VERSION ""

NS_ :

BS_:

BU_: L_DHRR_FD L_UWB_BLE_MST_FD L_UWB_RR_FD L_UWB_BLE_SLV_FD L_UWB_FR_FD L_ROA_FR_FD L_ROA_FD L_DHRL_FD L_UWB_TRNK_FD L_EDT_FD L_UWB_FRNK_FD L_UWB_FL_FD GW_BDC_FD L_UWB_RL_FD L_SAL_FD L_WPC_FD L_TPMS_FD L_DHL_FD L_DHR_FD

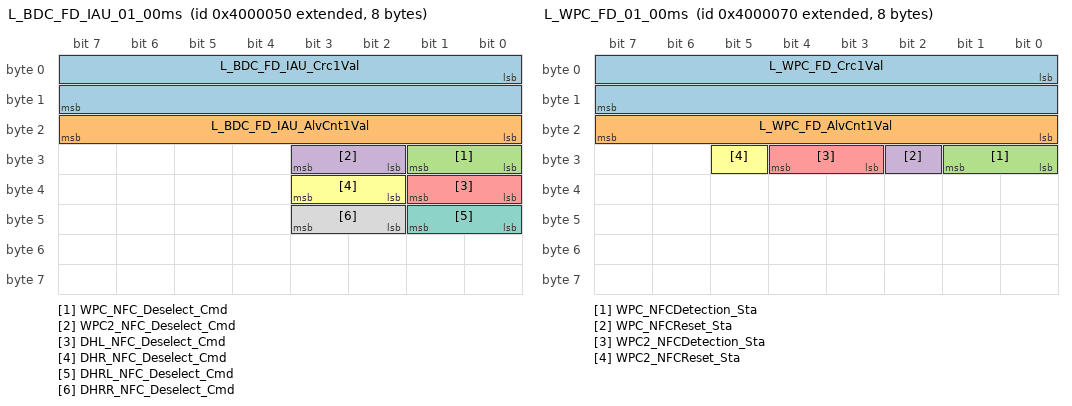
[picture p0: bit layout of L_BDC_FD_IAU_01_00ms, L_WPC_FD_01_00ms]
BO_ 2214592592 L_BDC_FD_IAU_01_00ms: 8 GW_BDC_FD
 SG_ L_BDC_FD_IAU_Crc1Val : 0|16@1+ (1,0) [0|0] "0"  Vector__XXX
 SG_ L_BDC_FD_IAU_AlvCnt1Val : 16|8@1+ (1,0) [0|0] "0"  Vector__XXX
 SG_ WPC_NFC_Deselect_Cmd : 24|2@1+ (1,0) [0|0] ""  L_WPC_FD
 SG_ WPC2_NFC_Deselect_Cmd : 26|2@1+ (1,0) [0|0] ""  L_WPC_FD
 SG_ DHL_NFC_Deselect_Cmd : 32|2@1+ (1,0) [0|0] ""  L_DHL_FD
 SG_ DHR_NFC_Deselect_Cmd : 34|2@1+ (1,0) [0|0] ""  L_DHR_FD
 SG_ DHRL_NFC_Deselect_Cmd : 40|2@1+ (1,0) [0|0] ""  L_DHRL_FD
 SG_ DHRR_NFC_Deselect_Cmd : 42|2@1+ (1,0) [0|0] ""  L_DHRR_FD

BO_ 850 IAU_FD_05_200ms: 32 GW_BDC_FD
 SG_ IAU_FD_Crc5Val : 0|16@1+ (1,0) [0|0] ""  Vector__XXX
 SG_ IAU_DigitalKeyProfileRval : 112|4@1+ (1,0) [0|0] ""  Vector__XXX
 SG_ IAU_SharedPhnRegStat : 116|2@1+ (1,0) [0|0] ""  L_DHL_FD,L_DHRL_FD,L_DHRR_FD,L_DHR_FD,L_UWB_BLE_MST_FD,L_UWB_BLE_SLV_FD,L_UWB_FL_FD,L_UWB_FRNK_FD,L_UWB_FR_FD,L_UWB_RL_FD,L_UWB_RR_FD,L_UWB_TRNK_FD,L_WPC_FD
 SG_ IAU_CardKeyEnblRVal : 118|2@1+ (1,0) [0|0] ""  L_DHL_FD,L_DHRL_FD,L_DHRR_FD,L_DHR_FD
 SG_ IAU_DrvDHLPhnDetect : 120|2@1+ (1,0) [0|0] ""  Vector__XXX
 SG_ IAU_AstDHLPhnDetect : 122|2@1+ (1,0) [0|0] ""  Vector__XXX
 SG_ IAU_RLDHLPhnDetect : 124|2@1+ (1,0) [0|0] ""  Vector__XXX
 SG_ IAU_RRDHLPhnDetect : 126|2@1+ (1,0) [0|0] ""  Vector__XXX
 SG_ IAU_Manufacturer : 128|8@1+ (1,0) [0|0] ""  Vector__XXX
 SG_ IAU_VendorCode : 136|24@1+ (1,0) [0|0] ""  Vector__XXX
 SG_ IAU_FD_AlvCnt5Val : 16|8@1+ (1,0) [0|0] ""  Vector__XXX
 SG_ IAU_Serial : 160|32@1+ (1,0) [0|0] ""  Vector__XXX
 SG_ IAU_Year : 192|16@1+ (1,0) [0|0] ""  Vector__XXX
 SG_ IAU_Month : 208|8@1+ (1,0) [0|0] ""  Vector__XXX
 SG_ IAU_Date : 216|16@1+ (1,0) [0|0] ""  Vector__XXX
 SG_ IAU_SWVerMajor1 : 232|7@1+ (1,0) [0|0] ""  Vector__XXX
 SG_ IAU_DrvDhsRainStat : 24|1@1+ (1,0) [0|0] ""  Vector__XXX
 SG_ IAU_SWVerMinor1 : 240|7@1+ (1,0) [0|0] ""  Vector__XXX
 SG_ IAU_SWVerMinor2 : 248|7@1+ (1,0) [0|0] ""  Vector__XXX
 SG_ IAU_AstDhsRainStat : 25|1@1+ (1,0) [0|0] ""  Vector__XXX
 SG_ IAU_RLDhsRainStat : 26|1@1+ (1,0) [0|0] ""  Vector__XXX
 SG_ IAU_RRDhsRainStat : 27|1@1+ (1,0) [0|0] ""  Vector__XXX

BO_ 745 PDC_FD_15_300ms: 32 GW_BDC_FD
 SG_ PDC_FD_Crc15Val : 0|16@1+ (1,0) [0|0] ""  L_DHL_FD,L_DHRL_FD,L_DHRR_FD,L_DHR_FD,L_EDT_FD,L_ROA_FD,L_ROA_FR_FD,L_SAL_FD,L_TPMS_FD,L_UWB_BLE_MST_FD,L_UWB_BLE_SLV_FD,L_UWB_FL_FD,L_UWB_FRNK_FD,L_UWB_FR_FD,L_UWB_RL_FD,L_UWB_RR_FD,L_UWB_TRNK_FD,L_WPC_FD
 SG_ PDC_CurrAtReset : 104|12@1+ (10,-40940) [-40940|0] "mA"  Vector__XXX
 SG_ PDC_AvgCurrAtReset : 120|12@1+ (10,-40940) [-40940|0] "mA"  Vector__XXX
 SG_ PDC_ResetReason : 132|3@1+ (1,0) [0|0] ""  Vector__XXX
 SG_ PDC_CumulativeCountOf12VReq : 136|10@1+ (1,0) [0|0] ""  Vector__XXX
 SG_ PDC_CumulativeCountOfCCUReq : 146|10@1+ (1,0) [0|0] ""  Vector__XXX
 SG_ PDC_FD_AlvCnt15Val : 16|8@1+ (1,0) [0|0] ""  L_DHL_FD,L_DHRL_FD,L_DHRR_FD,L_DHR_FD,L_EDT_FD,L_ROA_FD,L_ROA_FR_FD,L_SAL_FD,L_TPMS_FD,L_UWB_BLE_MST_FD,L_UWB_BLE_SLV_FD,L_UWB_FL_FD,L_UWB_FRNK_FD,L_UWB_FR_FD,L_UWB_RL_FD,L_UWB_RR_FD,L_UWB_TRNK_FD,L_WPC_FD
 SG_ PDC_LDConReq : 184|2@1+ (1,0) [0|0] ""  Vector__XXX
 SG_ PDC_LDConReq_By_LVBat : 186|2@1+ (1,0) [0|0] ""  Vector__XXX
 SG_ PDC_LDConReq_By_OTA : 188|2@1+ (1,0) [0|0] ""  Vector__XXX
 SG_ PDC_LDConReq_By_Load : 190|2@1+ (1,0) [0|0] ""  Vector__XXX
 SG_ PDC_LDConReq_By_ActiveOn : 192|2@1+ (1,0) [0|0] ""  Vector__XXX
 SG_ PDC_ResetPreWrngForCCU : 40|2@1+ (1,0) [0|0] ""  Vector__XXX
 SG_ PDC_ResetPreWrngForOthers : 42|2@1+ (1,0) [0|0] ""  L_DHL_FD,L_DHRL_FD,L_DHRR_FD,L_DHR_FD,L_EDT_FD,L_ROA_FD,L_ROA_FR_FD,L_SAL_FD,L_TPMS_FD,L_UWB_BLE_MST_FD,L_UWB_BLE_SLV_FD,L_UWB_FL_FD,L_UWB_FRNK_FD,L_UWB_FR_FD,L_UWB_RL_FD,L_UWB_RR_FD,L_UWB_TRNK_FD,L_WPC_FD
 SG_ PDC_ResetReqForCCU : 44|2@1+ (1,0) [0|0] ""  Vector__XXX
 SG_ PDC_ResetReqForOthers : 46|2@1+ (1,0) [0|0] ""  L_DHL_FD,L_DHRL_FD,L_DHRR_FD,L_DHR_FD,L_EDT_FD,L_ROA_FD,L_ROA_FR_FD,L_SAL_FD,L_TPMS_FD,L_UWB_BLE_MST_FD,L_UWB_BLE_SLV_FD,L_UWB_FL_FD,L_UWB_FRNK_FD,L_UWB_FR_FD,L_UWB_RL_FD,L_UWB_RR_FD,L_UWB_TRNK_FD,L_WPC_FD
 SG_ PDC_ResetFuncOpt : 48|2@1+ (1,0) [0|0] ""  L_ROA_FD,L_ROA_FR_FD,L_TPMS_FD,L_UWB_BLE_MST_FD,L_UWB_BLE_SLV_FD,L_UWB_FL_FD,L_UWB_FRNK_FD,L_UWB_FR_FD,L_UWB_RL_FD,L_UWB_RR_FD,L_UWB_TRNK_FD
 SG_ PDC_12VRlyCtrl : 50|2@1+ (1,0) [0|0] ""  Vector__XXX
 SG_ PDC_CurrentValueForReset : 52|8@1+ (50,0) [0|0] "mA"  Vector__XXX
 SG_ PDC_TimeValueForReset : 64|8@1+ (0.5,0) [0|0] "h"  Vector__XXX
 SG_ PDC_12VRlyOffHoldingTime : 72|5@1+ (0.5,0) [0|0] "s"  Vector__XXX
 SG_ PDC_ResetCountSetting : 77|2@1+ (1,0) [0|0] ""  Vector__XXX
 SG_ PDC_ResetCount : 79|2@1+ (1,0) [0|0] ""  Vector__XXX
 SG_ PDC_ResetCumulativeCount : 81|10@1+ (1,0) [0|0] ""  Vector__XXX
 SG_ PDC_ResetOpsta : 91|2@1+ (1,0) [0|0] ""  Vector__XXX
 SG_ PDC_ReadyTimeValueForReset : 96|8@1+ (10,0) [0|255] "Min"  Vector__XXX

BO_ 849 IAU_FD_04_200ms: 32 GW_BDC_FD
 SG_ IAU_FD_Crc4Val : 0|16@1+ (1,0) [0|0] "0"  Vector__XXX
 SG_ IAU_DISPWrng : 104|4@1+ (1,0) [0|0] ""  Vector__XXX
 SG_ IAU_DigitalKey2Opt : 120|3@1+ (1,0) [0|0] ""  Vector__XXX
 SG_ IAUwFRULearnState : 124|2@1+ (1,0) [0|0] ""  Vector__XXX
 SG_ IAUwFPMLearnState : 126|2@1+ (1,0) [0|0] ""  Vector__XXX
 SG_ IAU_ValetDigitalkey : 128|2@1+ (1,0) [0|0] ""  Vector__XXX
 SG_ IAU_DigitalKeyNumberOpt : 130|3@1+ (1,0) [0|0] ""  Vector__XXX
 SG_ IAU_eSEReprogramSta : 133|2@1+ (1,0) [0|0] ""  Vector__XXX
 SG_ IAU_DKOwnerSwapOption : 136|2@1+ (1,0) [0|0] ""  L_UWB_BLE_MST_FD,L_UWB_BLE_SLV_FD,L_UWB_FL_FD,L_UWB_FRNK_FD,L_UWB_FR_FD,L_UWB_RL_FD,L_UWB_RR_FD,L_UWB_TRNK_FD,L_WPC_FD
 SG_ IAU_DgtKeyGrpPrflRval2 : 139|5@1+ (1,0) [0|0] ""  Vector__XXX
 SG_ IAU_StartIdentifiedProfile : 144|3@1+ (1,0) [0|0] ""  Vector__XXX
 SG_ IAU_DigitalKeyProfileRval2 : 147|5@1+ (1,0) [0|0] ""  Vector__XXX
 SG_ IAU_NFCCard1SN : 152|32@1+ (1,0) [0|0] ""  Vector__XXX
 SG_ IAU_FD_AlvCnt4Val : 16|8@1+ (1,0) [0|0] "0"  Vector__XXX
 SG_ IAU_StartIdentifiedProfile_Ext : 24|4@1+ (1,0) [0|0] ""  Vector__XXX
 SG_ RSPA_UWBRspaExtRngSta : 246|2@1+ (1,0) [0|0] ""  Vector__XXX
 SG_ RSPA_CanFltSta : 250|2@1+ (1,0) [0|0] ""  Vector__XXX
 SG_ RSPA_BLESigErrSta : 252|2@1+ (1,0) [0|0] ""  Vector__XXX
 SG_ RSPA_ConStat : 254|2@1+ (1,0) [0|0] ""  Vector__XXX
 SG_ IAU_ProfileIDRVal : 74|4@1+ (1,0) [0|0] ""  Vector__XXX
 SG_ IAU_DigitalKeyProcessingSta : 80|4@1+ (1,0) [0|0] ""  Vector__XXX
 SG_ IAU_DigitalKeyExit : 84|4@1+ (1,0) [0|0] ""  Vector__XXX
 SG_ IAU_DigitalKeyEnblRVal : 88|2@1+ (1,0) [0|0] ""  L_DHL_FD,L_DHRL_FD,L_DHRR_FD,L_DHR_FD,L_UWB_BLE_MST_FD,L_UWB_BLE_SLV_FD,L_UWB_FL_FD,L_UWB_FRNK_FD,L_UWB_FR_FD,L_UWB_RL_FD,L_UWB_RR_FD,L_UWB_TRNK_FD
 SG_ IAU_OwnerPhnRegRVal : 90|2@1+ (1,0) [0|0] ""  L_DHL_FD,L_DHRL_FD,L_DHRR_FD,L_DHR_FD,L_UWB_BLE_MST_FD,L_UWB_BLE_SLV_FD,L_UWB_FL_FD,L_UWB_FRNK_FD,L_UWB_FR_FD,L_UWB_RL_FD,L_UWB_RR_FD,L_UWB_TRNK_FD,L_WPC_FD
 SG_ IAU_NFCCard1RegRVal : 92|2@1+ (1,0) [0|0] ""  Vector__XXX
 SG_ IAU_NFCCard2RegRVal : 94|2@1+ (1,0) [0|0] ""  Vector__XXX

BO_ 2214592624 L_WPC_FD_01_00ms: 8 L_WPC_FD
 SG_ L_WPC_FD_Crc1Val : 0|16@1+ (1,0) [0|0] "0"  Vector__XXX
 SG_ L_WPC_FD_AlvCnt1Val : 16|8@1+ (1,0) [0|0] "0"  Vector__XXX
 SG_ WPC_NFCDetection_Sta : 24|2@1+ (1,0) [0|0] ""  GW_BDC_FD
 SG_ WPC_NFCReset_Sta : 26|1@1+ (1,0) [0|0] ""  GW_BDC_FD
 SG_ WPC2_NFCDetection_Sta : 27|2@1+ (1,0) [0|0] ""  GW_BDC_FD
 SG_ WPC2_NFCReset_Sta : 29|1@1+ (1,0) [0|0] ""  GW_BDC_FD

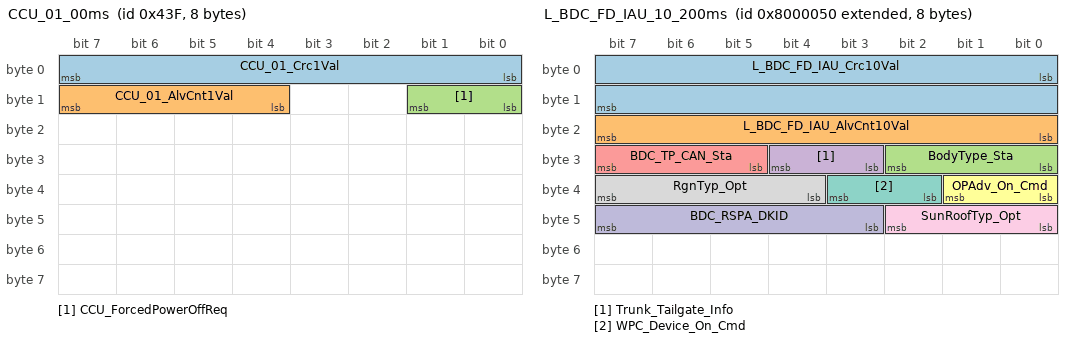
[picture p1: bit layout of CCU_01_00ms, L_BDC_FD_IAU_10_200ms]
BO_ 1087 CCU_01_00ms: 8 GW_BDC_FD
 SG_ CCU_01_Crc1Val : 0|8@1+ (1,0) [0|0] ""  Vector__XXX
 SG_ CCU_01_AlvCnt1Val : 12|4@1+ (1,0) [0|0] ""  Vector__XXX
 SG_ CCU_ForcedPowerOffReq : 8|2@1+ (1,0) [0|0] ""  L_DHL_FD,L_DHRL_FD,L_DHRR_FD,L_DHR_FD,L_ROA_FD,L_ROA_FR_FD,L_SAL_FD,L_TPMS_FD,L_UWB_BLE_MST_FD,L_UWB_BLE_SLV_FD,L_UWB_FL_FD,L_UWB_FRNK_FD,L_UWB_FR_FD,L_UWB_RL_FD,L_UWB_RR_FD,L_UWB_TRNK_FD,L_WPC_FD

BO_ 2348810501 L_TP_L_WPC_FD_BDC_FD: 32 L_WPC_FD
 SG_ L_TP_L_WPC_FD_BDC_FD_Byte0 : 0|8@1+ (1,0) [0|0] ""  GW_BDC_FD
 SG_ L_TP_L_WPC_FD_BDC_FD_Byte13 : 104|8@1+ (1,0) [0|0] ""  GW_BDC_FD
 SG_ L_TP_L_WPC_FD_BDC_FD_Byte14 : 112|8@1+ (1,0) [0|0] ""  GW_BDC_FD
 SG_ L_TP_L_WPC_FD_BDC_FD_Byte15 : 120|8@1+ (1,0) [0|0] ""  GW_BDC_FD
 SG_ L_TP_L_WPC_FD_BDC_FD_Byte16 : 128|8@1+ (1,0) [0|0] ""  GW_BDC_FD
 SG_ L_TP_L_WPC_FD_BDC_FD_Byte17 : 136|8@1+ (1,0) [0|0] ""  GW_BDC_FD
 SG_ L_TP_L_WPC_FD_BDC_FD_Byte18 : 144|8@1+ (1,0) [0|0] ""  GW_BDC_FD
 SG_ L_TP_L_WPC_FD_BDC_FD_Byte19 : 152|8@1+ (1,0) [0|0] ""  GW_BDC_FD
 SG_ L_TP_L_WPC_FD_BDC_FD_Byte2 : 16|8@1+ (1,0) [0|0] ""  GW_BDC_FD
 SG_ L_TP_L_WPC_FD_BDC_FD_Byte20 : 160|8@1+ (1,0) [0|0] ""  GW_BDC_FD
 SG_ L_TP_L_WPC_FD_BDC_FD_Byte21 : 168|8@1+ (1,0) [0|0] ""  GW_BDC_FD
 SG_ L_TP_L_WPC_FD_BDC_FD_Byte22 : 176|8@1+ (1,0) [0|0] ""  GW_BDC_FD
 SG_ L_TP_L_WPC_FD_BDC_FD_Byte23 : 184|8@1+ (1,0) [0|0] ""  GW_BDC_FD
 SG_ L_TP_L_WPC_FD_BDC_FD_Byte24 : 192|8@1+ (1,0) [0|0] ""  GW_BDC_FD
 SG_ L_TP_L_WPC_FD_BDC_FD_Byte25 : 200|8@1+ (1,0) [0|0] ""  GW_BDC_FD
 SG_ L_TP_L_WPC_FD_BDC_FD_Byte26 : 208|8@1+ (1,0) [0|0] ""  GW_BDC_FD
 SG_ L_TP_L_WPC_FD_BDC_FD_Byte27 : 216|8@1+ (1,0) [0|0] ""  GW_BDC_FD
 SG_ L_TP_L_WPC_FD_BDC_FD_Byte28 : 224|8@1+ (1,0) [0|0] ""  GW_BDC_FD
 SG_ L_TP_L_WPC_FD_BDC_FD_Byte29 : 232|8@1+ (1,0) [0|0] ""  GW_BDC_FD
 SG_ L_TP_L_WPC_FD_BDC_FD_Byte3 : 24|8@1+ (1,0) [0|0] ""  GW_BDC_FD
 SG_ L_TP_L_WPC_FD_BDC_FD_Byte30 : 240|8@1+ (1,0) [0|0] ""  GW_BDC_FD
 SG_ L_TP_L_WPC_FD_BDC_FD_Byte31 : 248|8@1+ (1,0) [0|0] ""  GW_BDC_FD
 SG_ L_TP_L_WPC_FD_BDC_FD_Byte4 : 32|8@1+ (1,0) [0|0] ""  GW_BDC_FD
 SG_ L_TP_L_WPC_FD_BDC_FD_Byte5 : 40|8@1+ (1,0) [0|0] ""  GW_BDC_FD
 SG_ L_TP_L_WPC_FD_BDC_FD_Byte6 : 48|8@1+ (1,0) [0|0] ""  GW_BDC_FD
 SG_ L_TP_L_WPC_FD_BDC_FD_Byte7 : 56|8@1+ (1,0) [0|0] ""  GW_BDC_FD
 SG_ L_TP_L_WPC_FD_BDC_FD_Byte8 : 64|8@1+ (1,0) [0|0] ""  GW_BDC_FD
 SG_ L_TP_L_WPC_FD_BDC_FD_Byte9 : 72|8@1+ (1,0) [0|0] ""  GW_BDC_FD
 SG_ L_TP_L_WPC_FD_BDC_FD_Byte1 : 8|8@1+ (1,0) [0|0] ""  GW_BDC_FD
 SG_ L_TP_L_WPC_FD_BDC_FD_Byte10 : 80|8@1+ (1,0) [0|0] ""  GW_BDC_FD
 SG_ L_TP_L_WPC_FD_BDC_FD_Byte11 : 88|8@1+ (1,0) [0|0] ""  GW_BDC_FD
 SG_ L_TP_L_WPC_FD_BDC_FD_Byte12 : 96|8@1+ (1,0) [0|0] ""  GW_BDC_FD

BO_ 2348810500 L_TP_BDC_FD_L_WPC_FD: 32 GW_BDC_FD
 SG_ L_TP_BDC_FD_L_WPC_FD_Byte0 : 0|8@1+ (1,0) [0|0] ""  L_WPC_FD
 SG_ L_TP_BDC_FD_L_WPC_FD_Byte13 : 104|8@1+ (1,0) [0|0] ""  L_WPC_FD
 SG_ L_TP_BDC_FD_L_WPC_FD_Byte14 : 112|8@1+ (1,0) [0|0] ""  L_WPC_FD
 SG_ L_TP_BDC_FD_L_WPC_FD_Byte15 : 120|8@1+ (1,0) [0|0] ""  L_WPC_FD
 SG_ L_TP_BDC_FD_L_WPC_FD_Byte16 : 128|8@1+ (1,0) [0|0] ""  L_WPC_FD
 SG_ L_TP_BDC_FD_L_WPC_FD_Byte17 : 136|8@1+ (1,0) [0|0] ""  L_WPC_FD
 SG_ L_TP_BDC_FD_L_WPC_FD_Byte18 : 144|8@1+ (1,0) [0|0] ""  L_WPC_FD
 SG_ L_TP_BDC_FD_L_WPC_FD_Byte19 : 152|8@1+ (1,0) [0|0] ""  L_WPC_FD
 SG_ L_TP_BDC_FD_L_WPC_FD_Byte2 : 16|8@1+ (1,0) [0|0] ""  L_WPC_FD
 SG_ L_TP_BDC_FD_L_WPC_FD_Byte20 : 160|8@1+ (1,0) [0|0] ""  L_WPC_FD
 SG_ L_TP_BDC_FD_L_WPC_FD_Byte21 : 168|8@1+ (1,0) [0|0] ""  L_WPC_FD
 SG_ L_TP_BDC_FD_L_WPC_FD_Byte22 : 176|8@1+ (1,0) [0|0] ""  L_WPC_FD
 SG_ L_TP_BDC_FD_L_WPC_FD_Byte23 : 184|8@1+ (1,0) [0|0] ""  L_WPC_FD
 SG_ L_TP_BDC_FD_L_WPC_FD_Byte24 : 192|8@1+ (1,0) [0|0] ""  L_WPC_FD
 SG_ L_TP_BDC_FD_L_WPC_FD_Byte25 : 200|8@1+ (1,0) [0|0] ""  L_WPC_FD
 SG_ L_TP_BDC_FD_L_WPC_FD_Byte26 : 208|8@1+ (1,0) [0|0] ""  L_WPC_FD
 SG_ L_TP_BDC_FD_L_WPC_FD_Byte27 : 216|8@1+ (1,0) [0|0] ""  L_WPC_FD
 SG_ L_TP_BDC_FD_L_WPC_FD_Byte28 : 224|8@1+ (1,0) [0|0] ""  L_WPC_FD
 SG_ L_TP_BDC_FD_L_WPC_FD_Byte29 : 232|8@1+ (1,0) [0|0] ""  L_WPC_FD
 SG_ L_TP_BDC_FD_L_WPC_FD_Byte3 : 24|8@1+ (1,0) [0|0] ""  L_WPC_FD
 SG_ L_TP_BDC_FD_L_WPC_FD_Byte30 : 240|8@1+ (1,0) [0|0] ""  L_WPC_FD
 SG_ L_TP_BDC_FD_L_WPC_FD_Byte31 : 248|8@1+ (1,0) [0|0] ""  L_WPC_FD
 SG_ L_TP_BDC_FD_L_WPC_FD_Byte4 : 32|8@1+ (1,0) [0|0] ""  L_WPC_FD
 SG_ L_TP_BDC_FD_L_WPC_FD_Byte5 : 40|8@1+ (1,0) [0|0] ""  L_WPC_FD
 SG_ L_TP_BDC_FD_L_WPC_FD_Byte6 : 48|8@1+ (1,0) [0|0] ""  L_WPC_FD
 SG_ L_TP_BDC_FD_L_WPC_FD_Byte7 : 56|8@1+ (1,0) [0|0] ""  L_WPC_FD
 SG_ L_TP_BDC_FD_L_WPC_FD_Byte8 : 64|8@1+ (1,0) [0|0] ""  L_WPC_FD
 SG_ L_TP_BDC_FD_L_WPC_FD_Byte9 : 72|8@1+ (1,0) [0|0] ""  L_WPC_FD
 SG_ L_TP_BDC_FD_L_WPC_FD_Byte1 : 8|8@1+ (1,0) [0|0] ""  L_WPC_FD
 SG_ L_TP_BDC_FD_L_WPC_FD_Byte10 : 80|8@1+ (1,0) [0|0] ""  L_WPC_FD
 SG_ L_TP_BDC_FD_L_WPC_FD_Byte11 : 88|8@1+ (1,0) [0|0] ""  L_WPC_FD
 SG_ L_TP_BDC_FD_L_WPC_FD_Byte12 : 96|8@1+ (1,0) [0|0] ""  L_WPC_FD

BO_ 2281701456 L_BDC_FD_IAU_10_200ms: 8 GW_BDC_FD
 SG_ L_BDC_FD_IAU_Crc10Val : 0|16@1+ (1,0) [0|0] "0"  Vector__XXX
 SG_ L_BDC_FD_IAU_AlvCnt10Val : 16|8@1+ (1,0) [0|0] "0"  Vector__XXX
 SG_ BodyType_Sta : 24|3@1+ (1,0) [0|0] ""  L_ROA_FD,L_ROA_FR_FD,L_UWB_BLE_MST_FD
 SG_ Trunk_Tailgate_Info : 27|2@1+ (1,0) [0|0] ""  L_UWB_BLE_MST_FD
 SG_ BDC_TP_CAN_Sta : 29|3@1+ (1,0) [0|0] ""  L_DHL_FD,L_DHRL_FD,L_DHRR_FD,L_DHR_FD,L_UWB_BLE_MST_FD,L_UWB_BLE_SLV_FD,L_UWB_FL_FD,L_UWB_FRNK_FD,L_UWB_FR_FD,L_UWB_RL_FD,L_UWB_RR_FD,L_UWB_TRNK_FD,L_WPC_FD
 SG_ OPAdv_On_Cmd : 32|2@1+ (1,0) [0|0] ""  L_UWB_BLE_MST_FD,L_UWB_BLE_SLV_FD,L_WPC_FD
 SG_ WPC_Device_On_Cmd : 34|2@1+ (1,0) [0|0] ""  L_WPC_FD
 SG_ RgnTyp_Opt : 36|4@1+ (1,0) [0|0] ""  L_ROA_FD,L_ROA_FR_FD,L_UWB_BLE_MST_FD,L_UWB_BLE_SLV_FD
 SG_ SunRoofTyp_Opt : 40|3@1+ (1,0) [0|0] ""  L_ROA_FD,L_ROA_FR_FD,L_UWB_BLE_MST_FD
 SG_ BDC_RSPA_DKID : 43|5@1+ (1,0) [0|0] ""  L_UWB_BLE_MST_FD,L_UWB_BLE_SLV_FD

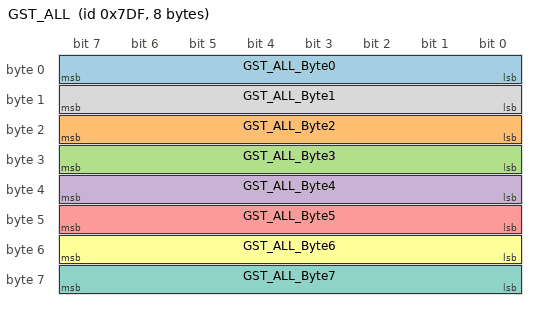
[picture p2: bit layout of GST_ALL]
BO_ 2015 GST_ALL: 8 GW_BDC_FD
 SG_ GST_ALL_Byte0 : 0|8@1+ (1,0) [0|0] ""  L_DHL_FD,L_DHRL_FD,L_DHRR_FD,L_DHR_FD,L_ROA_FD,L_ROA_FR_FD,L_SAL_FD,L_UWB_BLE_MST_FD,L_WPC_FD
 SG_ GST_ALL_Byte2 : 16|8@1+ (1,0) [0|0] ""  L_DHL_FD,L_DHRL_FD,L_DHRR_FD,L_DHR_FD,L_ROA_FD,L_ROA_FR_FD,L_SAL_FD,L_UWB_BLE_MST_FD,L_WPC_FD
 SG_ GST_ALL_Byte3 : 24|8@1+ (1,0) [0|0] ""  L_DHL_FD,L_DHRL_FD,L_DHRR_FD,L_DHR_FD,L_ROA_FD,L_ROA_FR_FD,L_SAL_FD,L_UWB_BLE_MST_FD,L_WPC_FD
 SG_ GST_ALL_Byte4 : 32|8@1+ (1,0) [0|0] ""  L_DHL_FD,L_DHRL_FD,L_DHRR_FD,L_DHR_FD,L_ROA_FD,L_ROA_FR_FD,L_SAL_FD,L_UWB_BLE_MST_FD,L_WPC_FD
 SG_ GST_ALL_Byte5 : 40|8@1+ (1,0) [0|0] ""  L_DHL_FD,L_DHRL_FD,L_DHRR_FD,L_DHR_FD,L_ROA_FD,L_ROA_FR_FD,L_SAL_FD,L_UWB_BLE_MST_FD,L_WPC_FD
 SG_ GST_ALL_Byte6 : 48|8@1+ (1,0) [0|0] ""  L_DHL_FD,L_DHRL_FD,L_DHRR_FD,L_DHR_FD,L_ROA_FD,L_ROA_FR_FD,L_SAL_FD,L_UWB_BLE_MST_FD,L_WPC_FD
 SG_ GST_ALL_Byte7 : 56|8@1+ (1,0) [0|0] ""  L_DHL_FD,L_DHRL_FD,L_DHRR_FD,L_DHR_FD,L_ROA_FD,L_ROA_FR_FD,L_SAL_FD,L_UWB_BLE_MST_FD,L_WPC_FD
 SG_ GST_ALL_Byte1 : 8|8@1+ (1,0) [0|0] ""  L_DHL_FD,L_DHRL_FD,L_DHRR_FD,L_DHR_FD,L_ROA_FD,L_ROA_FR_FD,L_SAL_FD,L_UWB_BLE_MST_FD,L_WPC_FD

CM_ BO_ 1087 "[EC] On Event and On Change";
CM_ SG_ 1087 CCU_01_Crc1Val "CCU_01_CyclicRedundancyCheck1Value";
CM_ SG_ 1087 CCU_01_AlvCnt1Val "CCU_01_AliveCounter1Value";
CM_ SG_ 1087 CCU_ForcedPowerOffReq "CCU sends this signal to ICU for  the power off logic according to the conditions(vehicle normal mode/there are non-sleep ECUs in 1 hour/all ECUs go into the sleep mode)";
CM_ BO_ 2015 "[TP] Transport Protocol";
CM_ BO_ 849 "[PE] Periodic and On Event";
CM_ SG_ 849 IAU_FD_Crc4Val "IAU_FD_CyclicRedundancyCheck4Value";
CM_ SG_ 849 IAU_DigitalKey2Opt "Digital Key2 Option Signal";
CM_ SG_ 849 IAU_ValetDigitalkey "Digital Key Valet Mode";
CM_ SG_ 849 IAU_DigitalKeyNumberOpt "This signal is for the digital key number type.";
CM_ SG_ 849 IAU_eSEReprogramSta "this signal is to mornitor the state of eSE reprograming.";
CM_ SG_ 849 IAU_DgtKeyGrpPrflRval2 "This signal indiactes digital key group number paired with selected profile";
CM_ SG_ 849 IAU_StartIdentifiedProfile "This signal Indicate Profile of vehicle start Identified";
CM_ SG_ 849 IAU_DigitalKeyProfileRval2 "This signal indiactes digital key number paired with selected profile";
CM_ SG_ 849 IAU_FD_AlvCnt4Val "IAU_FD_AliveCounter4Value";
CM_ SG_ 849 IAU_StartIdentifiedProfile_Ext "This signal indicate Profile of vehicle start Identified";
CM_ SG_ 849 RSPA_UWBRspaExtRngSta "RSPA remote control range of UWB";
CM_ SG_ 849 RSPA_CanFltSta "RSPA_CANErrorState";
CM_ SG_ 849 RSPA_BLESigErrSta "RSPA_RFSignalErrorState";
CM_ SG_ 849 IAU_ProfileIDRVal "This signal Indicate the Current detected Profile ID by IAU.";
CM_ SG_ 849 IAU_DigitalKeyProcessingSta "Digital Key USM settitng Process State";
CM_ SG_ 849 IAU_DigitalKeyExit "Digital Key USM setting Exit Condition";
CM_ SG_ 849 IAU_DigitalKeyEnblRVal "Digital Key Function Enable / Disable flag (Fob is required for changing flag)";
CM_ SG_ 849 IAU_OwnerPhnRegRVal "Vehicle Owner's Phone is Registered for Digital Key function";
CM_ SG_ 849 IAU_NFCCard1RegRVal "NFC Card 1 is Registered for Digital Key function";
CM_ SG_ 849 IAU_NFCCard2RegRVal "NFC Card 2 is Registered for Digital Key function";
CM_ BO_ 850 "[PE] Periodic and On Event";
CM_ SG_ 850 IAU_FD_Crc5Val "IAU_FD_CyclicRedundancyCheck5Value";
CM_ SG_ 850 IAU_DigitalKeyProfileRval "This signal indiactes digital key number paired with selected profile";
CM_ SG_ 850 IAU_CardKeyEnblRVal "Card Key Function Enable / Disable flag (Fob is required for changing flag)";
CM_ SG_ 850 IAU_FD_AlvCnt5Val "IAU_FD_AliveCounter5Value";
CM_ SG_ 850 IAU_SWVerMajor1 "First Word(ASCII) in IAU S/W Ver";
CM_ SG_ 850 IAU_SWVerMinor1 "Second Word(ASCII) in IAU S/W Ver";
CM_ SG_ 850 IAU_SWVerMinor2 "Third Word(ASCII) in IAU S/W Ver";
CM_ BO_ 2214592592 "[EC] On Event and On Change";
CM_ SG_ 2214592592 L_BDC_FD_IAU_Crc1Val "L_BDC_FD_IAU_CyclicRedundancyCheck1Value";
CM_ SG_ 2214592592 L_BDC_FD_IAU_AlvCnt1Val "L_BDC_FD_IAU_AliveCounter1Value";
CM_ SG_ 2214592592 WPC_NFC_Deselect_Cmd "NFC Searchig Start/Stop command to WPC";
CM_ SG_ 2214592592 WPC2_NFC_Deselect_Cmd "NFC Searchig Start/Stop command to WPC#2";
CM_ SG_ 2214592592 DHL_NFC_Deselect_Cmd "NFC Searchig Start/Stop command to DHL";
CM_ SG_ 2214592592 DHR_NFC_Deselect_Cmd "NFC Searchig Start/Stop command to DHR";
CM_ SG_ 2214592592 DHRL_NFC_Deselect_Cmd "NFC Searchig Start/Stop command to DHRL";
CM_ SG_ 2214592592 DHRR_NFC_Deselect_Cmd "NFC Searchig Start/Stop command to DHRR";
CM_ BO_ 2281701456 "[PE] Periodic and On Event";
CM_ SG_ 2281701456 L_BDC_FD_IAU_Crc10Val "L_BDC_FD_IAU_CyclicRedundancyCheck10Value";
CM_ SG_ 2281701456 L_BDC_FD_IAU_AlvCnt10Val "L_BDC_FD_IAU_AliveCounter10Value";
CM_ SG_ 2281701456 BodyType_Sta "Body & Bumper type Status";
CM_ SG_ 2281701456 Trunk_Tailgate_Info "Trunk and Tailgate Type";
CM_ SG_ 2281701456 BDC_TP_CAN_Sta "BDC Processing Status";
CM_ SG_ 2281701456 OPAdv_On_Cmd "BLE Owner Pairing Advertising Reqeust";
CM_ SG_ 2281701456 WPC_Device_On_Cmd "Inform device on WPC";
CM_ SG_ 2281701456 RgnTyp_Opt "BDC EOL Region Type Option";
CM_ SG_ 2281701456 SunRoofTyp_Opt "BDC EOL Sunroof Type Option";
CM_ BO_ 2348810500 "[TP] Transport Protocol";
CM_ BO_ 2348810501 "[TP] Transport Protocol";
CM_ BO_ 2214592624 "[EC] On Event and On Change";
CM_ SG_ 2214592624 L_WPC_FD_Crc1Val "L_WPC_FD_CyclicRedundancyCheck1Value";
CM_ SG_ 2214592624 L_WPC_FD_AlvCnt1Val "L_WPC_FD_AliveCounter1Value";
CM_ SG_ 2214592624 WPC_NFCDetection_Sta "Indicate NFC Device is detected or not";
CM_ SG_ 2214592624 WPC_NFCReset_Sta "NFC Deselect Result";
CM_ SG_ 2214592624 WPC2_NFCDetection_Sta "Indicate NFC Device of WPC2 is detected or not  in Dual WPC";
CM_ SG_ 2214592624 WPC2_NFCReset_Sta "NFC Deselect Result of WPC2 in DUAL WPC";
CM_ BO_ 745 "[PE] Periodic and On Event";
CM_ SG_ 745 PDC_FD_Crc15Val "PDC_FD_CyclicRedundancyCheck15Value";
CM_ SG_ 745 PDC_CurrAtReset "This signal indicate the current at reset request";
CM_ SG_ 745 PDC_AvgCurrAtReset "This signal indicate the average current at reset request";
CM_ SG_ 745 PDC_ResetReason "This signal indicate the reason reset is operated";
CM_ SG_ 745 PDC_CumulativeCountOf12VReq "This signal indicates the cumulative number of 12V Controller req.";
CM_ SG_ 745 PDC_CumulativeCountOfCCUReq "This signal indicates the cumulative number of CCU_ForcedPowerOffReq";
CM_ SG_ 745 PDC_FD_AlvCnt15Val "PDC_FD_AliveCounter15Value";
CM_ SG_ 745 PDC_LDConReq "LDC on request signal for High Voltage Battery Discharge";
CM_ SG_ 745 PDC_LDConReq_By_LVBat "LDC on request signal for High Voltage Battery Discharge by Low Voltage Battery";
CM_ SG_ 745 PDC_LDConReq_By_OTA "LDC on request signal for High Voltage Battery Discharge by OTA";
CM_ SG_ 745 PDC_LDConReq_By_Load "LDC on request signal for High Voltage Battery Discharge by Load";
CM_ SG_ 745 PDC_LDConReq_By_ActiveOn "LDC on request signal for High Voltage Battery Discharge by Active On";
CM_ SG_ 745 PDC_ResetPreWrngForCCU "This is a warning signal for reset.  This signal is used for preparing sideeffect of reset by Gateway";
CM_ SG_ 745 PDC_ResetPreWrngForOthers "This is a warning signal for reset.  This signal is used for preparing sideeffect of reset by Receivers";
CM_ SG_ 745 PDC_ResetReqForCCU "This is a request signal for SW reset of Gateway";
CM_ SG_ 745 PDC_ResetReqForOthers "This is a request signal for SW reset except for Gateway";
CM_ SG_ 745 PDC_ResetFuncOpt "This signal inform whether reset fucntion at PDC is appiled or not";
CM_ SG_ 745 PDC_12VRlyCtrl "This signal is request signal to control 12V battery internal relay for HW reset";
CM_ SG_ 745 PDC_CurrentValueForReset "This signal sets the average discharge current value to be measured for PDC_TimevalueForReset to be considered as a situation requiring reset.";
CM_ SG_ 745 PDC_TimeValueForReset "This signal sets the time value to be considered as a situation requiring reset.";
CM_ SG_ 745 PDC_12VRlyOffHoldingTime "This signal sets how long the relay will be turned off when performing an HW reset using a 12 V battery internal relay.";
CM_ SG_ 745 PDC_ResetCountSetting "This signal sets the number of resets performed.";
CM_ SG_ 745 PDC_ResetCount "This signal indicates how much reset has occurred.";
CM_ SG_ 745 PDC_ResetCumulativeCount "This signal indicates the cumulative number of resets performed.";
CM_ SG_ 745 PDC_ResetOpsta "This signal indicates whether the reset operation has been completed or not";
CM_ SG_ 745 PDC_ReadyTimeValueForReset "This signal sets the time value to be considered as a situation of quiescent current";
BA_DEF_ BO_ "CANFD_BRS" ENUM "0","1" ;
BA_DEF_ BO_ "GenMsgEVName" STRING ;
BA_DEF_ BU_ "NmAsrNodeIdentifier" HEX 0 255 ;
BA_DEF_ BU_ "NmAsrCanMsgReducedTime" INT 0 1000 ;
BA_DEF_ "NmAsrWaitBusSleepTime" INT 0 100000 ;
BA_DEF_ "NmAsrTimeoutTime" INT 0 100000 ;
BA_DEF_ "NmAsrRepeatMessageTime" INT 0 100000 ;
BA_DEF_ "NmAsrMessageCount" INT 0 255 ;
BA_DEF_ "NmAsrCanMsgCycleTime" INT 0 100 ;
BA_DEF_ "NmAsrBaseAddress" HEX 0 536870911 ;
BA_DEF_ BO_ "NmAsrMessage" ENUM "No","Yes" ;
BA_DEF_ BO_ "DiagState" ENUM "No","Yes" ;
BA_DEF_ BO_ "TpMessage" ENUM "No","Yes" ;
BA_DEF_ BO_ "UsrMsgIDSforwardDeviation" INT 0 100 ;
BA_DEF_ BO_ "UsrMsgIDSbackwardDeviation" INT 50 1000 ;
BA_DEF_ "BusType" STRING ;
BA_DEF_ "DBName" STRING ;
BA_DEF_ "Baudrate" INT 50000 1000000 ;
BA_DEF_ "BRS" INT 0 1 ;
BA_DEF_ "GenEnvVarEndingDsp" STRING ;
BA_DEF_ "GenEnvVarEndingSnd" STRING ;
BA_DEF_ "GenEnvVarPrefix" STRING ;
BA_DEF_ "GenNWMApBusSleep" STRING ;
BA_DEF_ "GenNWMApCanNormal" STRING ;
BA_DEF_ "GenNWMApCanOff" STRING ;
BA_DEF_ "GenNWMApCanOn" STRING ;
BA_DEF_ "GenNWMApCanSleep" STRING ;
BA_DEF_ "GenNWMApCanWakeUp" STRING ;
BA_DEF_ "GenNWMGotoMode_Awake" STRING ;
BA_DEF_ "GenNWMGotoMode_BusSleep" STRING ;
BA_DEF_ "GenNWMSleepTime" INT 1375 1650 ;
BA_DEF_ "GenNWMTalkNM" STRING ;
BA_DEF_ "Manufacturer" STRING ;
BA_DEF_ "NmBaseAddress" HEX 0 2047 ;
BA_DEF_ "NmMessageCount" INT 0 128 ;
BA_DEF_ "NmType" STRING ;
BA_DEF_ "SamplePointMax" INT 50 85 ;
BA_DEF_ "SamplePointMin" INT 55 85 ;
BA_DEF_ "SyncJumpWidthMax" INT 1 8 ;
BA_DEF_ "SyncJumpWidthMin" INT 1 4 ;
BA_DEF_ "VersionDay" INT 1 31 ;
BA_DEF_ "VersionMonth" INT 1 12 ;
BA_DEF_ "VersionNumber" INT 0 999999 ;
BA_DEF_ "VersionNumberInternal" INT 0 9999 ;
BA_DEF_ "VersionWeek" INT 1 53 ;
BA_DEF_ "VersionYear" INT 0 9999 ;
BA_DEF_ BU_ "NmStationAddress" HEX 0 127 ;
BA_DEF_ BU_ "NmNode" ENUM "No","Yes" ;
BA_DEF_ BU_ "GenNodSleepTime" INT 1375 1650 ;
BA_DEF_ BU_ "ILUsed" ENUM "No","Yes" ;
BA_DEF_ BU_ "NmCAN" INT 1 2 ;
BA_DEF_ BU_ "NodeLayerModules" STRING ;
BA_DEF_ BU_ "NWM_Knoten" ENUM "No","Yes" ;
BA_DEF_ BO_ "GenMsgCycleTime" INT 0 2000 ;
BA_DEF_ BO_ "GenMsgStartDelayTime" INT 0 2000 ;
BA_DEF_ BO_ "GenMsgSendType" ENUM "Cyclic","NoMsgSendType" ;
BA_DEF_ BO_ "GenMsgCycleTimeFast" INT 0 500 ;
BA_DEF_ BO_ "GenMsgDelayTime" INT 0 20 ;
BA_DEF_ BO_ "GenMsgILSupport" ENUM "No","Yes" ;
BA_DEF_ BO_ "GenMsgNrOfRepetition" INT 0 3 ;
BA_DEF_ BO_ "TpTxIndex" INT 0 65535 ;
BA_DEF_ BO_ "VFrameFormat" ENUM "StandardCAN","ExtendedCAN","reserved","reserved","reserved","reserved","reserved","reserved","reserved","reserved","reserved","reserved","reserved","reserved","StandardCAN_FD","ExtendedCAN_FD" ;
BA_DEF_ SG_ "UserSigValidity" ENUM "B+","ACC","IG","IG1","IG2","IG3","IG1 or IG2","IG1 or IG3","Undef" ;
BA_DEF_ SG_ "TimeoutValue" STRING ;
BA_DEF_ SG_ "UsrSigPurpose" ENUM "Undef","FN","DIAG","DIAG(Req)","DIAG(Res)","DIAG(Func)","DEV","CCP","NM","TP" ;
BA_DEF_ SG_ "GenSigStartValue" INT 0 1215752192 ;
BA_DEF_ SG_ "NetworkRequest" ENUM "Yes","No" ;
BA_DEF_ SG_ "NetworkRequestHoldingTime" INT 0 65535 ;
BA_DEF_ SG_ "Description" STRING ;
BA_DEF_ SG_ "Version" STRING ;
BA_DEF_ SG_ "GenSigEnvVarType" ENUM "Int","Float","Undef" ;
BA_DEF_ SG_ "GenSigSendType" ENUM "Cyclic","OnWrite","OnWriteWithRepetition","OnChange","OnChangeWithRepetition","IfActive","IfActiveWithRepetition","NoSigSendType","OnChangeAndIfActive","OnChangeAndIfActiveWithRepetition" ;
BA_DEF_ SG_ "GwSigLatencyTime" INT 0 65536 ;
BA_DEF_ SG_ "GwSigMissingSourceType" ENUM "Undef","OldValue","DefaultValue","InitialValue" ;
BA_DEF_ SG_ "NWM-WakeupAllowed" ENUM "<n.a.>" ;
BA_DEF_ SG_ "RoutingFactor" INT 1 1215752192 ;
BA_DEF_ "Datarate" INT 1000000 8000000 ;
BA_DEF_REL_ BU_SG_REL_ "GenSigTimeoutTime" INT 0 7000 ;
BA_DEF_DEF_ "CANFD_BRS" "1" ;
BA_DEF_DEF_ "GenMsgEVName" "@Signame" ;
BA_DEF_DEF_ "NmAsrNodeIdentifier" 0 ;
BA_DEF_DEF_ "NmAsrCanMsgReducedTime" 1000 ;
BA_DEF_DEF_ "NmAsrWaitBusSleepTime" 1500 ;
BA_DEF_DEF_ "NmAsrTimeoutTime" 1000 ;
BA_DEF_DEF_ "NmAsrRepeatMessageTime" 1200 ;
BA_DEF_DEF_ "NmAsrMessageCount" 255 ;
BA_DEF_DEF_ "NmAsrCanMsgCycleTime" 100 ;
BA_DEF_DEF_ "NmAsrBaseAddress" 402391040 ;
BA_DEF_DEF_ "NmAsrMessage" "No" ;
BA_DEF_DEF_ "DiagState" "No" ;
BA_DEF_DEF_ "TpMessage" "No" ;
BA_DEF_DEF_ "UsrMsgIDSforwardDeviation" 10 ;
BA_DEF_DEF_ "UsrMsgIDSbackwardDeviation" 100 ;
BA_DEF_DEF_ "BusType" "CAN FD" ;
BA_DEF_DEF_ "DBName" "" ;
BA_DEF_DEF_ "Baudrate" 500000 ;
BA_DEF_DEF_ "BRS" 1 ;
BA_DEF_DEF_ "GenEnvVarEndingDsp" "Dsp_" ;
BA_DEF_DEF_ "GenEnvVarEndingSnd" "_" ;
BA_DEF_DEF_ "GenEnvVarPrefix" "Env" ;
BA_DEF_DEF_ "GenNWMApBusSleep" "AppNmCanBusSleep()" ;
BA_DEF_DEF_ "GenNWMApCanNormal" "AppNmCanNormal()" ;
BA_DEF_DEF_ "GenNWMApCanOff" "ApplCanOffline()" ;
BA_DEF_DEF_ "GenNWMApCanOn" "ApplCanOnline()" ;
BA_DEF_DEF_ "GenNWMApCanSleep" "ApplNmCanSleep()" ;
BA_DEF_DEF_ "GenNWMApCanWakeUp" "ApplCanWakeUp()" ;
BA_DEF_DEF_ "GenNWMGotoMode_Awake" "GotoMode_Awake()" ;
BA_DEF_DEF_ "GenNWMGotoMode_BusSleep" "GotoMode_BusSleep()" ;
BA_DEF_DEF_ "GenNWMSleepTime" 1500 ;
BA_DEF_DEF_ "GenNWMTalkNM" "TalkNM()" ;
BA_DEF_DEF_ "Manufacturer" "HMC" ;
BA_DEF_DEF_ "NmBaseAddress" 1280 ;
BA_DEF_DEF_ "NmMessageCount" 128 ;
BA_DEF_DEF_ "NmType" "AsrNm" ;
BA_DEF_DEF_ "SamplePointMax" 80 ;
BA_DEF_DEF_ "SamplePointMin" 80 ;
BA_DEF_DEF_ "SyncJumpWidthMax" 3 ;
BA_DEF_DEF_ "SyncJumpWidthMin" 2 ;
BA_DEF_DEF_ "VersionDay" 1 ;
BA_DEF_DEF_ "VersionMonth" 1 ;
BA_DEF_DEF_ "VersionNumber" 0 ;
BA_DEF_DEF_ "VersionNumberInternal" 0 ;
BA_DEF_DEF_ "VersionWeek" 1 ;
BA_DEF_DEF_ "VersionYear" 0 ;
BA_DEF_DEF_ "NmStationAddress" 0 ;
BA_DEF_DEF_ "NmNode" "No" ;
BA_DEF_DEF_ "GenNodSleepTime" 1500 ;
BA_DEF_DEF_ "ILUsed" "Yes" ;
BA_DEF_DEF_ "NmCAN" 1 ;
BA_DEF_DEF_ "NodeLayerModules" "AsrNM33.DLL,CANoeILNLVector.DLL" ;
BA_DEF_DEF_ "NWM_Knoten" "Yes" ;
BA_DEF_DEF_ "GenMsgCycleTime" 200 ;
BA_DEF_DEF_ "GenMsgStartDelayTime" 0 ;
BA_DEF_DEF_ "GenMsgSendType" "NoMsgSendType" ;
BA_DEF_DEF_ "GenMsgCycleTimeFast" 40 ;
BA_DEF_DEF_ "GenMsgDelayTime" 20 ;
BA_DEF_DEF_ "GenMsgILSupport" "Yes" ;
BA_DEF_DEF_ "GenMsgNrOfRepetition" 3 ;
BA_DEF_DEF_ "TpTxIndex" 0 ;
BA_DEF_DEF_ "VFrameFormat" "StandardCAN" ;
BA_DEF_DEF_ "UserSigValidity" "IG" ;
BA_DEF_DEF_ "TimeoutValue" "" ;
BA_DEF_DEF_ "UsrSigPurpose" "FN" ;
BA_DEF_DEF_ "GenSigStartValue" 0 ;
BA_DEF_DEF_ "NetworkRequest" "No" ;
BA_DEF_DEF_ "NetworkRequestHoldingTime" 0 ;
BA_DEF_DEF_ "Description" "" ;
BA_DEF_DEF_ "Version" "" ;
BA_DEF_DEF_ "GenSigEnvVarType" "Undef" ;
BA_DEF_DEF_ "GenSigSendType" "NoSigSendType" ;
BA_DEF_DEF_ "GwSigLatencyTime" 40 ;
BA_DEF_DEF_ "GwSigMissingSourceType" "Undef" ;
BA_DEF_DEF_ "NWM-WakeupAllowed" "<n.a.>" ;
BA_DEF_DEF_ "RoutingFactor" 1 ;
BA_DEF_DEF_ "Datarate" 1000000 ;
BA_DEF_DEF_REL_ "GenSigTimeoutTime" 500 ;
BA_ "DBName" "Local_FD_BDC";
BA_ "VersionYear" 1;
BA_ "VersionNumber" 240801;
BA_ "NmStationAddress" BU_ GW_BDC_FD 128;
BA_ "NmNode" BU_ GW_BDC_FD 1;
BA_ "GenMsgCycleTime" BO_ 1087 0;
BA_ "VFrameFormat" BO_ 1087 14;
BA_ "Description" SG_ 1087 CCU_01_Crc1Val "The data area for CRC calculation is based on the data length (DLC) of the message DB.

The CRC shall be calculated over the entire data block (excluding the CRC bytes) including the user data, alive counter and Data ID 

 

- CRC Polynomial (0x1D) , Initial Value : 0x00, XOR value : 0xFF, Data ID Mode : Both, Data ID : Message ID + 0xF800 

- The initial value is for CRC calculation and the message should be sent with the calculated result value. 

The mathematical expression to 8 bit CRC polynomial is given here. G(x) = x8 + x4 + x3 + x2 + 1";
BA_ "GenSigSendType" SG_ 1087 CCU_01_Crc1Val 4;
BA_ "UserSigValidity" SG_ 1087 CCU_01_Crc1Val 0;
BA_ "NetworkRequest" SG_ 1087 CCU_01_Crc1Val 0;
BA_ "NetworkRequestHoldingTime" SG_ 1087 CCU_01_Crc1Val 5000;
BA_ "Version" SG_ 1087 CCU_01_Crc1Val "21.09.03";
BA_ "Description" SG_ 1087 CCU_01_AlvCnt1Val "For the first transmission request for a data element the counter shall be initialized with 0 and shall be incremented by 1

for every subsequent send request. When the counter reaches the maximum value(0xE), then it shall restart with 0 for the next send request";
BA_ "GenSigSendType" SG_ 1087 CCU_01_AlvCnt1Val 4;
BA_ "UserSigValidity" SG_ 1087 CCU_01_AlvCnt1Val 0;
BA_ "NetworkRequest" SG_ 1087 CCU_01_AlvCnt1Val 0;
BA_ "NetworkRequestHoldingTime" SG_ 1087 CCU_01_AlvCnt1Val 5000;
BA_ "Version" SG_ 1087 CCU_01_AlvCnt1Val "21.09.03";
BA_ "NmStationAddress" BU_ L_DHL_FD 42;
BA_ "NmNode" BU_ L_DHL_FD 1;
BA_ "NmStationAddress" BU_ L_DHRL_FD 44;
BA_ "NmNode" BU_ L_DHRL_FD 1;
BA_ "NmStationAddress" BU_ L_DHRR_FD 45;
BA_ "NmNode" BU_ L_DHRR_FD 1;
BA_ "NmStationAddress" BU_ L_DHR_FD 43;
BA_ "NmNode" BU_ L_DHR_FD 1;
BA_ "NmStationAddress" BU_ L_SAL_FD 169;
BA_ "NmNode" BU_ L_SAL_FD 1;
BA_ "NmStationAddress" BU_ L_TPMS_FD 40;
BA_ "NmNode" BU_ L_TPMS_FD 1;
BA_ "NmStationAddress" BU_ L_UWB_BLE_MST_FD 32;
BA_ "NmNode" BU_ L_UWB_BLE_MST_FD 1;
BA_ "NmStationAddress" BU_ L_UWB_BLE_SLV_FD 33;
BA_ "NmNode" BU_ L_UWB_BLE_SLV_FD 1;
BA_ "NmStationAddress" BU_ L_UWB_FL_FD 34;
BA_ "NmNode" BU_ L_UWB_FL_FD 1;
BA_ "NmStationAddress" BU_ L_UWB_FRNK_FD 36;
BA_ "NmNode" BU_ L_UWB_FRNK_FD 1;
BA_ "NmStationAddress" BU_ L_UWB_FR_FD 35;
BA_ "NmNode" BU_ L_UWB_FR_FD 1;
BA_ "NmStationAddress" BU_ L_UWB_RL_FD 37;
BA_ "NmNode" BU_ L_UWB_RL_FD 1;
BA_ "NmStationAddress" BU_ L_UWB_RR_FD 38;
BA_ "NmNode" BU_ L_UWB_RR_FD 1;
BA_ "NmStationAddress" BU_ L_UWB_TRNK_FD 39;
BA_ "NmNode" BU_ L_UWB_TRNK_FD 1;
BA_ "NmStationAddress" BU_ L_WPC_FD 30;
BA_ "NmNode" BU_ L_WPC_FD 1;
BA_ "GenSigSendType" SG_ 1087 CCU_ForcedPowerOffReq 4;
BA_ "UserSigValidity" SG_ 1087 CCU_ForcedPowerOffReq 0;
BA_REL_ "GenSigTimeoutTime" BU_SG_REL_ L_DHL_FD SG_ 1087 CCU_ForcedPowerOffReq 0;
BA_REL_ "GenSigTimeoutTime" BU_SG_REL_ L_DHRL_FD SG_ 1087 CCU_ForcedPowerOffReq 0;
BA_REL_ "GenSigTimeoutTime" BU_SG_REL_ L_DHRR_FD SG_ 1087 CCU_ForcedPowerOffReq 0;
BA_REL_ "GenSigTimeoutTime" BU_SG_REL_ L_DHR_FD SG_ 1087 CCU_ForcedPowerOffReq 0;
BA_REL_ "GenSigTimeoutTime" BU_SG_REL_ L_ROA_FD SG_ 1087 CCU_ForcedPowerOffReq 0;
BA_REL_ "GenSigTimeoutTime" BU_SG_REL_ L_ROA_FR_FD SG_ 1087 CCU_ForcedPowerOffReq 0;
BA_REL_ "GenSigTimeoutTime" BU_SG_REL_ L_SAL_FD SG_ 1087 CCU_ForcedPowerOffReq 0;
BA_REL_ "GenSigTimeoutTime" BU_SG_REL_ L_TPMS_FD SG_ 1087 CCU_ForcedPowerOffReq 0;
BA_REL_ "GenSigTimeoutTime" BU_SG_REL_ L_UWB_BLE_MST_FD SG_ 1087 CCU_ForcedPowerOffReq 0;
BA_REL_ "GenSigTimeoutTime" BU_SG_REL_ L_UWB_BLE_SLV_FD SG_ 1087 CCU_ForcedPowerOffReq 0;
BA_REL_ "GenSigTimeoutTime" BU_SG_REL_ L_UWB_FL_FD SG_ 1087 CCU_ForcedPowerOffReq 0;
BA_REL_ "GenSigTimeoutTime" BU_SG_REL_ L_UWB_FRNK_FD SG_ 1087 CCU_ForcedPowerOffReq 0;
BA_REL_ "GenSigTimeoutTime" BU_SG_REL_ L_UWB_FR_FD SG_ 1087 CCU_ForcedPowerOffReq 0;
BA_REL_ "GenSigTimeoutTime" BU_SG_REL_ L_UWB_RL_FD SG_ 1087 CCU_ForcedPowerOffReq 0;
BA_REL_ "GenSigTimeoutTime" BU_SG_REL_ L_UWB_RR_FD SG_ 1087 CCU_ForcedPowerOffReq 0;
BA_REL_ "GenSigTimeoutTime" BU_SG_REL_ L_UWB_TRNK_FD SG_ 1087 CCU_ForcedPowerOffReq 0;
BA_REL_ "GenSigTimeoutTime" BU_SG_REL_ L_WPC_FD SG_ 1087 CCU_ForcedPowerOffReq 0;
BA_ "NetworkRequest" SG_ 1087 CCU_ForcedPowerOffReq 0;
BA_ "NetworkRequestHoldingTime" SG_ 1087 CCU_ForcedPowerOffReq 5000;
BA_ "Version" SG_ 1087 CCU_ForcedPowerOffReq "20.03.01";
BA_ "GenMsgCycleTime" BO_ 2015 0;
BA_ "GenMsgCycleTimeFast" BO_ 2015 0;
BA_ "GenMsgNrOfRepetition" BO_ 2015 0;
BA_ "DiagState" BO_ 2015 1;
BA_ "GenMsgILSupport" BO_ 2015 0;
BA_ "TpMessage" BO_ 2015 1;
BA_ "VFrameFormat" BO_ 2015 14;
BA_ "Description" SG_ 2015 GST_ALL_Byte0 "TP Index : 0";
BA_ "UsrSigPurpose" SG_ 2015 GST_ALL_Byte0 5;
BA_ "UserSigValidity" SG_ 2015 GST_ALL_Byte0 0;
BA_REL_ "GenSigTimeoutTime" BU_SG_REL_ L_DHL_FD SG_ 2015 GST_ALL_Byte0 0;
BA_REL_ "GenSigTimeoutTime" BU_SG_REL_ L_DHRL_FD SG_ 2015 GST_ALL_Byte0 0;
BA_REL_ "GenSigTimeoutTime" BU_SG_REL_ L_DHRR_FD SG_ 2015 GST_ALL_Byte0 0;
BA_REL_ "GenSigTimeoutTime" BU_SG_REL_ L_DHR_FD SG_ 2015 GST_ALL_Byte0 0;
BA_REL_ "GenSigTimeoutTime" BU_SG_REL_ L_ROA_FD SG_ 2015 GST_ALL_Byte0 0;
BA_REL_ "GenSigTimeoutTime" BU_SG_REL_ L_ROA_FR_FD SG_ 2015 GST_ALL_Byte0 0;
BA_REL_ "GenSigTimeoutTime" BU_SG_REL_ L_SAL_FD SG_ 2015 GST_ALL_Byte0 0;
BA_REL_ "GenSigTimeoutTime" BU_SG_REL_ L_UWB_BLE_MST_FD SG_ 2015 GST_ALL_Byte0 0;
BA_REL_ "GenSigTimeoutTime" BU_SG_REL_ L_WPC_FD SG_ 2015 GST_ALL_Byte0 0;
BA_ "NetworkRequest" SG_ 2015 GST_ALL_Byte0 0;
BA_ "NetworkRequestHoldingTime" SG_ 2015 GST_ALL_Byte0 5000;
BA_ "Version" SG_ 2015 GST_ALL_Byte0 "22.06.01";
BA_ "Description" SG_ 2015 GST_ALL_Byte2 "TP Index : 0";
BA_ "UsrSigPurpose" SG_ 2015 GST_ALL_Byte2 5;
BA_ "UserSigValidity" SG_ 2015 GST_ALL_Byte2 0;
BA_REL_ "GenSigTimeoutTime" BU_SG_REL_ L_DHL_FD SG_ 2015 GST_ALL_Byte2 0;
BA_REL_ "GenSigTimeoutTime" BU_SG_REL_ L_DHRL_FD SG_ 2015 GST_ALL_Byte2 0;
BA_REL_ "GenSigTimeoutTime" BU_SG_REL_ L_DHRR_FD SG_ 2015 GST_ALL_Byte2 0;
BA_REL_ "GenSigTimeoutTime" BU_SG_REL_ L_DHR_FD SG_ 2015 GST_ALL_Byte2 0;
BA_REL_ "GenSigTimeoutTime" BU_SG_REL_ L_ROA_FD SG_ 2015 GST_ALL_Byte2 0;
BA_REL_ "GenSigTimeoutTime" BU_SG_REL_ L_ROA_FR_FD SG_ 2015 GST_ALL_Byte2 0;
BA_REL_ "GenSigTimeoutTime" BU_SG_REL_ L_SAL_FD SG_ 2015 GST_ALL_Byte2 0;
BA_REL_ "GenSigTimeoutTime" BU_SG_REL_ L_UWB_BLE_MST_FD SG_ 2015 GST_ALL_Byte2 0;
BA_REL_ "GenSigTimeoutTime" BU_SG_REL_ L_WPC_FD SG_ 2015 GST_ALL_Byte2 0;
BA_ "NetworkRequest" SG_ 2015 GST_ALL_Byte2 0;
BA_ "NetworkRequestHoldingTime" SG_ 2015 GST_ALL_Byte2 5000;
BA_ "Version" SG_ 2015 GST_ALL_Byte2 "22.06.01";
BA_ "Description" SG_ 2015 GST_ALL_Byte3 "TP Index : 0";
BA_ "UsrSigPurpose" SG_ 2015 GST_ALL_Byte3 5;
BA_ "UserSigValidity" SG_ 2015 GST_ALL_Byte3 0;
BA_REL_ "GenSigTimeoutTime" BU_SG_REL_ L_DHL_FD SG_ 2015 GST_ALL_Byte3 0;
BA_REL_ "GenSigTimeoutTime" BU_SG_REL_ L_DHRL_FD SG_ 2015 GST_ALL_Byte3 0;
BA_REL_ "GenSigTimeoutTime" BU_SG_REL_ L_DHRR_FD SG_ 2015 GST_ALL_Byte3 0;
BA_REL_ "GenSigTimeoutTime" BU_SG_REL_ L_DHR_FD SG_ 2015 GST_ALL_Byte3 0;
BA_REL_ "GenSigTimeoutTime" BU_SG_REL_ L_ROA_FD SG_ 2015 GST_ALL_Byte3 0;
BA_REL_ "GenSigTimeoutTime" BU_SG_REL_ L_ROA_FR_FD SG_ 2015 GST_ALL_Byte3 0;
BA_REL_ "GenSigTimeoutTime" BU_SG_REL_ L_SAL_FD SG_ 2015 GST_ALL_Byte3 0;
BA_REL_ "GenSigTimeoutTime" BU_SG_REL_ L_UWB_BLE_MST_FD SG_ 2015 GST_ALL_Byte3 0;
BA_REL_ "GenSigTimeoutTime" BU_SG_REL_ L_WPC_FD SG_ 2015 GST_ALL_Byte3 0;
BA_ "NetworkRequest" SG_ 2015 GST_ALL_Byte3 0;
BA_ "NetworkRequestHoldingTime" SG_ 2015 GST_ALL_Byte3 5000;
BA_ "Version" SG_ 2015 GST_ALL_Byte3 "22.06.01";
BA_ "Description" SG_ 2015 GST_ALL_Byte4 "TP Index : 0";
BA_ "UsrSigPurpose" SG_ 2015 GST_ALL_Byte4 5;
BA_ "UserSigValidity" SG_ 2015 GST_ALL_Byte4 0;
BA_REL_ "GenSigTimeoutTime" BU_SG_REL_ L_DHL_FD SG_ 2015 GST_ALL_Byte4 0;
BA_REL_ "GenSigTimeoutTime" BU_SG_REL_ L_DHRL_FD SG_ 2015 GST_ALL_Byte4 0;
BA_REL_ "GenSigTimeoutTime" BU_SG_REL_ L_DHRR_FD SG_ 2015 GST_ALL_Byte4 0;
BA_REL_ "GenSigTimeoutTime" BU_SG_REL_ L_DHR_FD SG_ 2015 GST_ALL_Byte4 0;
BA_REL_ "GenSigTimeoutTime" BU_SG_REL_ L_ROA_FD SG_ 2015 GST_ALL_Byte4 0;
BA_REL_ "GenSigTimeoutTime" BU_SG_REL_ L_ROA_FR_FD SG_ 2015 GST_ALL_Byte4 0;
BA_REL_ "GenSigTimeoutTime" BU_SG_REL_ L_SAL_FD SG_ 2015 GST_ALL_Byte4 0;
BA_REL_ "GenSigTimeoutTime" BU_SG_REL_ L_UWB_BLE_MST_FD SG_ 2015 GST_ALL_Byte4 0;
BA_REL_ "GenSigTimeoutTime" BU_SG_REL_ L_WPC_FD SG_ 2015 GST_ALL_Byte4 0;
BA_ "NetworkRequest" SG_ 2015 GST_ALL_Byte4 0;
BA_ "NetworkRequestHoldingTime" SG_ 2015 GST_ALL_Byte4 5000;
BA_ "Version" SG_ 2015 GST_ALL_Byte4 "22.06.01";
BA_ "Description" SG_ 2015 GST_ALL_Byte5 "TP Index : 0";
BA_ "UsrSigPurpose" SG_ 2015 GST_ALL_Byte5 5;
BA_ "UserSigValidity" SG_ 2015 GST_ALL_Byte5 0;
BA_REL_ "GenSigTimeoutTime" BU_SG_REL_ L_DHL_FD SG_ 2015 GST_ALL_Byte5 0;
BA_REL_ "GenSigTimeoutTime" BU_SG_REL_ L_DHRL_FD SG_ 2015 GST_ALL_Byte5 0;
BA_REL_ "GenSigTimeoutTime" BU_SG_REL_ L_DHRR_FD SG_ 2015 GST_ALL_Byte5 0;
BA_REL_ "GenSigTimeoutTime" BU_SG_REL_ L_DHR_FD SG_ 2015 GST_ALL_Byte5 0;
BA_REL_ "GenSigTimeoutTime" BU_SG_REL_ L_ROA_FD SG_ 2015 GST_ALL_Byte5 0;
BA_REL_ "GenSigTimeoutTime" BU_SG_REL_ L_ROA_FR_FD SG_ 2015 GST_ALL_Byte5 0;
BA_REL_ "GenSigTimeoutTime" BU_SG_REL_ L_SAL_FD SG_ 2015 GST_ALL_Byte5 0;
BA_REL_ "GenSigTimeoutTime" BU_SG_REL_ L_UWB_BLE_MST_FD SG_ 2015 GST_ALL_Byte5 0;
BA_REL_ "GenSigTimeoutTime" BU_SG_REL_ L_WPC_FD SG_ 2015 GST_ALL_Byte5 0;
BA_ "NetworkRequest" SG_ 2015 GST_ALL_Byte5 0;
BA_ "NetworkRequestHoldingTime" SG_ 2015 GST_ALL_Byte5 5000;
BA_ "Version" SG_ 2015 GST_ALL_Byte5 "22.06.01";
BA_ "Description" SG_ 2015 GST_ALL_Byte6 "TP Index : 0";
BA_ "UsrSigPurpose" SG_ 2015 GST_ALL_Byte6 5;
BA_ "UserSigValidity" SG_ 2015 GST_ALL_Byte6 0;
BA_REL_ "GenSigTimeoutTime" BU_SG_REL_ L_DHL_FD SG_ 2015 GST_ALL_Byte6 0;
BA_REL_ "GenSigTimeoutTime" BU_SG_REL_ L_DHRL_FD SG_ 2015 GST_ALL_Byte6 0;
BA_REL_ "GenSigTimeoutTime" BU_SG_REL_ L_DHRR_FD SG_ 2015 GST_ALL_Byte6 0;
BA_REL_ "GenSigTimeoutTime" BU_SG_REL_ L_DHR_FD SG_ 2015 GST_ALL_Byte6 0;
BA_REL_ "GenSigTimeoutTime" BU_SG_REL_ L_ROA_FD SG_ 2015 GST_ALL_Byte6 0;
BA_REL_ "GenSigTimeoutTime" BU_SG_REL_ L_ROA_FR_FD SG_ 2015 GST_ALL_Byte6 0;
BA_REL_ "GenSigTimeoutTime" BU_SG_REL_ L_SAL_FD SG_ 2015 GST_ALL_Byte6 0;
BA_REL_ "GenSigTimeoutTime" BU_SG_REL_ L_UWB_BLE_MST_FD SG_ 2015 GST_ALL_Byte6 0;
BA_REL_ "GenSigTimeoutTime" BU_SG_REL_ L_WPC_FD SG_ 2015 GST_ALL_Byte6 0;
BA_ "NetworkRequest" SG_ 2015 GST_ALL_Byte6 0;
BA_ "NetworkRequestHoldingTime" SG_ 2015 GST_ALL_Byte6 5000;
BA_ "Version" SG_ 2015 GST_ALL_Byte6 "22.06.01";
BA_ "Description" SG_ 2015 GST_ALL_Byte7 "TP Index : 0";
BA_ "UsrSigPurpose" SG_ 2015 GST_ALL_Byte7 5;
BA_ "UserSigValidity" SG_ 2015 GST_ALL_Byte7 0;
BA_REL_ "GenSigTimeoutTime" BU_SG_REL_ L_DHL_FD SG_ 2015 GST_ALL_Byte7 0;
BA_REL_ "GenSigTimeoutTime" BU_SG_REL_ L_DHRL_FD SG_ 2015 GST_ALL_Byte7 0;
BA_REL_ "GenSigTimeoutTime" BU_SG_REL_ L_DHRR_FD SG_ 2015 GST_ALL_Byte7 0;
BA_REL_ "GenSigTimeoutTime" BU_SG_REL_ L_DHR_FD SG_ 2015 GST_ALL_Byte7 0;
BA_REL_ "GenSigTimeoutTime" BU_SG_REL_ L_ROA_FD SG_ 2015 GST_ALL_Byte7 0;
BA_REL_ "GenSigTimeoutTime" BU_SG_REL_ L_ROA_FR_FD SG_ 2015 GST_ALL_Byte7 0;
BA_REL_ "GenSigTimeoutTime" BU_SG_REL_ L_SAL_FD SG_ 2015 GST_ALL_Byte7 0;
BA_REL_ "GenSigTimeoutTime" BU_SG_REL_ L_UWB_BLE_MST_FD SG_ 2015 GST_ALL_Byte7 0;
BA_REL_ "GenSigTimeoutTime" BU_SG_REL_ L_WPC_FD SG_ 2015 GST_ALL_Byte7 0;
BA_ "NetworkRequest" SG_ 2015 GST_ALL_Byte7 0;
BA_ "NetworkRequestHoldingTime" SG_ 2015 GST_ALL_Byte7 5000;
BA_ "Version" SG_ 2015 GST_ALL_Byte7 "22.06.01";
BA_ "Description" SG_ 2015 GST_ALL_Byte1 "TP Index : 0";
BA_ "UsrSigPurpose" SG_ 2015 GST_ALL_Byte1 5;
BA_ "UserSigValidity" SG_ 2015 GST_ALL_Byte1 0;
BA_REL_ "GenSigTimeoutTime" BU_SG_REL_ L_DHL_FD SG_ 2015 GST_ALL_Byte1 0;
BA_REL_ "GenSigTimeoutTime" BU_SG_REL_ L_DHRL_FD SG_ 2015 GST_ALL_Byte1 0;
BA_REL_ "GenSigTimeoutTime" BU_SG_REL_ L_DHRR_FD SG_ 2015 GST_ALL_Byte1 0;
BA_REL_ "GenSigTimeoutTime" BU_SG_REL_ L_DHR_FD SG_ 2015 GST_ALL_Byte1 0;
BA_REL_ "GenSigTimeoutTime" BU_SG_REL_ L_ROA_FD SG_ 2015 GST_ALL_Byte1 0;
BA_REL_ "GenSigTimeoutTime" BU_SG_REL_ L_ROA_FR_FD SG_ 2015 GST_ALL_Byte1 0;
BA_REL_ "GenSigTimeoutTime" BU_SG_REL_ L_SAL_FD SG_ 2015 GST_ALL_Byte1 0;
BA_REL_ "GenSigTimeoutTime" BU_SG_REL_ L_UWB_BLE_MST_FD SG_ 2015 GST_ALL_Byte1 0;
BA_REL_ "GenSigTimeoutTime" BU_SG_REL_ L_WPC_FD SG_ 2015 GST_ALL_Byte1 0;
BA_ "NetworkRequest" SG_ 2015 GST_ALL_Byte1 0;
BA_ "NetworkRequestHoldingTime" SG_ 2015 GST_ALL_Byte1 5000;
BA_ "Version" SG_ 2015 GST_ALL_Byte1 "22.06.01";
BA_ "GenMsgSendType" BO_ 849 0;
BA_ "GenMsgStartDelayTime" BO_ 849 40;
BA_ "VFrameFormat" BO_ 849 14;
BA_ "Description" SG_ 849 IAU_FD_Crc4Val "The data area for CRC calculation is based on the data length (DLC) of the message DB.

The CRC shall be calculated over the entire data block (excluding the CRC bytes) including the user data, alive counter and Data ID



- CRC Polynomial (0x1021) , Initial Value : 0xFFFF, XOR value : 0x0000, Data ID : Message ID + 0xF800 

- The initial value is for CRC calculation and the message should be sent with the calculated result value. 

- The mathematical expression to 16 bit CRC polynomial is given here. G(x) = x16 + x12 + x5 + 1



<For CRC calculation of CAN-FD Msg for HS CAN domain ECUs>



- HS-CAN Messages that routed from CAN-FD domain are using 29 bit Extended CAN ID and splitted into 8 Byte Messages.

(from 1 to 4 Msgs, depending on source CAN-FD Msg¡¯s DLC)

- For splitted CAN-FD Msgs¡¯ CRC calculation, HS CAN ECUs should use source CAN-FD Msg¡¯s original STD ID. 

- The original STD ID can be read from Ext ID¡¯s 4~6th Byte.

Eg. STD 0x6AA : EXT SPLT 0x1A8[6AA]01 / 0x1A8[6AA]02 / 0x1A8[6AA]03 / 0x1A8[6AA]04 

(2~4th splitited Msgs can be omitted depending on source CAN-FD Msg¡¯s DLC)

- Aslo, HS-CAN ECUs should use merged data block (from whole splitted Msg) for CRC calculation.";
BA_ "GenSigSendType" SG_ 849 IAU_FD_Crc4Val 4;
BA_ "GenSigStartValue" SG_ 849 IAU_FD_Crc4Val 65535;
BA_ "UserSigValidity" SG_ 849 IAU_FD_Crc4Val 0;
BA_ "Version" SG_ 849 IAU_FD_Crc4Val "22.11.04";
BA_ "Description" SG_ 849 IAU_DISPWrng "This siganl warning from IAU

- 0x9 (WPCNFC_PreStartAuth_Success) : CLU display when workaround or LPCD Start Auth succeeded (before SSB pressed).";
BA_ "GenSigSendType" SG_ 849 IAU_DISPWrng 4;
BA_ "UserSigValidity" SG_ 849 IAU_DISPWrng 0;
BA_ "NetworkRequest" SG_ 849 IAU_DISPWrng 0;
BA_ "NetworkRequestHoldingTime" SG_ 849 IAU_DISPWrng 5000;
BA_ "Version" SG_ 849 IAU_DISPWrng "22.06.04";
BA_ "Description" SG_ 849 IAU_DigitalKey2Opt "This signal describe Digital Key capability";
BA_ "GenSigSendType" SG_ 849 IAU_DigitalKey2Opt 4;
BA_ "UserSigValidity" SG_ 849 IAU_DigitalKey2Opt 0;
BA_ "NetworkRequest" SG_ 849 IAU_DigitalKey2Opt 0;
BA_ "NetworkRequestHoldingTime" SG_ 849 IAU_DigitalKey2Opt 5000;
BA_ "Version" SG_ 849 IAU_DigitalKey2Opt "20.08.00";
BA_ "Description" SG_ 849 IAUwFRULearnState "This signal indicates learning process stste between IAU and FRU";
BA_ "GenSigSendType" SG_ 849 IAUwFRULearnState 4;
BA_ "UserSigValidity" SG_ 849 IAUwFRULearnState 0;
BA_ "NetworkRequest" SG_ 849 IAUwFRULearnState 0;
BA_ "NetworkRequestHoldingTime" SG_ 849 IAUwFRULearnState 5000;
BA_ "Version" SG_ 849 IAUwFRULearnState "20.04.05";
BA_ "Description" SG_ 849 IAUwFPMLearnState "This signal indicates learning process stste between IAU and FPM";
BA_ "GenSigSendType" SG_ 849 IAUwFPMLearnState 4;
BA_ "UserSigValidity" SG_ 849 IAUwFPMLearnState 0;
BA_ "NetworkRequest" SG_ 849 IAUwFPMLearnState 0;
BA_ "NetworkRequestHoldingTime" SG_ 849 IAUwFPMLearnState 5000;
BA_ "Version" SG_ 849 IAUwFPMLearnState "20.04.05";
BA_ "GenSigSendType" SG_ 849 IAU_ValetDigitalkey 4;
BA_ "UserSigValidity" SG_ 849 IAU_ValetDigitalkey 0;
BA_ "NetworkRequest" SG_ 849 IAU_ValetDigitalkey 0;
BA_ "NetworkRequestHoldingTime" SG_ 849 IAU_ValetDigitalkey 5000;
BA_ "Version" SG_ 849 IAU_ValetDigitalkey "20.08.05";
BA_ "Description" SG_ 849 IAU_DigitalKeyNumberOpt "This signal is for the digital key number type. 

(Ex. Max 16 of digital keys in total can be saved and shared)";
BA_ "GenSigSendType" SG_ 849 IAU_DigitalKeyNumberOpt 4;
BA_ "UserSigValidity" SG_ 849 IAU_DigitalKeyNumberOpt 0;
BA_ "NetworkRequest" SG_ 849 IAU_DigitalKeyNumberOpt 0;
BA_ "NetworkRequestHoldingTime" SG_ 849 IAU_DigitalKeyNumberOpt 5000;
BA_ "Version" SG_ 849 IAU_DigitalKeyNumberOpt "23.04.04";
BA_ "Description" SG_ 849 IAU_eSEReprogramSta "eSE Reprograming Status";
BA_ "GenSigSendType" SG_ 849 IAU_eSEReprogramSta 4;
BA_ "TimeoutValue" SG_ 849 IAU_eSEReprogramSta "0";
BA_ "UserSigValidity" SG_ 849 IAU_eSEReprogramSta 0;
BA_ "NetworkRequest" SG_ 849 IAU_eSEReprogramSta 0;
BA_ "NetworkRequestHoldingTime" SG_ 849 IAU_eSEReprogramSta 5000;
BA_ "Version" SG_ 849 IAU_eSEReprogramSta "22.07.04";
BA_ "Description" SG_ 849 IAU_DKOwnerSwapOption "Digital key owner swap option signal";
BA_ "GenSigSendType" SG_ 849 IAU_DKOwnerSwapOption 4;
BA_ "UserSigValidity" SG_ 849 IAU_DKOwnerSwapOption 0;
BA_REL_ "GenSigTimeoutTime" BU_SG_REL_ L_UWB_BLE_MST_FD SG_ 849 IAU_DKOwnerSwapOption 1500;
BA_REL_ "GenSigTimeoutTime" BU_SG_REL_ L_UWB_BLE_SLV_FD SG_ 849 IAU_DKOwnerSwapOption 1500;
BA_REL_ "GenSigTimeoutTime" BU_SG_REL_ L_UWB_FL_FD SG_ 849 IAU_DKOwnerSwapOption 1500;
BA_REL_ "GenSigTimeoutTime" BU_SG_REL_ L_UWB_FRNK_FD SG_ 849 IAU_DKOwnerSwapOption 1500;
BA_REL_ "GenSigTimeoutTime" BU_SG_REL_ L_UWB_FR_FD SG_ 849 IAU_DKOwnerSwapOption 1500;
BA_REL_ "GenSigTimeoutTime" BU_SG_REL_ L_UWB_RL_FD SG_ 849 IAU_DKOwnerSwapOption 1500;
BA_REL_ "GenSigTimeoutTime" BU_SG_REL_ L_UWB_RR_FD SG_ 849 IAU_DKOwnerSwapOption 1500;
BA_REL_ "GenSigTimeoutTime" BU_SG_REL_ L_UWB_TRNK_FD SG_ 849 IAU_DKOwnerSwapOption 1500;
BA_REL_ "GenSigTimeoutTime" BU_SG_REL_ L_WPC_FD SG_ 849 IAU_DKOwnerSwapOption 1500;
BA_ "Version" SG_ 849 IAU_DKOwnerSwapOption "24.01.04";
BA_ "Description" SG_ 849 IAU_DgtKeyGrpPrflRval2 "Digital Key Group number(max : 16 )";
BA_ "GenSigSendType" SG_ 849 IAU_DgtKeyGrpPrflRval2 4;
BA_ "UserSigValidity" SG_ 849 IAU_DgtKeyGrpPrflRval2 0;
BA_ "NetworkRequest" SG_ 849 IAU_DgtKeyGrpPrflRval2 0;
BA_ "NetworkRequestHoldingTime" SG_ 849 IAU_DgtKeyGrpPrflRval2 5000;
BA_ "Version" SG_ 849 IAU_DgtKeyGrpPrflRval2 "23.02.13";
BA_ "GenSigSendType" SG_ 849 IAU_StartIdentifiedProfile 4;
BA_ "TimeoutValue" SG_ 849 IAU_StartIdentifiedProfile "0x0";
BA_ "UserSigValidity" SG_ 849 IAU_StartIdentifiedProfile 0;
BA_ "NetworkRequest" SG_ 849 IAU_StartIdentifiedProfile 0;
BA_ "NetworkRequestHoldingTime" SG_ 849 IAU_StartIdentifiedProfile 5000;
BA_ "Version" SG_ 849 IAU_StartIdentifiedProfile "20.05.02";
BA_ "Description" SG_ 849 IAU_DigitalKeyProfileRval2 "digital key number : max. 16";
BA_ "GenSigSendType" SG_ 849 IAU_DigitalKeyProfileRval2 4;
BA_ "UserSigValidity" SG_ 849 IAU_DigitalKeyProfileRval2 0;
BA_ "NetworkRequest" SG_ 849 IAU_DigitalKeyProfileRval2 0;
BA_ "NetworkRequestHoldingTime" SG_ 849 IAU_DigitalKeyProfileRval2 5000;
BA_ "Version" SG_ 849 IAU_DigitalKeyProfileRval2 "22.05.04";
BA_ "GenSigSendType" SG_ 849 IAU_NFCCard1SN 4;
BA_ "UserSigValidity" SG_ 849 IAU_NFCCard1SN 0;
BA_ "NetworkRequest" SG_ 849 IAU_NFCCard1SN 0;
BA_ "NetworkRequestHoldingTime" SG_ 849 IAU_NFCCard1SN 5000;
BA_ "Version" SG_ 849 IAU_NFCCard1SN "21.07.05";
BA_ "Description" SG_ 849 IAU_FD_AlvCnt4Val "For the first transmission request for a data element the counter shall be initialized with 0 and shall be incremented by 1 for every subsequent send request. 

When the counter reaches the maximum value(0xFF), then it shall restart with 0 for the next send request";
BA_ "GenSigSendType" SG_ 849 IAU_FD_AlvCnt4Val 4;
BA_ "UserSigValidity" SG_ 849 IAU_FD_AlvCnt4Val 0;
BA_ "Version" SG_ 849 IAU_FD_AlvCnt4Val "22.11.04";
BA_ "GenSigSendType" SG_ 849 IAU_StartIdentifiedProfile_Ext 4;
BA_ "UserSigValidity" SG_ 849 IAU_StartIdentifiedProfile_Ext 0;
BA_ "NetworkRequest" SG_ 849 IAU_StartIdentifiedProfile_Ext 0;
BA_ "NetworkRequestHoldingTime" SG_ 849 IAU_StartIdentifiedProfile_Ext 5000;
BA_ "Version" SG_ 849 IAU_StartIdentifiedProfile_Ext "23.04.04";
BA_ "GenSigSendType" SG_ 849 RSPA_UWBRspaExtRngSta 4;
BA_ "UserSigValidity" SG_ 849 RSPA_UWBRspaExtRngSta 0;
BA_ "NetworkRequest" SG_ 849 RSPA_UWBRspaExtRngSta 0;
BA_ "NetworkRequestHoldingTime" SG_ 849 RSPA_UWBRspaExtRngSta 5000;
BA_ "Version" SG_ 849 RSPA_UWBRspaExtRngSta "20.03.05";
BA_ "Description" SG_ 849 RSPA_CanFltSta "Error status of RSPA control signals.";
BA_ "GenSigSendType" SG_ 849 RSPA_CanFltSta 4;
BA_ "UserSigValidity" SG_ 849 RSPA_CanFltSta 0;
BA_ "Version" SG_ 849 RSPA_CanFltSta "20.02.00";
BA_ "Description" SG_ 849 RSPA_BLESigErrSta "Error status of Digital Key BLE_BtnReq signal.



If BLE frame data from Digital Key defferent with CAN signal data, 

RSPA_BLESigErrSta signal send 0x1 Signal Invalid.";
BA_ "GenSigSendType" SG_ 849 RSPA_BLESigErrSta 4;
BA_ "UserSigValidity" SG_ 849 RSPA_BLESigErrSta 0;
BA_ "NetworkRequest" SG_ 849 RSPA_BLESigErrSta 0;
BA_ "NetworkRequestHoldingTime" SG_ 849 RSPA_BLESigErrSta 5000;
BA_ "Version" SG_ 849 RSPA_BLESigErrSta "20.02.00";
BA_ "Description" SG_ 849 RSPA_ConStat "Connection Status among RSPA, IAU, BLE and SmartPhone";
BA_ "GenSigSendType" SG_ 849 RSPA_ConStat 4;
BA_ "UserSigValidity" SG_ 849 RSPA_ConStat 0;
BA_ "NetworkRequest" SG_ 849 RSPA_ConStat 0;
BA_ "NetworkRequestHoldingTime" SG_ 849 RSPA_ConStat 5000;
BA_ "Version" SG_ 849 RSPA_ConStat "20.02.00";
BA_ "GenSigSendType" SG_ 849 IAU_ProfileIDRVal 4;
BA_ "UserSigValidity" SG_ 849 IAU_ProfileIDRVal 0;
BA_ "NetworkRequest" SG_ 849 IAU_ProfileIDRVal 0;
BA_ "NetworkRequestHoldingTime" SG_ 849 IAU_ProfileIDRVal 5000;
BA_ "Version" SG_ 849 IAU_ProfileIDRVal "23.02.02";
BA_ "GenSigSendType" SG_ 849 IAU_DigitalKeyProcessingSta 4;
BA_ "UserSigValidity" SG_ 849 IAU_DigitalKeyProcessingSta 3;
BA_ "NetworkRequest" SG_ 849 IAU_DigitalKeyProcessingSta 0;
BA_ "NetworkRequestHoldingTime" SG_ 849 IAU_DigitalKeyProcessingSta 5000;
BA_ "Version" SG_ 849 IAU_DigitalKeyProcessingSta "23.02.13";
BA_ "Description" SG_ 849 IAU_DigitalKeyExit "Digital Key USM setting Exit Condition";
BA_ "GenSigSendType" SG_ 849 IAU_DigitalKeyExit 4;
BA_ "UserSigValidity" SG_ 849 IAU_DigitalKeyExit 3;
BA_ "NetworkRequest" SG_ 849 IAU_DigitalKeyExit 0;
BA_ "NetworkRequestHoldingTime" SG_ 849 IAU_DigitalKeyExit 5000;
BA_ "Version" SG_ 849 IAU_DigitalKeyExit "23.07.03";
BA_ "GenSigSendType" SG_ 849 IAU_DigitalKeyEnblRVal 4;
BA_ "UserSigValidity" SG_ 849 IAU_DigitalKeyEnblRVal 0;
BA_REL_ "GenSigTimeoutTime" BU_SG_REL_ L_DHL_FD SG_ 849 IAU_DigitalKeyEnblRVal 1500;
BA_REL_ "GenSigTimeoutTime" BU_SG_REL_ L_DHRL_FD SG_ 849 IAU_DigitalKeyEnblRVal 1500;
BA_REL_ "GenSigTimeoutTime" BU_SG_REL_ L_DHRR_FD SG_ 849 IAU_DigitalKeyEnblRVal 1500;
BA_REL_ "GenSigTimeoutTime" BU_SG_REL_ L_DHR_FD SG_ 849 IAU_DigitalKeyEnblRVal 1500;
BA_REL_ "GenSigTimeoutTime" BU_SG_REL_ L_UWB_BLE_MST_FD SG_ 849 IAU_DigitalKeyEnblRVal 1500;
BA_REL_ "GenSigTimeoutTime" BU_SG_REL_ L_UWB_BLE_SLV_FD SG_ 849 IAU_DigitalKeyEnblRVal 1500;
BA_REL_ "GenSigTimeoutTime" BU_SG_REL_ L_UWB_FL_FD SG_ 849 IAU_DigitalKeyEnblRVal 1500;
BA_REL_ "GenSigTimeoutTime" BU_SG_REL_ L_UWB_FRNK_FD SG_ 849 IAU_DigitalKeyEnblRVal 1500;
BA_REL_ "GenSigTimeoutTime" BU_SG_REL_ L_UWB_FR_FD SG_ 849 IAU_DigitalKeyEnblRVal 1500;
BA_REL_ "GenSigTimeoutTime" BU_SG_REL_ L_UWB_RL_FD SG_ 849 IAU_DigitalKeyEnblRVal 1500;
BA_REL_ "GenSigTimeoutTime" BU_SG_REL_ L_UWB_RR_FD SG_ 849 IAU_DigitalKeyEnblRVal 1500;
BA_REL_ "GenSigTimeoutTime" BU_SG_REL_ L_UWB_TRNK_FD SG_ 849 IAU_DigitalKeyEnblRVal 1500;
BA_ "NetworkRequest" SG_ 849 IAU_DigitalKeyEnblRVal 0;
BA_ "NetworkRequestHoldingTime" SG_ 849 IAU_DigitalKeyEnblRVal 5000;
BA_ "Version" SG_ 849 IAU_DigitalKeyEnblRVal "20.05.02";
BA_ "GenSigSendType" SG_ 849 IAU_OwnerPhnRegRVal 4;
BA_ "UserSigValidity" SG_ 849 IAU_OwnerPhnRegRVal 0;
BA_REL_ "GenSigTimeoutTime" BU_SG_REL_ L_DHL_FD SG_ 849 IAU_OwnerPhnRegRVal 1500;
BA_REL_ "GenSigTimeoutTime" BU_SG_REL_ L_DHRL_FD SG_ 849 IAU_OwnerPhnRegRVal 1500;
BA_REL_ "GenSigTimeoutTime" BU_SG_REL_ L_DHRR_FD SG_ 849 IAU_OwnerPhnRegRVal 1500;
BA_REL_ "GenSigTimeoutTime" BU_SG_REL_ L_DHR_FD SG_ 849 IAU_OwnerPhnRegRVal 1500;
BA_REL_ "GenSigTimeoutTime" BU_SG_REL_ L_UWB_BLE_MST_FD SG_ 849 IAU_OwnerPhnRegRVal 1500;
BA_REL_ "GenSigTimeoutTime" BU_SG_REL_ L_UWB_BLE_SLV_FD SG_ 849 IAU_OwnerPhnRegRVal 1500;
BA_REL_ "GenSigTimeoutTime" BU_SG_REL_ L_UWB_FL_FD SG_ 849 IAU_OwnerPhnRegRVal 1500;
BA_REL_ "GenSigTimeoutTime" BU_SG_REL_ L_UWB_FRNK_FD SG_ 849 IAU_OwnerPhnRegRVal 1500;
BA_REL_ "GenSigTimeoutTime" BU_SG_REL_ L_UWB_FR_FD SG_ 849 IAU_OwnerPhnRegRVal 1500;
BA_REL_ "GenSigTimeoutTime" BU_SG_REL_ L_UWB_RL_FD SG_ 849 IAU_OwnerPhnRegRVal 1500;
BA_REL_ "GenSigTimeoutTime" BU_SG_REL_ L_UWB_RR_FD SG_ 849 IAU_OwnerPhnRegRVal 1500;
BA_REL_ "GenSigTimeoutTime" BU_SG_REL_ L_UWB_TRNK_FD SG_ 849 IAU_OwnerPhnRegRVal 1500;
BA_REL_ "GenSigTimeoutTime" BU_SG_REL_ L_WPC_FD SG_ 849 IAU_OwnerPhnRegRVal 1500;
BA_ "NetworkRequest" SG_ 849 IAU_OwnerPhnRegRVal 0;
BA_ "NetworkRequestHoldingTime" SG_ 849 IAU_OwnerPhnRegRVal 5000;
BA_ "Version" SG_ 849 IAU_OwnerPhnRegRVal "20.05.02";
BA_ "GenSigSendType" SG_ 849 IAU_NFCCard1RegRVal 4;
BA_ "UserSigValidity" SG_ 849 IAU_NFCCard1RegRVal 0;
BA_ "NetworkRequest" SG_ 849 IAU_NFCCard1RegRVal 0;
BA_ "NetworkRequestHoldingTime" SG_ 849 IAU_NFCCard1RegRVal 5000;
BA_ "Version" SG_ 849 IAU_NFCCard1RegRVal "17.12.08";
BA_ "GenSigSendType" SG_ 849 IAU_NFCCard2RegRVal 4;
BA_ "UserSigValidity" SG_ 849 IAU_NFCCard2RegRVal 0;
BA_ "NetworkRequest" SG_ 849 IAU_NFCCard2RegRVal 0;
BA_ "NetworkRequestHoldingTime" SG_ 849 IAU_NFCCard2RegRVal 5000;
BA_ "Version" SG_ 849 IAU_NFCCard2RegRVal "17.12.08";
BA_ "GenMsgSendType" BO_ 850 0;
BA_ "GenMsgStartDelayTime" BO_ 850 40;
BA_ "VFrameFormat" BO_ 850 14;
BA_ "Description" SG_ 850 IAU_FD_Crc5Val "The data area for CRC calculation is based on the data length (DLC) of the message DB.

The CRC shall be calculated over the entire data block (excluding the CRC bytes) including the user data, alive counter and Data ID



- CRC Polynomial (0x1021) , Initial Value : 0xFFFF, XOR value : 0x0000, Data ID : Message ID + 0xF800 

- The initial value is for CRC calculation and the message should be sent with the calculated result value. 

- The mathematical expression to 16 bit CRC polynomial is given here. G(x) = x16 + x12 + x5 + 1



<For CRC calculation of CAN-FD Msg for HS CAN domain ECUs>



- HS-CAN Messages that routed from CAN-FD domain are using 29 bit Extended CAN ID and splitted into 8 Byte Messages.

(from 1 to 4 Msgs, depending on source CAN-FD Msg¡¯s DLC)

- For splitted CAN-FD Msgs¡¯ CRC calculation, HS CAN ECUs should use source CAN-FD Msg¡¯s original STD ID. 

- The original STD ID can be read from Ext ID¡¯s 4~6th Byte.

Eg. STD 0x6AA : EXT SPLT 0x1A8[6AA]01 / 0x1A8[6AA]02 / 0x1A8[6AA]03 / 0x1A8[6AA]04 

(2~4th splitited Msgs can be omitted depending on source CAN-FD Msg¡¯s DLC)

- Aslo, HS-CAN ECUs should use merged data block (from whole splitted Msg) for CRC calculation.";
BA_ "GenSigSendType" SG_ 850 IAU_FD_Crc5Val 4;
BA_ "GenSigStartValue" SG_ 850 IAU_FD_Crc5Val 65535;
BA_ "UserSigValidity" SG_ 850 IAU_FD_Crc5Val 0;
BA_ "Version" SG_ 850 IAU_FD_Crc5Val "22.11.04";
BA_ "GenSigSendType" SG_ 850 IAU_DigitalKeyProfileRval 4;
BA_ "UserSigValidity" SG_ 850 IAU_DigitalKeyProfileRval 0;
BA_ "NetworkRequest" SG_ 850 IAU_DigitalKeyProfileRval 0;
BA_ "NetworkRequestHoldingTime" SG_ 850 IAU_DigitalKeyProfileRval 5000;
BA_ "Version" SG_ 850 IAU_DigitalKeyProfileRval "20.05.02";
BA_ "GenSigSendType" SG_ 850 IAU_SharedPhnRegStat 4;
BA_ "UserSigValidity" SG_ 850 IAU_SharedPhnRegStat 0;
BA_REL_ "GenSigTimeoutTime" BU_SG_REL_ L_DHL_FD SG_ 850 IAU_SharedPhnRegStat 1500;
BA_REL_ "GenSigTimeoutTime" BU_SG_REL_ L_DHRL_FD SG_ 850 IAU_SharedPhnRegStat 1500;
BA_REL_ "GenSigTimeoutTime" BU_SG_REL_ L_DHRR_FD SG_ 850 IAU_SharedPhnRegStat 1500;
BA_REL_ "GenSigTimeoutTime" BU_SG_REL_ L_DHR_FD SG_ 850 IAU_SharedPhnRegStat 1500;
BA_REL_ "GenSigTimeoutTime" BU_SG_REL_ L_UWB_BLE_MST_FD SG_ 850 IAU_SharedPhnRegStat 1500;
BA_REL_ "GenSigTimeoutTime" BU_SG_REL_ L_UWB_BLE_SLV_FD SG_ 850 IAU_SharedPhnRegStat 1500;
BA_REL_ "GenSigTimeoutTime" BU_SG_REL_ L_UWB_FL_FD SG_ 850 IAU_SharedPhnRegStat 1500;
BA_REL_ "GenSigTimeoutTime" BU_SG_REL_ L_UWB_FRNK_FD SG_ 850 IAU_SharedPhnRegStat 1500;
BA_REL_ "GenSigTimeoutTime" BU_SG_REL_ L_UWB_FR_FD SG_ 850 IAU_SharedPhnRegStat 1500;
BA_REL_ "GenSigTimeoutTime" BU_SG_REL_ L_UWB_RL_FD SG_ 850 IAU_SharedPhnRegStat 1500;
BA_REL_ "GenSigTimeoutTime" BU_SG_REL_ L_UWB_RR_FD SG_ 850 IAU_SharedPhnRegStat 1500;
BA_REL_ "GenSigTimeoutTime" BU_SG_REL_ L_UWB_TRNK_FD SG_ 850 IAU_SharedPhnRegStat 1500;
BA_REL_ "GenSigTimeoutTime" BU_SG_REL_ L_WPC_FD SG_ 850 IAU_SharedPhnRegStat 1500;
BA_ "NetworkRequest" SG_ 850 IAU_SharedPhnRegStat 0;
BA_ "NetworkRequestHoldingTime" SG_ 850 IAU_SharedPhnRegStat 5000;
BA_ "Version" SG_ 850 IAU_SharedPhnRegStat "20.05.02";
BA_ "Description" SG_ 850 IAU_CardKeyEnblRVal "Card Key Function Enable / Disable flag";
BA_ "GenSigSendType" SG_ 850 IAU_CardKeyEnblRVal 4;
BA_ "UserSigValidity" SG_ 850 IAU_CardKeyEnblRVal 0;
BA_REL_ "GenSigTimeoutTime" BU_SG_REL_ L_DHL_FD SG_ 850 IAU_CardKeyEnblRVal 1500;
BA_REL_ "GenSigTimeoutTime" BU_SG_REL_ L_DHRL_FD SG_ 850 IAU_CardKeyEnblRVal 1500;
BA_REL_ "GenSigTimeoutTime" BU_SG_REL_ L_DHRR_FD SG_ 850 IAU_CardKeyEnblRVal 1500;
BA_REL_ "GenSigTimeoutTime" BU_SG_REL_ L_DHR_FD SG_ 850 IAU_CardKeyEnblRVal 1500;
BA_ "NetworkRequest" SG_ 850 IAU_CardKeyEnblRVal 0;
BA_ "NetworkRequestHoldingTime" SG_ 850 IAU_CardKeyEnblRVal 5000;
BA_ "Version" SG_ 850 IAU_CardKeyEnblRVal "20.08.00";
BA_ "Description" SG_ 850 IAU_DrvDHLPhnDetect "Front Door Left Doorhandle";
BA_ "GenSigSendType" SG_ 850 IAU_DrvDHLPhnDetect 4;
BA_ "UserSigValidity" SG_ 850 IAU_DrvDHLPhnDetect 0;
BA_ "NetworkRequest" SG_ 850 IAU_DrvDHLPhnDetect 0;
BA_ "NetworkRequestHoldingTime" SG_ 850 IAU_DrvDHLPhnDetect 5000;
BA_ "Version" SG_ 850 IAU_DrvDHLPhnDetect "21.08.01";
BA_ "Description" SG_ 850 IAU_AstDHLPhnDetect "Front Right Door Handle";
BA_ "GenSigSendType" SG_ 850 IAU_AstDHLPhnDetect 4;
BA_ "UserSigValidity" SG_ 850 IAU_AstDHLPhnDetect 0;
BA_ "NetworkRequest" SG_ 850 IAU_AstDHLPhnDetect 0;
BA_ "NetworkRequestHoldingTime" SG_ 850 IAU_AstDHLPhnDetect 5000;
BA_ "Version" SG_ 850 IAU_AstDHLPhnDetect "21.08.01";
BA_ "Description" SG_ 850 IAU_RLDHLPhnDetect "Rear Left Door Handle";
BA_ "GenSigSendType" SG_ 850 IAU_RLDHLPhnDetect 4;
BA_ "UserSigValidity" SG_ 850 IAU_RLDHLPhnDetect 0;
BA_ "NetworkRequest" SG_ 850 IAU_RLDHLPhnDetect 0;
BA_ "NetworkRequestHoldingTime" SG_ 850 IAU_RLDHLPhnDetect 5000;
BA_ "Version" SG_ 850 IAU_RLDHLPhnDetect "21.08.01";
BA_ "Description" SG_ 850 IAU_RRDHLPhnDetect "Rear Right Door handle";
BA_ "GenSigSendType" SG_ 850 IAU_RRDHLPhnDetect 4;
BA_ "UserSigValidity" SG_ 850 IAU_RRDHLPhnDetect 0;
BA_ "NetworkRequest" SG_ 850 IAU_RRDHLPhnDetect 0;
BA_ "NetworkRequestHoldingTime" SG_ 850 IAU_RRDHLPhnDetect 5000;
BA_ "Version" SG_ 850 IAU_RRDHLPhnDetect "21.08.01";
BA_ "Description" SG_ 850 IAU_Manufacturer "The Manufacturer Code of IAU by HMC";
BA_ "GenSigSendType" SG_ 850 IAU_Manufacturer 4;
BA_ "UserSigValidity" SG_ 850 IAU_Manufacturer 0;
BA_ "NetworkRequest" SG_ 850 IAU_Manufacturer 0;
BA_ "NetworkRequestHoldingTime" SG_ 850 IAU_Manufacturer 5000;
BA_ "Version" SG_ 850 IAU_Manufacturer "21.07.05";
BA_ "Description" SG_ 850 IAU_VendorCode "Vendor code of IAU manufacturer";
BA_ "GenSigSendType" SG_ 850 IAU_VendorCode 4;
BA_ "UserSigValidity" SG_ 850 IAU_VendorCode 0;
BA_ "NetworkRequest" SG_ 850 IAU_VendorCode 0;
BA_ "NetworkRequestHoldingTime" SG_ 850 IAU_VendorCode 5000;
BA_ "Version" SG_ 850 IAU_VendorCode "21.07.05";
BA_ "Description" SG_ 850 IAU_FD_AlvCnt5Val "For the first transmission request for a data element the counter shall be initialized with 0 and shall be incremented by 1 for every subsequent send request. 

When the counter reaches the maximum value(0xFF), then it shall restart with 0 for the next send request";
BA_ "GenSigSendType" SG_ 850 IAU_FD_AlvCnt5Val 4;
BA_ "UserSigValidity" SG_ 850 IAU_FD_AlvCnt5Val 0;
BA_ "Version" SG_ 850 IAU_FD_AlvCnt5Val "22.11.04";
BA_ "Description" SG_ 850 IAU_Serial "Production Serial Number of IAU";
BA_ "GenSigSendType" SG_ 850 IAU_Serial 4;
BA_ "UserSigValidity" SG_ 850 IAU_Serial 0;
BA_ "NetworkRequest" SG_ 850 IAU_Serial 0;
BA_ "NetworkRequestHoldingTime" SG_ 850 IAU_Serial 5000;
BA_ "Version" SG_ 850 IAU_Serial "21.07.05";
BA_ "Description" SG_ 850 IAU_Year "The Production Year of IAU";
BA_ "GenSigSendType" SG_ 850 IAU_Year 4;
BA_ "UserSigValidity" SG_ 850 IAU_Year 0;
BA_ "NetworkRequest" SG_ 850 IAU_Year 0;
BA_ "NetworkRequestHoldingTime" SG_ 850 IAU_Year 5000;
BA_ "Version" SG_ 850 IAU_Year "21.07.05";
BA_ "Description" SG_ 850 IAU_Month "The Production Month of IAU";
BA_ "GenSigSendType" SG_ 850 IAU_Month 4;
BA_ "UserSigValidity" SG_ 850 IAU_Month 0;
BA_ "NetworkRequest" SG_ 850 IAU_Month 0;
BA_ "NetworkRequestHoldingTime" SG_ 850 IAU_Month 5000;
BA_ "Version" SG_ 850 IAU_Month "21.07.05";
BA_ "Description" SG_ 850 IAU_Date "The Production Date of IAU";
BA_ "GenSigSendType" SG_ 850 IAU_Date 4;
BA_ "UserSigValidity" SG_ 850 IAU_Date 0;
BA_ "NetworkRequest" SG_ 850 IAU_Date 0;
BA_ "NetworkRequestHoldingTime" SG_ 850 IAU_Date 5000;
BA_ "Version" SG_ 850 IAU_Date "21.07.05";
BA_ "Description" SG_ 850 IAU_SWVerMajor1 "Indicate the IAU software version as follows:

- The software version is displayed in three digits.

- The Major and Minor digits are separated by '.'

- Signal values are transmitted to ASCII codes.



¡Ø Example

IAU_SWVerMajor1 : 0x41 (HEX) -> ASCII CODE : 'A' 

IAU_SWVerMinor1 : 0x30 (HEX) -> ASCII CODE : '0'

IAU_SWVerMinor2 : 0x33 (HEX) -> ASCII CODE : '3'

=> IAU S/W Ver is displayed 'A.03'";
BA_ "GenSigSendType" SG_ 850 IAU_SWVerMajor1 4;
BA_ "UserSigValidity" SG_ 850 IAU_SWVerMajor1 0;
BA_ "Version" SG_ 850 IAU_SWVerMajor1 "20.12.04";
BA_ "Description" SG_ 850 IAU_DrvDhsRainStat "Routing signal from DHL_Rain_Sta (L-CAN)";
BA_ "GenSigSendType" SG_ 850 IAU_DrvDhsRainStat 4;
BA_ "UserSigValidity" SG_ 850 IAU_DrvDhsRainStat 0;
BA_ "Version" SG_ 850 IAU_DrvDhsRainStat "24.01.06";
BA_ "Description" SG_ 850 IAU_SWVerMinor1 "Indicate the IAU software version as follows:

- The software version is displayed in three digits.

- The Major and Minor digits are separated by '.'

- Signal values are transmitted to ASCII codes.



¡Ø Example

IAU_SWVerMajor1 : 0x41 (HEX) -> ASCII CODE : 'A' 

IAU_SWVerMinor1 : 0x30 (HEX) -> ASCII CODE : '0'

IAU_SWVerMinor2 : 0x33 (HEX) -> ASCII CODE : '3'

=> IAU S/W Ver is displayed 'A.03'";
BA_ "GenSigSendType" SG_ 850 IAU_SWVerMinor1 4;
BA_ "UserSigValidity" SG_ 850 IAU_SWVerMinor1 0;
BA_ "Version" SG_ 850 IAU_SWVerMinor1 "18.10.06";
BA_ "Description" SG_ 850 IAU_SWVerMinor2 "Indicate the IAU software version as follows:

- The software version is displayed in three digits.

- The Major and Minor digits are separated by '.'

- Signal values are transmitted to ASCII codes.



¡Ø Example

IAU_SWVerMajor1 : 0x41 (HEX) -> ASCII CODE : 'A' 

IAU_SWVerMinor1 : 0x30 (HEX) -> ASCII CODE : '0'

IAU_SWVerMinor2 : 0x33 (HEX) -> ASCII CODE : '3'

=> IAU S/W Ver is displayed 'A.03'";
BA_ "GenSigSendType" SG_ 850 IAU_SWVerMinor2 4;
BA_ "UserSigValidity" SG_ 850 IAU_SWVerMinor2 0;
BA_ "Version" SG_ 850 IAU_SWVerMinor2 "18.10.06";
BA_ "Description" SG_ 850 IAU_AstDhsRainStat "Routing signal from DHR_Rain_Sta (L-CAN)";
BA_ "GenSigSendType" SG_ 850 IAU_AstDhsRainStat 4;
BA_ "UserSigValidity" SG_ 850 IAU_AstDhsRainStat 0;
BA_ "Version" SG_ 850 IAU_AstDhsRainStat "24.01.06";
BA_ "Description" SG_ 850 IAU_RLDhsRainStat "Routing signal from DHRL_Rain_Sta (L-CAN)";
BA_ "GenSigSendType" SG_ 850 IAU_RLDhsRainStat 4;
BA_ "UserSigValidity" SG_ 850 IAU_RLDhsRainStat 0;
BA_ "Version" SG_ 850 IAU_RLDhsRainStat "24.01.06";
BA_ "Description" SG_ 850 IAU_RRDhsRainStat "Routing signal from DHRR_Rain_Sta (L-CAN)";
BA_ "GenSigSendType" SG_ 850 IAU_RRDhsRainStat 4;
BA_ "UserSigValidity" SG_ 850 IAU_RRDhsRainStat 0;
BA_ "Version" SG_ 850 IAU_RRDhsRainStat "24.01.06";
BA_ "GenMsgCycleTime" BO_ 2214592592 0;
BA_ "VFrameFormat" BO_ 2214592592 15;
BA_ "Description" SG_ 2214592592 L_BDC_FD_IAU_Crc1Val "The data area for CRC calculation is based on the data length (DLC) of the message DB.

The CRC shall be calculated over the entire data block (excluding the CRC bytes) including the user data, alive counter and Data ID



- CRC Polynomial (0x1021) , Initial Value : 0xFFFF, XOR value : 0x0000, Data ID : Message ID + 0xF800 

- The initial value is for CRC calculation and the message should be sent with the calculated result value. 

- The mathematical expression to 16 bit CRC polynomial is given here. G(x) = x16 + x12 + x5 + 1



<For CRC calculation of CAN-FD Msg for HS CAN domain ECUs>



- HS-CAN Messages that routed from CAN-FD domain are using 29 bit Extended CAN ID and splitted into 8 Byte Messages.

(from 1 to 4 Msgs, depending on source CAN-FD Msg¡¯s DLC)

- For splitted CAN-FD Msgs¡¯ CRC calculation, HS CAN ECUs should use source CAN-FD Msg¡¯s original STD ID. 

- The original STD ID can be read from Ext ID¡¯s 4~6th Byte.

Eg. STD 0x6AA : EXT SPLT 0x1A8[6AA]01 / 0x1A8[6AA]02 / 0x1A8[6AA]03 / 0x1A8[6AA]04 

(2~4th splitited Msgs can be omitted depending on source CAN-FD Msg¡¯s DLC)

- Aslo, HS-CAN ECUs should use merged data block (from whole splitted Msg) for CRC calculation.";
BA_ "GenSigSendType" SG_ 2214592592 L_BDC_FD_IAU_Crc1Val 4;
BA_ "GenSigStartValue" SG_ 2214592592 L_BDC_FD_IAU_Crc1Val 65535;
BA_ "UserSigValidity" SG_ 2214592592 L_BDC_FD_IAU_Crc1Val 3;
BA_ "Version" SG_ 2214592592 L_BDC_FD_IAU_Crc1Val "23.01.02";
BA_ "Description" SG_ 2214592592 L_BDC_FD_IAU_AlvCnt1Val "For the first transmission request for a data element the counter shall be initialized with 0 and shall be incremented by 1 for every subsequent send request. 

When the counter reaches the maximum value(0xFF), then it shall restart with 0 for the next send request";
BA_ "GenSigSendType" SG_ 2214592592 L_BDC_FD_IAU_AlvCnt1Val 4;
BA_ "UserSigValidity" SG_ 2214592592 L_BDC_FD_IAU_AlvCnt1Val 3;
BA_ "Version" SG_ 2214592592 L_BDC_FD_IAU_AlvCnt1Val "23.01.02";
BA_ "GenSigSendType" SG_ 2214592592 WPC_NFC_Deselect_Cmd 4;
BA_ "UserSigValidity" SG_ 2214592592 WPC_NFC_Deselect_Cmd 0;
BA_REL_ "GenSigTimeoutTime" BU_SG_REL_ L_WPC_FD SG_ 2214592592 WPC_NFC_Deselect_Cmd 0;
BA_ "Version" SG_ 2214592592 WPC_NFC_Deselect_Cmd "23.01.02";
BA_ "GenSigSendType" SG_ 2214592592 WPC2_NFC_Deselect_Cmd 4;
BA_ "UserSigValidity" SG_ 2214592592 WPC2_NFC_Deselect_Cmd 0;
BA_REL_ "GenSigTimeoutTime" BU_SG_REL_ L_WPC_FD SG_ 2214592592 WPC2_NFC_Deselect_Cmd 0;
BA_ "Version" SG_ 2214592592 WPC2_NFC_Deselect_Cmd "24.06.01";
BA_ "GenSigSendType" SG_ 2214592592 DHL_NFC_Deselect_Cmd 4;
BA_ "UserSigValidity" SG_ 2214592592 DHL_NFC_Deselect_Cmd 0;
BA_REL_ "GenSigTimeoutTime" BU_SG_REL_ L_DHL_FD SG_ 2214592592 DHL_NFC_Deselect_Cmd 0;
BA_ "Version" SG_ 2214592592 DHL_NFC_Deselect_Cmd "23.01.02";
BA_ "GenSigSendType" SG_ 2214592592 DHR_NFC_Deselect_Cmd 4;
BA_ "UserSigValidity" SG_ 2214592592 DHR_NFC_Deselect_Cmd 0;
BA_REL_ "GenSigTimeoutTime" BU_SG_REL_ L_DHR_FD SG_ 2214592592 DHR_NFC_Deselect_Cmd 0;
BA_ "Version" SG_ 2214592592 DHR_NFC_Deselect_Cmd "23.01.02";
BA_ "GenSigSendType" SG_ 2214592592 DHRL_NFC_Deselect_Cmd 4;
BA_ "UserSigValidity" SG_ 2214592592 DHRL_NFC_Deselect_Cmd 0;
BA_REL_ "GenSigTimeoutTime" BU_SG_REL_ L_DHRL_FD SG_ 2214592592 DHRL_NFC_Deselect_Cmd 0;
BA_ "Version" SG_ 2214592592 DHRL_NFC_Deselect_Cmd "23.06.01";
BA_ "GenSigSendType" SG_ 2214592592 DHRR_NFC_Deselect_Cmd 4;
BA_ "UserSigValidity" SG_ 2214592592 DHRR_NFC_Deselect_Cmd 0;
BA_REL_ "GenSigTimeoutTime" BU_SG_REL_ L_DHRR_FD SG_ 2214592592 DHRR_NFC_Deselect_Cmd 0;
BA_ "Version" SG_ 2214592592 DHRR_NFC_Deselect_Cmd "23.06.01";
BA_ "GenMsgSendType" BO_ 2281701456 0;
BA_ "VFrameFormat" BO_ 2281701456 15;
BA_ "Description" SG_ 2281701456 L_BDC_FD_IAU_Crc10Val "The data area for CRC calculation is based on the data length (DLC) of the message DB.

The CRC shall be calculated over the entire data block (excluding the CRC bytes) including the user data, alive counter and Data ID



- CRC Polynomial (0x1021) , Initial Value : 0xFFFF, XOR value : 0x0000, Data ID : Message ID + 0xF800 

- The initial value is for CRC calculation and the message should be sent with the calculated result value. 

- The mathematical expression to 16 bit CRC polynomial is given here. G(x) = x16 + x12 + x5 + 1



<For CRC calculation of CAN-FD Msg for HS CAN domain ECUs>



- HS-CAN Messages that routed from CAN-FD domain are using 29 bit Extended CAN ID and splitted into 8 Byte Messages.

(from 1 to 4 Msgs, depending on source CAN-FD Msg¡¯s DLC)

- For splitted CAN-FD Msgs¡¯ CRC calculation, HS CAN ECUs should use source CAN-FD Msg¡¯s original STD ID. 

- The original STD ID can be read from Ext ID¡¯s 4~6th Byte.

Eg. STD 0x6AA : EXT SPLT 0x1A8[6AA]01 / 0x1A8[6AA]02 / 0x1A8[6AA]03 / 0x1A8[6AA]04 

(2~4th splitited Msgs can be omitted depending on source CAN-FD Msg¡¯s DLC)

- Aslo, HS-CAN ECUs should use merged data block (from whole splitted Msg) for CRC calculation.";
BA_ "GenSigSendType" SG_ 2281701456 L_BDC_FD_IAU_Crc10Val 4;
BA_ "GenSigStartValue" SG_ 2281701456 L_BDC_FD_IAU_Crc10Val 65535;
BA_ "UserSigValidity" SG_ 2281701456 L_BDC_FD_IAU_Crc10Val 3;
BA_ "Version" SG_ 2281701456 L_BDC_FD_IAU_Crc10Val "23.01.02";
BA_ "Description" SG_ 2281701456 L_BDC_FD_IAU_AlvCnt10Val "For the first transmission request for a data element the counter shall be initialized with 0 and shall be incremented by 1 for every subsequent send request. 

When the counter reaches the maximum value(0xFF), then it shall restart with 0 for the next send request";
BA_ "GenSigSendType" SG_ 2281701456 L_BDC_FD_IAU_AlvCnt10Val 4;
BA_ "UserSigValidity" SG_ 2281701456 L_BDC_FD_IAU_AlvCnt10Val 3;
BA_ "Version" SG_ 2281701456 L_BDC_FD_IAU_AlvCnt10Val "23.01.02";
BA_ "GenSigSendType" SG_ 2281701456 BodyType_Sta 4;
BA_ "UserSigValidity" SG_ 2281701456 BodyType_Sta 0;
BA_REL_ "GenSigTimeoutTime" BU_SG_REL_ L_ROA_FD SG_ 2281701456 BodyType_Sta 1500;
BA_REL_ "GenSigTimeoutTime" BU_SG_REL_ L_ROA_FR_FD SG_ 2281701456 BodyType_Sta 1500;
BA_REL_ "GenSigTimeoutTime" BU_SG_REL_ L_UWB_BLE_MST_FD SG_ 2281701456 BodyType_Sta 1500;
BA_ "Version" SG_ 2281701456 BodyType_Sta "23.01.02";
BA_ "Description" SG_ 2281701456 Trunk_Tailgate_Info "Trunk and Tailgate Type";
BA_ "GenSigSendType" SG_ 2281701456 Trunk_Tailgate_Info 4;
BA_ "UserSigValidity" SG_ 2281701456 Trunk_Tailgate_Info 0;
BA_REL_ "GenSigTimeoutTime" BU_SG_REL_ L_UWB_BLE_MST_FD SG_ 2281701456 Trunk_Tailgate_Info 1500;
BA_ "Version" SG_ 2281701456 Trunk_Tailgate_Info "24.05.06";
BA_ "GenSigSendType" SG_ 2281701456 BDC_TP_CAN_Sta 4;
BA_ "UserSigValidity" SG_ 2281701456 BDC_TP_CAN_Sta 0;
BA_REL_ "GenSigTimeoutTime" BU_SG_REL_ L_DHL_FD SG_ 2281701456 BDC_TP_CAN_Sta 1500;
BA_REL_ "GenSigTimeoutTime" BU_SG_REL_ L_DHRL_FD SG_ 2281701456 BDC_TP_CAN_Sta 1500;
BA_REL_ "GenSigTimeoutTime" BU_SG_REL_ L_DHRR_FD SG_ 2281701456 BDC_TP_CAN_Sta 1500;
BA_REL_ "GenSigTimeoutTime" BU_SG_REL_ L_DHR_FD SG_ 2281701456 BDC_TP_CAN_Sta 1500;
BA_REL_ "GenSigTimeoutTime" BU_SG_REL_ L_UWB_BLE_MST_FD SG_ 2281701456 BDC_TP_CAN_Sta 1500;
BA_REL_ "GenSigTimeoutTime" BU_SG_REL_ L_UWB_BLE_SLV_FD SG_ 2281701456 BDC_TP_CAN_Sta 1500;
BA_REL_ "GenSigTimeoutTime" BU_SG_REL_ L_UWB_FL_FD SG_ 2281701456 BDC_TP_CAN_Sta 1500;
BA_REL_ "GenSigTimeoutTime" BU_SG_REL_ L_UWB_FRNK_FD SG_ 2281701456 BDC_TP_CAN_Sta 1500;
BA_REL_ "GenSigTimeoutTime" BU_SG_REL_ L_UWB_FR_FD SG_ 2281701456 BDC_TP_CAN_Sta 1500;
BA_REL_ "GenSigTimeoutTime" BU_SG_REL_ L_UWB_RL_FD SG_ 2281701456 BDC_TP_CAN_Sta 1500;
BA_REL_ "GenSigTimeoutTime" BU_SG_REL_ L_UWB_RR_FD SG_ 2281701456 BDC_TP_CAN_Sta 1500;
BA_REL_ "GenSigTimeoutTime" BU_SG_REL_ L_UWB_TRNK_FD SG_ 2281701456 BDC_TP_CAN_Sta 1500;
BA_REL_ "GenSigTimeoutTime" BU_SG_REL_ L_WPC_FD SG_ 2281701456 BDC_TP_CAN_Sta 1500;
BA_ "Version" SG_ 2281701456 BDC_TP_CAN_Sta "23.01.02";
BA_ "GenSigSendType" SG_ 2281701456 OPAdv_On_Cmd 4;
BA_ "UserSigValidity" SG_ 2281701456 OPAdv_On_Cmd 0;
BA_REL_ "GenSigTimeoutTime" BU_SG_REL_ L_UWB_BLE_MST_FD SG_ 2281701456 OPAdv_On_Cmd 1500;
BA_REL_ "GenSigTimeoutTime" BU_SG_REL_ L_UWB_BLE_SLV_FD SG_ 2281701456 OPAdv_On_Cmd 1500;
BA_REL_ "GenSigTimeoutTime" BU_SG_REL_ L_WPC_FD SG_ 2281701456 OPAdv_On_Cmd 1500;
BA_ "Version" SG_ 2281701456 OPAdv_On_Cmd "23.01.02";
BA_ "GenSigSendType" SG_ 2281701456 WPC_Device_On_Cmd 4;
BA_ "UserSigValidity" SG_ 2281701456 WPC_Device_On_Cmd 0;
BA_REL_ "GenSigTimeoutTime" BU_SG_REL_ L_WPC_FD SG_ 2281701456 WPC_Device_On_Cmd 1500;
BA_ "Version" SG_ 2281701456 WPC_Device_On_Cmd "23.01.02";
BA_ "GenSigSendType" SG_ 2281701456 RgnTyp_Opt 4;
BA_ "UserSigValidity" SG_ 2281701456 RgnTyp_Opt 0;
BA_REL_ "GenSigTimeoutTime" BU_SG_REL_ L_ROA_FD SG_ 2281701456 RgnTyp_Opt 1500;
BA_REL_ "GenSigTimeoutTime" BU_SG_REL_ L_ROA_FR_FD SG_ 2281701456 RgnTyp_Opt 1500;
BA_REL_ "GenSigTimeoutTime" BU_SG_REL_ L_UWB_BLE_MST_FD SG_ 2281701456 RgnTyp_Opt 1500;
BA_REL_ "GenSigTimeoutTime" BU_SG_REL_ L_UWB_BLE_SLV_FD SG_ 2281701456 RgnTyp_Opt 1500;
BA_ "Version" SG_ 2281701456 RgnTyp_Opt "23.02.02";
BA_ "Description" SG_ 2281701456 SunRoofTyp_Opt "Optional signal for sunroof system with voice control function (C_SunroofOpt)

BDC transmits 0x1 only when LIN communication type Panorama Roof or Panorama Roof with Rear blind is applied. (Others are sent as 0x0)";
BA_ "GenSigSendType" SG_ 2281701456 SunRoofTyp_Opt 4;
BA_ "UserSigValidity" SG_ 2281701456 SunRoofTyp_Opt 0;
BA_REL_ "GenSigTimeoutTime" BU_SG_REL_ L_ROA_FD SG_ 2281701456 SunRoofTyp_Opt 1500;
BA_REL_ "GenSigTimeoutTime" BU_SG_REL_ L_ROA_FR_FD SG_ 2281701456 SunRoofTyp_Opt 1500;
BA_REL_ "GenSigTimeoutTime" BU_SG_REL_ L_UWB_BLE_MST_FD SG_ 2281701456 SunRoofTyp_Opt 1500;
BA_ "Version" SG_ 2281701456 SunRoofTyp_Opt "23.06.01";
BA_ "Description" SG_ 2281701456 BDC_RSPA_DKID "The DK ID  which operate  RSPA control";
BA_ "GenSigSendType" SG_ 2281701456 BDC_RSPA_DKID 4;
BA_ "TimeoutValue" SG_ 2281701456 BDC_RSPA_DKID "0x0";
BA_ "UserSigValidity" SG_ 2281701456 BDC_RSPA_DKID 0;
BA_REL_ "GenSigTimeoutTime" BU_SG_REL_ L_UWB_BLE_MST_FD SG_ 2281701456 BDC_RSPA_DKID 1500;
BA_REL_ "GenSigTimeoutTime" BU_SG_REL_ L_UWB_BLE_SLV_FD SG_ 2281701456 BDC_RSPA_DKID 1500;
BA_ "NetworkRequest" SG_ 2281701456 BDC_RSPA_DKID 0;
BA_ "Version" SG_ 2281701456 BDC_RSPA_DKID "23.11.00";
BA_ "GenMsgCycleTime" BO_ 2348810500 0;
BA_ "GenMsgCycleTimeFast" BO_ 2348810500 0;
BA_ "GenMsgNrOfRepetition" BO_ 2348810500 0;
BA_ "GenMsgILSupport" BO_ 2348810500 0;
BA_ "TpMessage" BO_ 2348810500 1;
BA_ "TpTxIndex" BO_ 2348810500 272;
BA_ "VFrameFormat" BO_ 2348810500 15;
BA_ "Description" SG_ 2348810500 L_TP_BDC_FD_L_WPC_FD_Byte0 "TP Index : 272";
BA_ "UsrSigPurpose" SG_ 2348810500 L_TP_BDC_FD_L_WPC_FD_Byte0 9;
BA_ "UserSigValidity" SG_ 2348810500 L_TP_BDC_FD_L_WPC_FD_Byte0 0;
BA_REL_ "GenSigTimeoutTime" BU_SG_REL_ L_WPC_FD SG_ 2348810500 L_TP_BDC_FD_L_WPC_FD_Byte0 0;
BA_ "NetworkRequest" SG_ 2348810500 L_TP_BDC_FD_L_WPC_FD_Byte0 0;
BA_ "NetworkRequestHoldingTime" SG_ 2348810500 L_TP_BDC_FD_L_WPC_FD_Byte0 5000;
BA_ "Version" SG_ 2348810500 L_TP_BDC_FD_L_WPC_FD_Byte0 "23.01.02";
BA_ "Description" SG_ 2348810500 L_TP_BDC_FD_L_WPC_FD_Byte13 "TP Index : 272";
BA_ "UsrSigPurpose" SG_ 2348810500 L_TP_BDC_FD_L_WPC_FD_Byte13 9;
BA_ "UserSigValidity" SG_ 2348810500 L_TP_BDC_FD_L_WPC_FD_Byte13 0;
BA_REL_ "GenSigTimeoutTime" BU_SG_REL_ L_WPC_FD SG_ 2348810500 L_TP_BDC_FD_L_WPC_FD_Byte13 0;
BA_ "NetworkRequest" SG_ 2348810500 L_TP_BDC_FD_L_WPC_FD_Byte13 0;
BA_ "NetworkRequestHoldingTime" SG_ 2348810500 L_TP_BDC_FD_L_WPC_FD_Byte13 5000;
BA_ "Version" SG_ 2348810500 L_TP_BDC_FD_L_WPC_FD_Byte13 "23.01.02";
BA_ "Description" SG_ 2348810500 L_TP_BDC_FD_L_WPC_FD_Byte14 "TP Index : 272";
BA_ "UsrSigPurpose" SG_ 2348810500 L_TP_BDC_FD_L_WPC_FD_Byte14 9;
BA_ "UserSigValidity" SG_ 2348810500 L_TP_BDC_FD_L_WPC_FD_Byte14 0;
BA_REL_ "GenSigTimeoutTime" BU_SG_REL_ L_WPC_FD SG_ 2348810500 L_TP_BDC_FD_L_WPC_FD_Byte14 0;
BA_ "NetworkRequest" SG_ 2348810500 L_TP_BDC_FD_L_WPC_FD_Byte14 0;
BA_ "NetworkRequestHoldingTime" SG_ 2348810500 L_TP_BDC_FD_L_WPC_FD_Byte14 5000;
BA_ "Version" SG_ 2348810500 L_TP_BDC_FD_L_WPC_FD_Byte14 "23.01.02";
BA_ "Description" SG_ 2348810500 L_TP_BDC_FD_L_WPC_FD_Byte15 "TP Index : 272";
BA_ "UsrSigPurpose" SG_ 2348810500 L_TP_BDC_FD_L_WPC_FD_Byte15 9;
BA_ "UserSigValidity" SG_ 2348810500 L_TP_BDC_FD_L_WPC_FD_Byte15 0;
BA_REL_ "GenSigTimeoutTime" BU_SG_REL_ L_WPC_FD SG_ 2348810500 L_TP_BDC_FD_L_WPC_FD_Byte15 0;
BA_ "NetworkRequest" SG_ 2348810500 L_TP_BDC_FD_L_WPC_FD_Byte15 0;
BA_ "NetworkRequestHoldingTime" SG_ 2348810500 L_TP_BDC_FD_L_WPC_FD_Byte15 5000;
BA_ "Version" SG_ 2348810500 L_TP_BDC_FD_L_WPC_FD_Byte15 "23.01.02";
BA_ "Description" SG_ 2348810500 L_TP_BDC_FD_L_WPC_FD_Byte16 "TP Index : 272";
BA_ "UsrSigPurpose" SG_ 2348810500 L_TP_BDC_FD_L_WPC_FD_Byte16 9;
BA_ "UserSigValidity" SG_ 2348810500 L_TP_BDC_FD_L_WPC_FD_Byte16 0;
BA_REL_ "GenSigTimeoutTime" BU_SG_REL_ L_WPC_FD SG_ 2348810500 L_TP_BDC_FD_L_WPC_FD_Byte16 0;
BA_ "NetworkRequest" SG_ 2348810500 L_TP_BDC_FD_L_WPC_FD_Byte16 0;
BA_ "NetworkRequestHoldingTime" SG_ 2348810500 L_TP_BDC_FD_L_WPC_FD_Byte16 5000;
BA_ "Version" SG_ 2348810500 L_TP_BDC_FD_L_WPC_FD_Byte16 "23.01.02";
BA_ "Description" SG_ 2348810500 L_TP_BDC_FD_L_WPC_FD_Byte17 "TP Index : 272";
BA_ "UsrSigPurpose" SG_ 2348810500 L_TP_BDC_FD_L_WPC_FD_Byte17 9;
BA_ "UserSigValidity" SG_ 2348810500 L_TP_BDC_FD_L_WPC_FD_Byte17 0;
BA_REL_ "GenSigTimeoutTime" BU_SG_REL_ L_WPC_FD SG_ 2348810500 L_TP_BDC_FD_L_WPC_FD_Byte17 0;
BA_ "NetworkRequest" SG_ 2348810500 L_TP_BDC_FD_L_WPC_FD_Byte17 0;
BA_ "NetworkRequestHoldingTime" SG_ 2348810500 L_TP_BDC_FD_L_WPC_FD_Byte17 5000;
BA_ "Version" SG_ 2348810500 L_TP_BDC_FD_L_WPC_FD_Byte17 "23.01.02";
BA_ "Description" SG_ 2348810500 L_TP_BDC_FD_L_WPC_FD_Byte18 "TP Index : 272";
BA_ "UsrSigPurpose" SG_ 2348810500 L_TP_BDC_FD_L_WPC_FD_Byte18 9;
BA_ "UserSigValidity" SG_ 2348810500 L_TP_BDC_FD_L_WPC_FD_Byte18 0;
BA_REL_ "GenSigTimeoutTime" BU_SG_REL_ L_WPC_FD SG_ 2348810500 L_TP_BDC_FD_L_WPC_FD_Byte18 0;
BA_ "NetworkRequest" SG_ 2348810500 L_TP_BDC_FD_L_WPC_FD_Byte18 0;
BA_ "NetworkRequestHoldingTime" SG_ 2348810500 L_TP_BDC_FD_L_WPC_FD_Byte18 5000;
BA_ "Version" SG_ 2348810500 L_TP_BDC_FD_L_WPC_FD_Byte18 "23.01.02";
BA_ "Description" SG_ 2348810500 L_TP_BDC_FD_L_WPC_FD_Byte19 "TP Index : 272";
BA_ "UsrSigPurpose" SG_ 2348810500 L_TP_BDC_FD_L_WPC_FD_Byte19 9;
BA_ "UserSigValidity" SG_ 2348810500 L_TP_BDC_FD_L_WPC_FD_Byte19 0;
BA_REL_ "GenSigTimeoutTime" BU_SG_REL_ L_WPC_FD SG_ 2348810500 L_TP_BDC_FD_L_WPC_FD_Byte19 0;
BA_ "NetworkRequest" SG_ 2348810500 L_TP_BDC_FD_L_WPC_FD_Byte19 0;
BA_ "NetworkRequestHoldingTime" SG_ 2348810500 L_TP_BDC_FD_L_WPC_FD_Byte19 5000;
BA_ "Version" SG_ 2348810500 L_TP_BDC_FD_L_WPC_FD_Byte19 "23.01.02";
BA_ "Description" SG_ 2348810500 L_TP_BDC_FD_L_WPC_FD_Byte2 "TP Index : 272";
BA_ "UsrSigPurpose" SG_ 2348810500 L_TP_BDC_FD_L_WPC_FD_Byte2 9;
BA_ "UserSigValidity" SG_ 2348810500 L_TP_BDC_FD_L_WPC_FD_Byte2 0;
BA_REL_ "GenSigTimeoutTime" BU_SG_REL_ L_WPC_FD SG_ 2348810500 L_TP_BDC_FD_L_WPC_FD_Byte2 0;
BA_ "NetworkRequest" SG_ 2348810500 L_TP_BDC_FD_L_WPC_FD_Byte2 0;
BA_ "NetworkRequestHoldingTime" SG_ 2348810500 L_TP_BDC_FD_L_WPC_FD_Byte2 5000;
BA_ "Version" SG_ 2348810500 L_TP_BDC_FD_L_WPC_FD_Byte2 "23.01.02";
BA_ "Description" SG_ 2348810500 L_TP_BDC_FD_L_WPC_FD_Byte20 "TP Index : 272";
BA_ "UsrSigPurpose" SG_ 2348810500 L_TP_BDC_FD_L_WPC_FD_Byte20 9;
BA_ "UserSigValidity" SG_ 2348810500 L_TP_BDC_FD_L_WPC_FD_Byte20 0;
BA_REL_ "GenSigTimeoutTime" BU_SG_REL_ L_WPC_FD SG_ 2348810500 L_TP_BDC_FD_L_WPC_FD_Byte20 0;
BA_ "NetworkRequest" SG_ 2348810500 L_TP_BDC_FD_L_WPC_FD_Byte20 0;
BA_ "NetworkRequestHoldingTime" SG_ 2348810500 L_TP_BDC_FD_L_WPC_FD_Byte20 5000;
BA_ "Version" SG_ 2348810500 L_TP_BDC_FD_L_WPC_FD_Byte20 "23.01.02";
BA_ "Description" SG_ 2348810500 L_TP_BDC_FD_L_WPC_FD_Byte21 "TP Index : 272";
BA_ "UsrSigPurpose" SG_ 2348810500 L_TP_BDC_FD_L_WPC_FD_Byte21 9;
BA_ "UserSigValidity" SG_ 2348810500 L_TP_BDC_FD_L_WPC_FD_Byte21 0;
BA_REL_ "GenSigTimeoutTime" BU_SG_REL_ L_WPC_FD SG_ 2348810500 L_TP_BDC_FD_L_WPC_FD_Byte21 0;
BA_ "NetworkRequest" SG_ 2348810500 L_TP_BDC_FD_L_WPC_FD_Byte21 0;
BA_ "NetworkRequestHoldingTime" SG_ 2348810500 L_TP_BDC_FD_L_WPC_FD_Byte21 5000;
BA_ "Version" SG_ 2348810500 L_TP_BDC_FD_L_WPC_FD_Byte21 "23.01.02";
BA_ "Description" SG_ 2348810500 L_TP_BDC_FD_L_WPC_FD_Byte22 "TP Index : 272";
BA_ "UsrSigPurpose" SG_ 2348810500 L_TP_BDC_FD_L_WPC_FD_Byte22 9;
BA_ "UserSigValidity" SG_ 2348810500 L_TP_BDC_FD_L_WPC_FD_Byte22 0;
BA_REL_ "GenSigTimeoutTime" BU_SG_REL_ L_WPC_FD SG_ 2348810500 L_TP_BDC_FD_L_WPC_FD_Byte22 0;
BA_ "NetworkRequest" SG_ 2348810500 L_TP_BDC_FD_L_WPC_FD_Byte22 0;
BA_ "NetworkRequestHoldingTime" SG_ 2348810500 L_TP_BDC_FD_L_WPC_FD_Byte22 5000;
BA_ "Version" SG_ 2348810500 L_TP_BDC_FD_L_WPC_FD_Byte22 "23.01.02";
BA_ "Description" SG_ 2348810500 L_TP_BDC_FD_L_WPC_FD_Byte23 "TP Index : 272";
BA_ "UsrSigPurpose" SG_ 2348810500 L_TP_BDC_FD_L_WPC_FD_Byte23 9;
BA_ "UserSigValidity" SG_ 2348810500 L_TP_BDC_FD_L_WPC_FD_Byte23 0;
BA_REL_ "GenSigTimeoutTime" BU_SG_REL_ L_WPC_FD SG_ 2348810500 L_TP_BDC_FD_L_WPC_FD_Byte23 0;
BA_ "NetworkRequest" SG_ 2348810500 L_TP_BDC_FD_L_WPC_FD_Byte23 0;
BA_ "NetworkRequestHoldingTime" SG_ 2348810500 L_TP_BDC_FD_L_WPC_FD_Byte23 5000;
BA_ "Version" SG_ 2348810500 L_TP_BDC_FD_L_WPC_FD_Byte23 "23.01.02";
BA_ "Description" SG_ 2348810500 L_TP_BDC_FD_L_WPC_FD_Byte24 "TP Index : 272";
BA_ "UsrSigPurpose" SG_ 2348810500 L_TP_BDC_FD_L_WPC_FD_Byte24 9;
BA_ "UserSigValidity" SG_ 2348810500 L_TP_BDC_FD_L_WPC_FD_Byte24 0;
BA_REL_ "GenSigTimeoutTime" BU_SG_REL_ L_WPC_FD SG_ 2348810500 L_TP_BDC_FD_L_WPC_FD_Byte24 0;
BA_ "NetworkRequest" SG_ 2348810500 L_TP_BDC_FD_L_WPC_FD_Byte24 0;
BA_ "NetworkRequestHoldingTime" SG_ 2348810500 L_TP_BDC_FD_L_WPC_FD_Byte24 5000;
BA_ "Version" SG_ 2348810500 L_TP_BDC_FD_L_WPC_FD_Byte24 "23.01.02";
BA_ "Description" SG_ 2348810500 L_TP_BDC_FD_L_WPC_FD_Byte25 "TP Index : 272";
BA_ "UsrSigPurpose" SG_ 2348810500 L_TP_BDC_FD_L_WPC_FD_Byte25 9;
BA_ "UserSigValidity" SG_ 2348810500 L_TP_BDC_FD_L_WPC_FD_Byte25 0;
BA_REL_ "GenSigTimeoutTime" BU_SG_REL_ L_WPC_FD SG_ 2348810500 L_TP_BDC_FD_L_WPC_FD_Byte25 0;
BA_ "NetworkRequest" SG_ 2348810500 L_TP_BDC_FD_L_WPC_FD_Byte25 0;
BA_ "NetworkRequestHoldingTime" SG_ 2348810500 L_TP_BDC_FD_L_WPC_FD_Byte25 5000;
BA_ "Version" SG_ 2348810500 L_TP_BDC_FD_L_WPC_FD_Byte25 "23.01.02";
BA_ "Description" SG_ 2348810500 L_TP_BDC_FD_L_WPC_FD_Byte26 "TP Index : 272";
BA_ "UsrSigPurpose" SG_ 2348810500 L_TP_BDC_FD_L_WPC_FD_Byte26 9;
BA_ "UserSigValidity" SG_ 2348810500 L_TP_BDC_FD_L_WPC_FD_Byte26 0;
BA_REL_ "GenSigTimeoutTime" BU_SG_REL_ L_WPC_FD SG_ 2348810500 L_TP_BDC_FD_L_WPC_FD_Byte26 0;
BA_ "NetworkRequest" SG_ 2348810500 L_TP_BDC_FD_L_WPC_FD_Byte26 0;
BA_ "NetworkRequestHoldingTime" SG_ 2348810500 L_TP_BDC_FD_L_WPC_FD_Byte26 5000;
BA_ "Version" SG_ 2348810500 L_TP_BDC_FD_L_WPC_FD_Byte26 "23.01.02";
BA_ "Description" SG_ 2348810500 L_TP_BDC_FD_L_WPC_FD_Byte27 "TP Index : 272";
BA_ "UsrSigPurpose" SG_ 2348810500 L_TP_BDC_FD_L_WPC_FD_Byte27 9;
BA_ "UserSigValidity" SG_ 2348810500 L_TP_BDC_FD_L_WPC_FD_Byte27 0;
BA_REL_ "GenSigTimeoutTime" BU_SG_REL_ L_WPC_FD SG_ 2348810500 L_TP_BDC_FD_L_WPC_FD_Byte27 0;
BA_ "NetworkRequest" SG_ 2348810500 L_TP_BDC_FD_L_WPC_FD_Byte27 0;
BA_ "NetworkRequestHoldingTime" SG_ 2348810500 L_TP_BDC_FD_L_WPC_FD_Byte27 5000;
BA_ "Version" SG_ 2348810500 L_TP_BDC_FD_L_WPC_FD_Byte27 "23.01.02";
BA_ "Description" SG_ 2348810500 L_TP_BDC_FD_L_WPC_FD_Byte28 "TP Index : 272";
BA_ "UsrSigPurpose" SG_ 2348810500 L_TP_BDC_FD_L_WPC_FD_Byte28 9;
BA_ "UserSigValidity" SG_ 2348810500 L_TP_BDC_FD_L_WPC_FD_Byte28 0;
BA_REL_ "GenSigTimeoutTime" BU_SG_REL_ L_WPC_FD SG_ 2348810500 L_TP_BDC_FD_L_WPC_FD_Byte28 0;
BA_ "NetworkRequest" SG_ 2348810500 L_TP_BDC_FD_L_WPC_FD_Byte28 0;
BA_ "NetworkRequestHoldingTime" SG_ 2348810500 L_TP_BDC_FD_L_WPC_FD_Byte28 5000;
BA_ "Version" SG_ 2348810500 L_TP_BDC_FD_L_WPC_FD_Byte28 "23.01.02";
BA_ "Description" SG_ 2348810500 L_TP_BDC_FD_L_WPC_FD_Byte29 "TP Index : 272";
BA_ "UsrSigPurpose" SG_ 2348810500 L_TP_BDC_FD_L_WPC_FD_Byte29 9;
BA_ "UserSigValidity" SG_ 2348810500 L_TP_BDC_FD_L_WPC_FD_Byte29 0;
BA_REL_ "GenSigTimeoutTime" BU_SG_REL_ L_WPC_FD SG_ 2348810500 L_TP_BDC_FD_L_WPC_FD_Byte29 0;
BA_ "NetworkRequest" SG_ 2348810500 L_TP_BDC_FD_L_WPC_FD_Byte29 0;
BA_ "NetworkRequestHoldingTime" SG_ 2348810500 L_TP_BDC_FD_L_WPC_FD_Byte29 5000;
BA_ "Version" SG_ 2348810500 L_TP_BDC_FD_L_WPC_FD_Byte29 "23.01.02";
BA_ "Description" SG_ 2348810500 L_TP_BDC_FD_L_WPC_FD_Byte3 "TP Index : 272";
BA_ "UsrSigPurpose" SG_ 2348810500 L_TP_BDC_FD_L_WPC_FD_Byte3 9;
BA_ "UserSigValidity" SG_ 2348810500 L_TP_BDC_FD_L_WPC_FD_Byte3 0;
BA_REL_ "GenSigTimeoutTime" BU_SG_REL_ L_WPC_FD SG_ 2348810500 L_TP_BDC_FD_L_WPC_FD_Byte3 0;
BA_ "NetworkRequest" SG_ 2348810500 L_TP_BDC_FD_L_WPC_FD_Byte3 0;
BA_ "NetworkRequestHoldingTime" SG_ 2348810500 L_TP_BDC_FD_L_WPC_FD_Byte3 5000;
BA_ "Version" SG_ 2348810500 L_TP_BDC_FD_L_WPC_FD_Byte3 "23.01.02";
BA_ "Description" SG_ 2348810500 L_TP_BDC_FD_L_WPC_FD_Byte30 "TP Index : 272";
BA_ "UsrSigPurpose" SG_ 2348810500 L_TP_BDC_FD_L_WPC_FD_Byte30 9;
BA_ "UserSigValidity" SG_ 2348810500 L_TP_BDC_FD_L_WPC_FD_Byte30 0;
BA_REL_ "GenSigTimeoutTime" BU_SG_REL_ L_WPC_FD SG_ 2348810500 L_TP_BDC_FD_L_WPC_FD_Byte30 0;
BA_ "NetworkRequest" SG_ 2348810500 L_TP_BDC_FD_L_WPC_FD_Byte30 0;
BA_ "NetworkRequestHoldingTime" SG_ 2348810500 L_TP_BDC_FD_L_WPC_FD_Byte30 5000;
BA_ "Version" SG_ 2348810500 L_TP_BDC_FD_L_WPC_FD_Byte30 "23.01.02";
BA_ "Description" SG_ 2348810500 L_TP_BDC_FD_L_WPC_FD_Byte31 "TP Index : 272";
BA_ "UsrSigPurpose" SG_ 2348810500 L_TP_BDC_FD_L_WPC_FD_Byte31 9;
BA_ "UserSigValidity" SG_ 2348810500 L_TP_BDC_FD_L_WPC_FD_Byte31 0;
BA_REL_ "GenSigTimeoutTime" BU_SG_REL_ L_WPC_FD SG_ 2348810500 L_TP_BDC_FD_L_WPC_FD_Byte31 0;
BA_ "NetworkRequest" SG_ 2348810500 L_TP_BDC_FD_L_WPC_FD_Byte31 0;
BA_ "NetworkRequestHoldingTime" SG_ 2348810500 L_TP_BDC_FD_L_WPC_FD_Byte31 5000;
BA_ "Version" SG_ 2348810500 L_TP_BDC_FD_L_WPC_FD_Byte31 "23.01.02";
BA_ "Description" SG_ 2348810500 L_TP_BDC_FD_L_WPC_FD_Byte4 "TP Index : 272";
BA_ "UsrSigPurpose" SG_ 2348810500 L_TP_BDC_FD_L_WPC_FD_Byte4 9;
BA_ "UserSigValidity" SG_ 2348810500 L_TP_BDC_FD_L_WPC_FD_Byte4 0;
BA_REL_ "GenSigTimeoutTime" BU_SG_REL_ L_WPC_FD SG_ 2348810500 L_TP_BDC_FD_L_WPC_FD_Byte4 0;
BA_ "NetworkRequest" SG_ 2348810500 L_TP_BDC_FD_L_WPC_FD_Byte4 0;
BA_ "NetworkRequestHoldingTime" SG_ 2348810500 L_TP_BDC_FD_L_WPC_FD_Byte4 5000;
BA_ "Version" SG_ 2348810500 L_TP_BDC_FD_L_WPC_FD_Byte4 "23.01.02";
BA_ "Description" SG_ 2348810500 L_TP_BDC_FD_L_WPC_FD_Byte5 "TP Index : 272";
BA_ "UsrSigPurpose" SG_ 2348810500 L_TP_BDC_FD_L_WPC_FD_Byte5 9;
BA_ "UserSigValidity" SG_ 2348810500 L_TP_BDC_FD_L_WPC_FD_Byte5 0;
BA_REL_ "GenSigTimeoutTime" BU_SG_REL_ L_WPC_FD SG_ 2348810500 L_TP_BDC_FD_L_WPC_FD_Byte5 0;
BA_ "NetworkRequest" SG_ 2348810500 L_TP_BDC_FD_L_WPC_FD_Byte5 0;
BA_ "NetworkRequestHoldingTime" SG_ 2348810500 L_TP_BDC_FD_L_WPC_FD_Byte5 5000;
BA_ "Version" SG_ 2348810500 L_TP_BDC_FD_L_WPC_FD_Byte5 "23.01.02";
BA_ "Description" SG_ 2348810500 L_TP_BDC_FD_L_WPC_FD_Byte6 "TP Index : 272";
BA_ "UsrSigPurpose" SG_ 2348810500 L_TP_BDC_FD_L_WPC_FD_Byte6 9;
BA_ "UserSigValidity" SG_ 2348810500 L_TP_BDC_FD_L_WPC_FD_Byte6 0;
BA_REL_ "GenSigTimeoutTime" BU_SG_REL_ L_WPC_FD SG_ 2348810500 L_TP_BDC_FD_L_WPC_FD_Byte6 0;
BA_ "NetworkRequest" SG_ 2348810500 L_TP_BDC_FD_L_WPC_FD_Byte6 0;
BA_ "NetworkRequestHoldingTime" SG_ 2348810500 L_TP_BDC_FD_L_WPC_FD_Byte6 5000;
BA_ "Version" SG_ 2348810500 L_TP_BDC_FD_L_WPC_FD_Byte6 "23.01.02";
BA_ "Description" SG_ 2348810500 L_TP_BDC_FD_L_WPC_FD_Byte7 "TP Index : 272";
BA_ "UsrSigPurpose" SG_ 2348810500 L_TP_BDC_FD_L_WPC_FD_Byte7 9;
BA_ "UserSigValidity" SG_ 2348810500 L_TP_BDC_FD_L_WPC_FD_Byte7 0;
BA_REL_ "GenSigTimeoutTime" BU_SG_REL_ L_WPC_FD SG_ 2348810500 L_TP_BDC_FD_L_WPC_FD_Byte7 0;
BA_ "NetworkRequest" SG_ 2348810500 L_TP_BDC_FD_L_WPC_FD_Byte7 0;
BA_ "NetworkRequestHoldingTime" SG_ 2348810500 L_TP_BDC_FD_L_WPC_FD_Byte7 5000;
BA_ "Version" SG_ 2348810500 L_TP_BDC_FD_L_WPC_FD_Byte7 "23.01.02";
BA_ "Description" SG_ 2348810500 L_TP_BDC_FD_L_WPC_FD_Byte8 "TP Index : 272";
BA_ "UsrSigPurpose" SG_ 2348810500 L_TP_BDC_FD_L_WPC_FD_Byte8 9;
BA_ "UserSigValidity" SG_ 2348810500 L_TP_BDC_FD_L_WPC_FD_Byte8 0;
BA_REL_ "GenSigTimeoutTime" BU_SG_REL_ L_WPC_FD SG_ 2348810500 L_TP_BDC_FD_L_WPC_FD_Byte8 0;
BA_ "NetworkRequest" SG_ 2348810500 L_TP_BDC_FD_L_WPC_FD_Byte8 0;
BA_ "NetworkRequestHoldingTime" SG_ 2348810500 L_TP_BDC_FD_L_WPC_FD_Byte8 5000;
BA_ "Version" SG_ 2348810500 L_TP_BDC_FD_L_WPC_FD_Byte8 "23.01.02";
BA_ "Description" SG_ 2348810500 L_TP_BDC_FD_L_WPC_FD_Byte9 "TP Index : 272";
BA_ "UsrSigPurpose" SG_ 2348810500 L_TP_BDC_FD_L_WPC_FD_Byte9 9;
BA_ "UserSigValidity" SG_ 2348810500 L_TP_BDC_FD_L_WPC_FD_Byte9 0;
BA_REL_ "GenSigTimeoutTime" BU_SG_REL_ L_WPC_FD SG_ 2348810500 L_TP_BDC_FD_L_WPC_FD_Byte9 0;
BA_ "NetworkRequest" SG_ 2348810500 L_TP_BDC_FD_L_WPC_FD_Byte9 0;
BA_ "NetworkRequestHoldingTime" SG_ 2348810500 L_TP_BDC_FD_L_WPC_FD_Byte9 5000;
BA_ "Version" SG_ 2348810500 L_TP_BDC_FD_L_WPC_FD_Byte9 "23.01.02";
BA_ "Description" SG_ 2348810500 L_TP_BDC_FD_L_WPC_FD_Byte1 "TP Index : 272";
BA_ "UsrSigPurpose" SG_ 2348810500 L_TP_BDC_FD_L_WPC_FD_Byte1 9;
BA_ "UserSigValidity" SG_ 2348810500 L_TP_BDC_FD_L_WPC_FD_Byte1 0;
BA_REL_ "GenSigTimeoutTime" BU_SG_REL_ L_WPC_FD SG_ 2348810500 L_TP_BDC_FD_L_WPC_FD_Byte1 0;
BA_ "NetworkRequest" SG_ 2348810500 L_TP_BDC_FD_L_WPC_FD_Byte1 0;
BA_ "NetworkRequestHoldingTime" SG_ 2348810500 L_TP_BDC_FD_L_WPC_FD_Byte1 5000;
BA_ "Version" SG_ 2348810500 L_TP_BDC_FD_L_WPC_FD_Byte1 "23.01.02";
BA_ "Description" SG_ 2348810500 L_TP_BDC_FD_L_WPC_FD_Byte10 "TP Index : 272";
BA_ "UsrSigPurpose" SG_ 2348810500 L_TP_BDC_FD_L_WPC_FD_Byte10 9;
BA_ "UserSigValidity" SG_ 2348810500 L_TP_BDC_FD_L_WPC_FD_Byte10 0;
BA_REL_ "GenSigTimeoutTime" BU_SG_REL_ L_WPC_FD SG_ 2348810500 L_TP_BDC_FD_L_WPC_FD_Byte10 0;
BA_ "NetworkRequest" SG_ 2348810500 L_TP_BDC_FD_L_WPC_FD_Byte10 0;
BA_ "NetworkRequestHoldingTime" SG_ 2348810500 L_TP_BDC_FD_L_WPC_FD_Byte10 5000;
BA_ "Version" SG_ 2348810500 L_TP_BDC_FD_L_WPC_FD_Byte10 "23.01.02";
BA_ "Description" SG_ 2348810500 L_TP_BDC_FD_L_WPC_FD_Byte11 "TP Index : 272";
BA_ "UsrSigPurpose" SG_ 2348810500 L_TP_BDC_FD_L_WPC_FD_Byte11 9;
BA_ "UserSigValidity" SG_ 2348810500 L_TP_BDC_FD_L_WPC_FD_Byte11 0;
BA_REL_ "GenSigTimeoutTime" BU_SG_REL_ L_WPC_FD SG_ 2348810500 L_TP_BDC_FD_L_WPC_FD_Byte11 0;
BA_ "NetworkRequest" SG_ 2348810500 L_TP_BDC_FD_L_WPC_FD_Byte11 0;
BA_ "NetworkRequestHoldingTime" SG_ 2348810500 L_TP_BDC_FD_L_WPC_FD_Byte11 5000;
BA_ "Version" SG_ 2348810500 L_TP_BDC_FD_L_WPC_FD_Byte11 "23.01.02";
BA_ "Description" SG_ 2348810500 L_TP_BDC_FD_L_WPC_FD_Byte12 "TP Index : 272";
BA_ "UsrSigPurpose" SG_ 2348810500 L_TP_BDC_FD_L_WPC_FD_Byte12 9;
BA_ "UserSigValidity" SG_ 2348810500 L_TP_BDC_FD_L_WPC_FD_Byte12 0;
BA_REL_ "GenSigTimeoutTime" BU_SG_REL_ L_WPC_FD SG_ 2348810500 L_TP_BDC_FD_L_WPC_FD_Byte12 0;
BA_ "NetworkRequest" SG_ 2348810500 L_TP_BDC_FD_L_WPC_FD_Byte12 0;
BA_ "NetworkRequestHoldingTime" SG_ 2348810500 L_TP_BDC_FD_L_WPC_FD_Byte12 5000;
BA_ "Version" SG_ 2348810500 L_TP_BDC_FD_L_WPC_FD_Byte12 "23.01.02";
BA_ "GenMsgCycleTime" BO_ 2348810501 0;
BA_ "GenMsgCycleTimeFast" BO_ 2348810501 0;
BA_ "GenMsgNrOfRepetition" BO_ 2348810501 0;
BA_ "GenMsgILSupport" BO_ 2348810501 0;
BA_ "TpMessage" BO_ 2348810501 1;
BA_ "TpTxIndex" BO_ 2348810501 272;
BA_ "VFrameFormat" BO_ 2348810501 15;
BA_ "Description" SG_ 2348810501 L_TP_L_WPC_FD_BDC_FD_Byte0 "TP Index : 272";
BA_ "UsrSigPurpose" SG_ 2348810501 L_TP_L_WPC_FD_BDC_FD_Byte0 9;
BA_ "UserSigValidity" SG_ 2348810501 L_TP_L_WPC_FD_BDC_FD_Byte0 0;
BA_REL_ "GenSigTimeoutTime" BU_SG_REL_ GW_BDC_FD SG_ 2348810501 L_TP_L_WPC_FD_BDC_FD_Byte0 0;
BA_ "NetworkRequest" SG_ 2348810501 L_TP_L_WPC_FD_BDC_FD_Byte0 0;
BA_ "NetworkRequestHoldingTime" SG_ 2348810501 L_TP_L_WPC_FD_BDC_FD_Byte0 5000;
BA_ "Version" SG_ 2348810501 L_TP_L_WPC_FD_BDC_FD_Byte0 "23.01.02";
BA_ "Description" SG_ 2348810501 L_TP_L_WPC_FD_BDC_FD_Byte13 "TP Index : 272";
BA_ "UsrSigPurpose" SG_ 2348810501 L_TP_L_WPC_FD_BDC_FD_Byte13 9;
BA_ "UserSigValidity" SG_ 2348810501 L_TP_L_WPC_FD_BDC_FD_Byte13 0;
BA_REL_ "GenSigTimeoutTime" BU_SG_REL_ GW_BDC_FD SG_ 2348810501 L_TP_L_WPC_FD_BDC_FD_Byte13 0;
BA_ "NetworkRequest" SG_ 2348810501 L_TP_L_WPC_FD_BDC_FD_Byte13 0;
BA_ "NetworkRequestHoldingTime" SG_ 2348810501 L_TP_L_WPC_FD_BDC_FD_Byte13 5000;
BA_ "Version" SG_ 2348810501 L_TP_L_WPC_FD_BDC_FD_Byte13 "23.01.02";
BA_ "Description" SG_ 2348810501 L_TP_L_WPC_FD_BDC_FD_Byte14 "TP Index : 272";
BA_ "UsrSigPurpose" SG_ 2348810501 L_TP_L_WPC_FD_BDC_FD_Byte14 9;
BA_ "UserSigValidity" SG_ 2348810501 L_TP_L_WPC_FD_BDC_FD_Byte14 0;
BA_REL_ "GenSigTimeoutTime" BU_SG_REL_ GW_BDC_FD SG_ 2348810501 L_TP_L_WPC_FD_BDC_FD_Byte14 0;
BA_ "NetworkRequest" SG_ 2348810501 L_TP_L_WPC_FD_BDC_FD_Byte14 0;
BA_ "NetworkRequestHoldingTime" SG_ 2348810501 L_TP_L_WPC_FD_BDC_FD_Byte14 5000;
BA_ "Version" SG_ 2348810501 L_TP_L_WPC_FD_BDC_FD_Byte14 "23.01.02";
BA_ "Description" SG_ 2348810501 L_TP_L_WPC_FD_BDC_FD_Byte15 "TP Index : 272";
BA_ "UsrSigPurpose" SG_ 2348810501 L_TP_L_WPC_FD_BDC_FD_Byte15 9;
BA_ "UserSigValidity" SG_ 2348810501 L_TP_L_WPC_FD_BDC_FD_Byte15 0;
BA_REL_ "GenSigTimeoutTime" BU_SG_REL_ GW_BDC_FD SG_ 2348810501 L_TP_L_WPC_FD_BDC_FD_Byte15 0;
BA_ "NetworkRequest" SG_ 2348810501 L_TP_L_WPC_FD_BDC_FD_Byte15 0;
BA_ "NetworkRequestHoldingTime" SG_ 2348810501 L_TP_L_WPC_FD_BDC_FD_Byte15 5000;
BA_ "Version" SG_ 2348810501 L_TP_L_WPC_FD_BDC_FD_Byte15 "23.01.02";
BA_ "Description" SG_ 2348810501 L_TP_L_WPC_FD_BDC_FD_Byte16 "TP Index : 272";
BA_ "UsrSigPurpose" SG_ 2348810501 L_TP_L_WPC_FD_BDC_FD_Byte16 9;
BA_ "UserSigValidity" SG_ 2348810501 L_TP_L_WPC_FD_BDC_FD_Byte16 0;
BA_REL_ "GenSigTimeoutTime" BU_SG_REL_ GW_BDC_FD SG_ 2348810501 L_TP_L_WPC_FD_BDC_FD_Byte16 0;
BA_ "NetworkRequest" SG_ 2348810501 L_TP_L_WPC_FD_BDC_FD_Byte16 0;
BA_ "NetworkRequestHoldingTime" SG_ 2348810501 L_TP_L_WPC_FD_BDC_FD_Byte16 5000;
BA_ "Version" SG_ 2348810501 L_TP_L_WPC_FD_BDC_FD_Byte16 "23.01.02";
BA_ "Description" SG_ 2348810501 L_TP_L_WPC_FD_BDC_FD_Byte17 "TP Index : 272";
BA_ "UsrSigPurpose" SG_ 2348810501 L_TP_L_WPC_FD_BDC_FD_Byte17 9;
BA_ "UserSigValidity" SG_ 2348810501 L_TP_L_WPC_FD_BDC_FD_Byte17 0;
BA_REL_ "GenSigTimeoutTime" BU_SG_REL_ GW_BDC_FD SG_ 2348810501 L_TP_L_WPC_FD_BDC_FD_Byte17 0;
BA_ "NetworkRequest" SG_ 2348810501 L_TP_L_WPC_FD_BDC_FD_Byte17 0;
BA_ "NetworkRequestHoldingTime" SG_ 2348810501 L_TP_L_WPC_FD_BDC_FD_Byte17 5000;
BA_ "Version" SG_ 2348810501 L_TP_L_WPC_FD_BDC_FD_Byte17 "23.01.02";
BA_ "Description" SG_ 2348810501 L_TP_L_WPC_FD_BDC_FD_Byte18 "TP Index : 272";
BA_ "UsrSigPurpose" SG_ 2348810501 L_TP_L_WPC_FD_BDC_FD_Byte18 9;
BA_ "UserSigValidity" SG_ 2348810501 L_TP_L_WPC_FD_BDC_FD_Byte18 0;
BA_REL_ "GenSigTimeoutTime" BU_SG_REL_ GW_BDC_FD SG_ 2348810501 L_TP_L_WPC_FD_BDC_FD_Byte18 0;
BA_ "NetworkRequest" SG_ 2348810501 L_TP_L_WPC_FD_BDC_FD_Byte18 0;
BA_ "NetworkRequestHoldingTime" SG_ 2348810501 L_TP_L_WPC_FD_BDC_FD_Byte18 5000;
BA_ "Version" SG_ 2348810501 L_TP_L_WPC_FD_BDC_FD_Byte18 "23.01.02";
BA_ "Description" SG_ 2348810501 L_TP_L_WPC_FD_BDC_FD_Byte19 "TP Index : 272";
BA_ "UsrSigPurpose" SG_ 2348810501 L_TP_L_WPC_FD_BDC_FD_Byte19 9;
BA_ "UserSigValidity" SG_ 2348810501 L_TP_L_WPC_FD_BDC_FD_Byte19 0;
BA_REL_ "GenSigTimeoutTime" BU_SG_REL_ GW_BDC_FD SG_ 2348810501 L_TP_L_WPC_FD_BDC_FD_Byte19 0;
BA_ "NetworkRequest" SG_ 2348810501 L_TP_L_WPC_FD_BDC_FD_Byte19 0;
BA_ "NetworkRequestHoldingTime" SG_ 2348810501 L_TP_L_WPC_FD_BDC_FD_Byte19 5000;
BA_ "Version" SG_ 2348810501 L_TP_L_WPC_FD_BDC_FD_Byte19 "23.01.02";
BA_ "Description" SG_ 2348810501 L_TP_L_WPC_FD_BDC_FD_Byte2 "TP Index : 272";
BA_ "UsrSigPurpose" SG_ 2348810501 L_TP_L_WPC_FD_BDC_FD_Byte2 9;
BA_ "UserSigValidity" SG_ 2348810501 L_TP_L_WPC_FD_BDC_FD_Byte2 0;
BA_REL_ "GenSigTimeoutTime" BU_SG_REL_ GW_BDC_FD SG_ 2348810501 L_TP_L_WPC_FD_BDC_FD_Byte2 0;
BA_ "NetworkRequest" SG_ 2348810501 L_TP_L_WPC_FD_BDC_FD_Byte2 0;
BA_ "NetworkRequestHoldingTime" SG_ 2348810501 L_TP_L_WPC_FD_BDC_FD_Byte2 5000;
BA_ "Version" SG_ 2348810501 L_TP_L_WPC_FD_BDC_FD_Byte2 "23.01.02";
BA_ "Description" SG_ 2348810501 L_TP_L_WPC_FD_BDC_FD_Byte20 "TP Index : 272";
BA_ "UsrSigPurpose" SG_ 2348810501 L_TP_L_WPC_FD_BDC_FD_Byte20 9;
BA_ "UserSigValidity" SG_ 2348810501 L_TP_L_WPC_FD_BDC_FD_Byte20 0;
BA_REL_ "GenSigTimeoutTime" BU_SG_REL_ GW_BDC_FD SG_ 2348810501 L_TP_L_WPC_FD_BDC_FD_Byte20 0;
BA_ "NetworkRequest" SG_ 2348810501 L_TP_L_WPC_FD_BDC_FD_Byte20 0;
BA_ "NetworkRequestHoldingTime" SG_ 2348810501 L_TP_L_WPC_FD_BDC_FD_Byte20 5000;
BA_ "Version" SG_ 2348810501 L_TP_L_WPC_FD_BDC_FD_Byte20 "23.01.02";
BA_ "Description" SG_ 2348810501 L_TP_L_WPC_FD_BDC_FD_Byte21 "TP Index : 272";
BA_ "UsrSigPurpose" SG_ 2348810501 L_TP_L_WPC_FD_BDC_FD_Byte21 9;
BA_ "UserSigValidity" SG_ 2348810501 L_TP_L_WPC_FD_BDC_FD_Byte21 0;
BA_REL_ "GenSigTimeoutTime" BU_SG_REL_ GW_BDC_FD SG_ 2348810501 L_TP_L_WPC_FD_BDC_FD_Byte21 0;
BA_ "NetworkRequest" SG_ 2348810501 L_TP_L_WPC_FD_BDC_FD_Byte21 0;
BA_ "NetworkRequestHoldingTime" SG_ 2348810501 L_TP_L_WPC_FD_BDC_FD_Byte21 5000;
BA_ "Version" SG_ 2348810501 L_TP_L_WPC_FD_BDC_FD_Byte21 "23.01.02";
BA_ "Description" SG_ 2348810501 L_TP_L_WPC_FD_BDC_FD_Byte22 "TP Index : 272";
BA_ "UsrSigPurpose" SG_ 2348810501 L_TP_L_WPC_FD_BDC_FD_Byte22 9;
BA_ "UserSigValidity" SG_ 2348810501 L_TP_L_WPC_FD_BDC_FD_Byte22 0;
BA_REL_ "GenSigTimeoutTime" BU_SG_REL_ GW_BDC_FD SG_ 2348810501 L_TP_L_WPC_FD_BDC_FD_Byte22 0;
BA_ "NetworkRequest" SG_ 2348810501 L_TP_L_WPC_FD_BDC_FD_Byte22 0;
BA_ "NetworkRequestHoldingTime" SG_ 2348810501 L_TP_L_WPC_FD_BDC_FD_Byte22 5000;
BA_ "Version" SG_ 2348810501 L_TP_L_WPC_FD_BDC_FD_Byte22 "23.01.02";
BA_ "Description" SG_ 2348810501 L_TP_L_WPC_FD_BDC_FD_Byte23 "TP Index : 272";
BA_ "UsrSigPurpose" SG_ 2348810501 L_TP_L_WPC_FD_BDC_FD_Byte23 9;
BA_ "UserSigValidity" SG_ 2348810501 L_TP_L_WPC_FD_BDC_FD_Byte23 0;
BA_REL_ "GenSigTimeoutTime" BU_SG_REL_ GW_BDC_FD SG_ 2348810501 L_TP_L_WPC_FD_BDC_FD_Byte23 0;
BA_ "NetworkRequest" SG_ 2348810501 L_TP_L_WPC_FD_BDC_FD_Byte23 0;
BA_ "NetworkRequestHoldingTime" SG_ 2348810501 L_TP_L_WPC_FD_BDC_FD_Byte23 5000;
BA_ "Version" SG_ 2348810501 L_TP_L_WPC_FD_BDC_FD_Byte23 "23.01.02";
BA_ "Description" SG_ 2348810501 L_TP_L_WPC_FD_BDC_FD_Byte24 "TP Index : 272";
BA_ "UsrSigPurpose" SG_ 2348810501 L_TP_L_WPC_FD_BDC_FD_Byte24 9;
BA_ "UserSigValidity" SG_ 2348810501 L_TP_L_WPC_FD_BDC_FD_Byte24 0;
BA_REL_ "GenSigTimeoutTime" BU_SG_REL_ GW_BDC_FD SG_ 2348810501 L_TP_L_WPC_FD_BDC_FD_Byte24 0;
BA_ "NetworkRequest" SG_ 2348810501 L_TP_L_WPC_FD_BDC_FD_Byte24 0;
BA_ "NetworkRequestHoldingTime" SG_ 2348810501 L_TP_L_WPC_FD_BDC_FD_Byte24 5000;
BA_ "Version" SG_ 2348810501 L_TP_L_WPC_FD_BDC_FD_Byte24 "23.01.02";
BA_ "Description" SG_ 2348810501 L_TP_L_WPC_FD_BDC_FD_Byte25 "TP Index : 272";
BA_ "UsrSigPurpose" SG_ 2348810501 L_TP_L_WPC_FD_BDC_FD_Byte25 9;
BA_ "UserSigValidity" SG_ 2348810501 L_TP_L_WPC_FD_BDC_FD_Byte25 0;
BA_REL_ "GenSigTimeoutTime" BU_SG_REL_ GW_BDC_FD SG_ 2348810501 L_TP_L_WPC_FD_BDC_FD_Byte25 0;
BA_ "NetworkRequest" SG_ 2348810501 L_TP_L_WPC_FD_BDC_FD_Byte25 0;
BA_ "NetworkRequestHoldingTime" SG_ 2348810501 L_TP_L_WPC_FD_BDC_FD_Byte25 5000;
BA_ "Version" SG_ 2348810501 L_TP_L_WPC_FD_BDC_FD_Byte25 "23.01.02";
BA_ "Description" SG_ 2348810501 L_TP_L_WPC_FD_BDC_FD_Byte26 "TP Index : 272";
BA_ "UsrSigPurpose" SG_ 2348810501 L_TP_L_WPC_FD_BDC_FD_Byte26 9;
BA_ "UserSigValidity" SG_ 2348810501 L_TP_L_WPC_FD_BDC_FD_Byte26 0;
BA_REL_ "GenSigTimeoutTime" BU_SG_REL_ GW_BDC_FD SG_ 2348810501 L_TP_L_WPC_FD_BDC_FD_Byte26 0;
BA_ "NetworkRequest" SG_ 2348810501 L_TP_L_WPC_FD_BDC_FD_Byte26 0;
BA_ "NetworkRequestHoldingTime" SG_ 2348810501 L_TP_L_WPC_FD_BDC_FD_Byte26 5000;
BA_ "Version" SG_ 2348810501 L_TP_L_WPC_FD_BDC_FD_Byte26 "23.01.02";
BA_ "Description" SG_ 2348810501 L_TP_L_WPC_FD_BDC_FD_Byte27 "TP Index : 272";
BA_ "UsrSigPurpose" SG_ 2348810501 L_TP_L_WPC_FD_BDC_FD_Byte27 9;
BA_ "UserSigValidity" SG_ 2348810501 L_TP_L_WPC_FD_BDC_FD_Byte27 0;
BA_REL_ "GenSigTimeoutTime" BU_SG_REL_ GW_BDC_FD SG_ 2348810501 L_TP_L_WPC_FD_BDC_FD_Byte27 0;
BA_ "NetworkRequest" SG_ 2348810501 L_TP_L_WPC_FD_BDC_FD_Byte27 0;
BA_ "NetworkRequestHoldingTime" SG_ 2348810501 L_TP_L_WPC_FD_BDC_FD_Byte27 5000;
BA_ "Version" SG_ 2348810501 L_TP_L_WPC_FD_BDC_FD_Byte27 "23.01.02";
BA_ "Description" SG_ 2348810501 L_TP_L_WPC_FD_BDC_FD_Byte28 "TP Index : 272";
BA_ "UsrSigPurpose" SG_ 2348810501 L_TP_L_WPC_FD_BDC_FD_Byte28 9;
BA_ "UserSigValidity" SG_ 2348810501 L_TP_L_WPC_FD_BDC_FD_Byte28 0;
BA_REL_ "GenSigTimeoutTime" BU_SG_REL_ GW_BDC_FD SG_ 2348810501 L_TP_L_WPC_FD_BDC_FD_Byte28 0;
BA_ "NetworkRequest" SG_ 2348810501 L_TP_L_WPC_FD_BDC_FD_Byte28 0;
BA_ "NetworkRequestHoldingTime" SG_ 2348810501 L_TP_L_WPC_FD_BDC_FD_Byte28 5000;
BA_ "Version" SG_ 2348810501 L_TP_L_WPC_FD_BDC_FD_Byte28 "23.01.02";
BA_ "Description" SG_ 2348810501 L_TP_L_WPC_FD_BDC_FD_Byte29 "TP Index : 272";
BA_ "UsrSigPurpose" SG_ 2348810501 L_TP_L_WPC_FD_BDC_FD_Byte29 9;
BA_ "UserSigValidity" SG_ 2348810501 L_TP_L_WPC_FD_BDC_FD_Byte29 0;
BA_REL_ "GenSigTimeoutTime" BU_SG_REL_ GW_BDC_FD SG_ 2348810501 L_TP_L_WPC_FD_BDC_FD_Byte29 0;
BA_ "NetworkRequest" SG_ 2348810501 L_TP_L_WPC_FD_BDC_FD_Byte29 0;
BA_ "NetworkRequestHoldingTime" SG_ 2348810501 L_TP_L_WPC_FD_BDC_FD_Byte29 5000;
BA_ "Version" SG_ 2348810501 L_TP_L_WPC_FD_BDC_FD_Byte29 "23.01.02";
BA_ "Description" SG_ 2348810501 L_TP_L_WPC_FD_BDC_FD_Byte3 "TP Index : 272";
BA_ "UsrSigPurpose" SG_ 2348810501 L_TP_L_WPC_FD_BDC_FD_Byte3 9;
BA_ "UserSigValidity" SG_ 2348810501 L_TP_L_WPC_FD_BDC_FD_Byte3 0;
BA_REL_ "GenSigTimeoutTime" BU_SG_REL_ GW_BDC_FD SG_ 2348810501 L_TP_L_WPC_FD_BDC_FD_Byte3 0;
BA_ "NetworkRequest" SG_ 2348810501 L_TP_L_WPC_FD_BDC_FD_Byte3 0;
BA_ "NetworkRequestHoldingTime" SG_ 2348810501 L_TP_L_WPC_FD_BDC_FD_Byte3 5000;
BA_ "Version" SG_ 2348810501 L_TP_L_WPC_FD_BDC_FD_Byte3 "23.01.02";
BA_ "Description" SG_ 2348810501 L_TP_L_WPC_FD_BDC_FD_Byte30 "TP Index : 272";
BA_ "UsrSigPurpose" SG_ 2348810501 L_TP_L_WPC_FD_BDC_FD_Byte30 9;
BA_ "UserSigValidity" SG_ 2348810501 L_TP_L_WPC_FD_BDC_FD_Byte30 0;
BA_REL_ "GenSigTimeoutTime" BU_SG_REL_ GW_BDC_FD SG_ 2348810501 L_TP_L_WPC_FD_BDC_FD_Byte30 0;
BA_ "NetworkRequest" SG_ 2348810501 L_TP_L_WPC_FD_BDC_FD_Byte30 0;
BA_ "NetworkRequestHoldingTime" SG_ 2348810501 L_TP_L_WPC_FD_BDC_FD_Byte30 5000;
BA_ "Version" SG_ 2348810501 L_TP_L_WPC_FD_BDC_FD_Byte30 "23.01.02";
BA_ "Description" SG_ 2348810501 L_TP_L_WPC_FD_BDC_FD_Byte31 "TP Index : 272";
BA_ "UsrSigPurpose" SG_ 2348810501 L_TP_L_WPC_FD_BDC_FD_Byte31 9;
BA_ "UserSigValidity" SG_ 2348810501 L_TP_L_WPC_FD_BDC_FD_Byte31 0;
BA_REL_ "GenSigTimeoutTime" BU_SG_REL_ GW_BDC_FD SG_ 2348810501 L_TP_L_WPC_FD_BDC_FD_Byte31 0;
BA_ "NetworkRequest" SG_ 2348810501 L_TP_L_WPC_FD_BDC_FD_Byte31 0;
BA_ "NetworkRequestHoldingTime" SG_ 2348810501 L_TP_L_WPC_FD_BDC_FD_Byte31 5000;
BA_ "Version" SG_ 2348810501 L_TP_L_WPC_FD_BDC_FD_Byte31 "23.01.02";
BA_ "Description" SG_ 2348810501 L_TP_L_WPC_FD_BDC_FD_Byte4 "TP Index : 272";
BA_ "UsrSigPurpose" SG_ 2348810501 L_TP_L_WPC_FD_BDC_FD_Byte4 9;
BA_ "UserSigValidity" SG_ 2348810501 L_TP_L_WPC_FD_BDC_FD_Byte4 0;
BA_REL_ "GenSigTimeoutTime" BU_SG_REL_ GW_BDC_FD SG_ 2348810501 L_TP_L_WPC_FD_BDC_FD_Byte4 0;
BA_ "NetworkRequest" SG_ 2348810501 L_TP_L_WPC_FD_BDC_FD_Byte4 0;
BA_ "NetworkRequestHoldingTime" SG_ 2348810501 L_TP_L_WPC_FD_BDC_FD_Byte4 5000;
BA_ "Version" SG_ 2348810501 L_TP_L_WPC_FD_BDC_FD_Byte4 "23.01.02";
BA_ "Description" SG_ 2348810501 L_TP_L_WPC_FD_BDC_FD_Byte5 "TP Index : 272";
BA_ "UsrSigPurpose" SG_ 2348810501 L_TP_L_WPC_FD_BDC_FD_Byte5 9;
BA_ "UserSigValidity" SG_ 2348810501 L_TP_L_WPC_FD_BDC_FD_Byte5 0;
BA_REL_ "GenSigTimeoutTime" BU_SG_REL_ GW_BDC_FD SG_ 2348810501 L_TP_L_WPC_FD_BDC_FD_Byte5 0;
BA_ "NetworkRequest" SG_ 2348810501 L_TP_L_WPC_FD_BDC_FD_Byte5 0;
BA_ "NetworkRequestHoldingTime" SG_ 2348810501 L_TP_L_WPC_FD_BDC_FD_Byte5 5000;
BA_ "Version" SG_ 2348810501 L_TP_L_WPC_FD_BDC_FD_Byte5 "23.01.02";
BA_ "Description" SG_ 2348810501 L_TP_L_WPC_FD_BDC_FD_Byte6 "TP Index : 272";
BA_ "UsrSigPurpose" SG_ 2348810501 L_TP_L_WPC_FD_BDC_FD_Byte6 9;
BA_ "UserSigValidity" SG_ 2348810501 L_TP_L_WPC_FD_BDC_FD_Byte6 0;
BA_REL_ "GenSigTimeoutTime" BU_SG_REL_ GW_BDC_FD SG_ 2348810501 L_TP_L_WPC_FD_BDC_FD_Byte6 0;
BA_ "NetworkRequest" SG_ 2348810501 L_TP_L_WPC_FD_BDC_FD_Byte6 0;
BA_ "NetworkRequestHoldingTime" SG_ 2348810501 L_TP_L_WPC_FD_BDC_FD_Byte6 5000;
BA_ "Version" SG_ 2348810501 L_TP_L_WPC_FD_BDC_FD_Byte6 "23.01.02";
BA_ "Description" SG_ 2348810501 L_TP_L_WPC_FD_BDC_FD_Byte7 "TP Index : 272";
BA_ "UsrSigPurpose" SG_ 2348810501 L_TP_L_WPC_FD_BDC_FD_Byte7 9;
BA_ "UserSigValidity" SG_ 2348810501 L_TP_L_WPC_FD_BDC_FD_Byte7 0;
BA_REL_ "GenSigTimeoutTime" BU_SG_REL_ GW_BDC_FD SG_ 2348810501 L_TP_L_WPC_FD_BDC_FD_Byte7 0;
BA_ "NetworkRequest" SG_ 2348810501 L_TP_L_WPC_FD_BDC_FD_Byte7 0;
BA_ "NetworkRequestHoldingTime" SG_ 2348810501 L_TP_L_WPC_FD_BDC_FD_Byte7 5000;
BA_ "Version" SG_ 2348810501 L_TP_L_WPC_FD_BDC_FD_Byte7 "23.01.02";
BA_ "Description" SG_ 2348810501 L_TP_L_WPC_FD_BDC_FD_Byte8 "TP Index : 272";
BA_ "UsrSigPurpose" SG_ 2348810501 L_TP_L_WPC_FD_BDC_FD_Byte8 9;
BA_ "UserSigValidity" SG_ 2348810501 L_TP_L_WPC_FD_BDC_FD_Byte8 0;
BA_REL_ "GenSigTimeoutTime" BU_SG_REL_ GW_BDC_FD SG_ 2348810501 L_TP_L_WPC_FD_BDC_FD_Byte8 0;
BA_ "NetworkRequest" SG_ 2348810501 L_TP_L_WPC_FD_BDC_FD_Byte8 0;
BA_ "NetworkRequestHoldingTime" SG_ 2348810501 L_TP_L_WPC_FD_BDC_FD_Byte8 5000;
BA_ "Version" SG_ 2348810501 L_TP_L_WPC_FD_BDC_FD_Byte8 "23.01.02";
BA_ "Description" SG_ 2348810501 L_TP_L_WPC_FD_BDC_FD_Byte9 "TP Index : 272";
BA_ "UsrSigPurpose" SG_ 2348810501 L_TP_L_WPC_FD_BDC_FD_Byte9 9;
BA_ "UserSigValidity" SG_ 2348810501 L_TP_L_WPC_FD_BDC_FD_Byte9 0;
BA_REL_ "GenSigTimeoutTime" BU_SG_REL_ GW_BDC_FD SG_ 2348810501 L_TP_L_WPC_FD_BDC_FD_Byte9 0;
BA_ "NetworkRequest" SG_ 2348810501 L_TP_L_WPC_FD_BDC_FD_Byte9 0;
BA_ "NetworkRequestHoldingTime" SG_ 2348810501 L_TP_L_WPC_FD_BDC_FD_Byte9 5000;
BA_ "Version" SG_ 2348810501 L_TP_L_WPC_FD_BDC_FD_Byte9 "23.01.02";
BA_ "Description" SG_ 2348810501 L_TP_L_WPC_FD_BDC_FD_Byte1 "TP Index : 272";
BA_ "UsrSigPurpose" SG_ 2348810501 L_TP_L_WPC_FD_BDC_FD_Byte1 9;
BA_ "UserSigValidity" SG_ 2348810501 L_TP_L_WPC_FD_BDC_FD_Byte1 0;
BA_REL_ "GenSigTimeoutTime" BU_SG_REL_ GW_BDC_FD SG_ 2348810501 L_TP_L_WPC_FD_BDC_FD_Byte1 0;
BA_ "NetworkRequest" SG_ 2348810501 L_TP_L_WPC_FD_BDC_FD_Byte1 0;
BA_ "NetworkRequestHoldingTime" SG_ 2348810501 L_TP_L_WPC_FD_BDC_FD_Byte1 5000;
BA_ "Version" SG_ 2348810501 L_TP_L_WPC_FD_BDC_FD_Byte1 "23.01.02";
BA_ "Description" SG_ 2348810501 L_TP_L_WPC_FD_BDC_FD_Byte10 "TP Index : 272";
BA_ "UsrSigPurpose" SG_ 2348810501 L_TP_L_WPC_FD_BDC_FD_Byte10 9;
BA_ "UserSigValidity" SG_ 2348810501 L_TP_L_WPC_FD_BDC_FD_Byte10 0;
BA_REL_ "GenSigTimeoutTime" BU_SG_REL_ GW_BDC_FD SG_ 2348810501 L_TP_L_WPC_FD_BDC_FD_Byte10 0;
BA_ "NetworkRequest" SG_ 2348810501 L_TP_L_WPC_FD_BDC_FD_Byte10 0;
BA_ "NetworkRequestHoldingTime" SG_ 2348810501 L_TP_L_WPC_FD_BDC_FD_Byte10 5000;
BA_ "Version" SG_ 2348810501 L_TP_L_WPC_FD_BDC_FD_Byte10 "23.01.02";
BA_ "Description" SG_ 2348810501 L_TP_L_WPC_FD_BDC_FD_Byte11 "TP Index : 272";
BA_ "UsrSigPurpose" SG_ 2348810501 L_TP_L_WPC_FD_BDC_FD_Byte11 9;
BA_ "UserSigValidity" SG_ 2348810501 L_TP_L_WPC_FD_BDC_FD_Byte11 0;
BA_REL_ "GenSigTimeoutTime" BU_SG_REL_ GW_BDC_FD SG_ 2348810501 L_TP_L_WPC_FD_BDC_FD_Byte11 0;
BA_ "NetworkRequest" SG_ 2348810501 L_TP_L_WPC_FD_BDC_FD_Byte11 0;
BA_ "NetworkRequestHoldingTime" SG_ 2348810501 L_TP_L_WPC_FD_BDC_FD_Byte11 5000;
BA_ "Version" SG_ 2348810501 L_TP_L_WPC_FD_BDC_FD_Byte11 "23.01.02";
BA_ "Description" SG_ 2348810501 L_TP_L_WPC_FD_BDC_FD_Byte12 "TP Index : 272";
BA_ "UsrSigPurpose" SG_ 2348810501 L_TP_L_WPC_FD_BDC_FD_Byte12 9;
BA_ "UserSigValidity" SG_ 2348810501 L_TP_L_WPC_FD_BDC_FD_Byte12 0;
BA_REL_ "GenSigTimeoutTime" BU_SG_REL_ GW_BDC_FD SG_ 2348810501 L_TP_L_WPC_FD_BDC_FD_Byte12 0;
BA_ "NetworkRequest" SG_ 2348810501 L_TP_L_WPC_FD_BDC_FD_Byte12 0;
BA_ "NetworkRequestHoldingTime" SG_ 2348810501 L_TP_L_WPC_FD_BDC_FD_Byte12 5000;
BA_ "Version" SG_ 2348810501 L_TP_L_WPC_FD_BDC_FD_Byte12 "23.01.02";
BA_ "GenMsgCycleTime" BO_ 2214592624 0;
BA_ "VFrameFormat" BO_ 2214592624 15;
BA_ "Description" SG_ 2214592624 L_WPC_FD_Crc1Val "The data area for CRC calculation is based on the data length (DLC) of the message DB.

The CRC shall be calculated over the entire data block (excluding the CRC bytes) including the user data, alive counter and Data ID



- CRC Polynomial (0x1021) , Initial Value : 0xFFFF, XOR value : 0x0000, Data ID : Message ID + 0xF800 

- The initial value is for CRC calculation and the message should be sent with the calculated result value. 

- The mathematical expression to 16 bit CRC polynomial is given here. G(x) = x16 + x12 + x5 + 1



<For CRC calculation of CAN-FD Msg for HS CAN domain ECUs>



- HS-CAN Messages that routed from CAN-FD domain are using 29 bit Extended CAN ID and splitted into 8 Byte Messages.

(from 1 to 4 Msgs, depending on source CAN-FD Msg¡¯s DLC)

- For splitted CAN-FD Msgs¡¯ CRC calculation, HS CAN ECUs should use source CAN-FD Msg¡¯s original STD ID. 

- The original STD ID can be read from Ext ID¡¯s 4~6th Byte.

Eg. STD 0x6AA : EXT SPLT 0x1A8[6AA]01 / 0x1A8[6AA]02 / 0x1A8[6AA]03 / 0x1A8[6AA]04 

(2~4th splitited Msgs can be omitted depending on source CAN-FD Msg¡¯s DLC)

- Aslo, HS-CAN ECUs should use merged data block (from whole splitted Msg) for CRC calculation.";
BA_ "GenSigSendType" SG_ 2214592624 L_WPC_FD_Crc1Val 4;
BA_ "GenSigStartValue" SG_ 2214592624 L_WPC_FD_Crc1Val 65535;
BA_ "UserSigValidity" SG_ 2214592624 L_WPC_FD_Crc1Val 3;
BA_ "Version" SG_ 2214592624 L_WPC_FD_Crc1Val "23.01.02";
BA_ "Description" SG_ 2214592624 L_WPC_FD_AlvCnt1Val "For the first transmission request for a data element the counter shall be initialized with 0 and shall be incremented by 1 for every subsequent send request. 

When the counter reaches the maximum value(0xFF), then it shall restart with 0 for the next send request";
BA_ "GenSigSendType" SG_ 2214592624 L_WPC_FD_AlvCnt1Val 4;
BA_ "UserSigValidity" SG_ 2214592624 L_WPC_FD_AlvCnt1Val 3;
BA_ "Version" SG_ 2214592624 L_WPC_FD_AlvCnt1Val "23.01.02";
BA_ "GenSigSendType" SG_ 2214592624 WPC_NFCDetection_Sta 4;
BA_ "UserSigValidity" SG_ 2214592624 WPC_NFCDetection_Sta 0;
BA_REL_ "GenSigTimeoutTime" BU_SG_REL_ GW_BDC_FD SG_ 2214592624 WPC_NFCDetection_Sta 0;
BA_ "Version" SG_ 2214592624 WPC_NFCDetection_Sta "23.01.02";
BA_ "GenSigSendType" SG_ 2214592624 WPC_NFCReset_Sta 4;
BA_ "UserSigValidity" SG_ 2214592624 WPC_NFCReset_Sta 0;
BA_REL_ "GenSigTimeoutTime" BU_SG_REL_ GW_BDC_FD SG_ 2214592624 WPC_NFCReset_Sta 0;
BA_ "Version" SG_ 2214592624 WPC_NFCReset_Sta "23.01.02";
BA_ "GenSigSendType" SG_ 2214592624 WPC2_NFCDetection_Sta 4;
BA_ "UserSigValidity" SG_ 2214592624 WPC2_NFCDetection_Sta 0;
BA_REL_ "GenSigTimeoutTime" BU_SG_REL_ GW_BDC_FD SG_ 2214592624 WPC2_NFCDetection_Sta 0;
BA_ "Version" SG_ 2214592624 WPC2_NFCDetection_Sta "24.07.02";
BA_ "GenSigSendType" SG_ 2214592624 WPC2_NFCReset_Sta 4;
BA_ "UserSigValidity" SG_ 2214592624 WPC2_NFCReset_Sta 0;
BA_REL_ "GenSigTimeoutTime" BU_SG_REL_ GW_BDC_FD SG_ 2214592624 WPC2_NFCReset_Sta 0;
BA_ "Version" SG_ 2214592624 WPC2_NFCReset_Sta "24.07.02";
BA_ "GenMsgSendType" BO_ 745 0;
BA_ "GenMsgCycleTime" BO_ 745 300;
BA_ "VFrameFormat" BO_ 745 14;
BA_ "Description" SG_ 745 PDC_FD_Crc15Val "The data area for CRC calculation is based on the data length (DLC) of the message DB.

The CRC shall be calculated over the entire data block (excluding the CRC bytes) including the user data, alive counter and Data ID



- CRC Polynomial (0x1021) , Initial Value : 0xFFFF, XOR value : 0x0000, Data ID : Message ID + 0xF800 

- The initial value is for CRC calculation and the message should be sent with the calculated result value. 

- The mathematical expression to 16 bit CRC polynomial is given here. G(x) = x16 + x12 + x5 + 1



<For CRC calculation of CAN-FD Msg for HS CAN domain ECUs>



- HS-CAN Messages that routed from CAN-FD domain are using 29 bit Extended CAN ID and splitted into 8 Byte Messages.

(from 1 to 4 Msgs, depending on source CAN-FD Msg¡¯s DLC)

- For splitted CAN-FD Msgs¡¯ CRC calculation, HS CAN ECUs should use source CAN-FD Msg¡¯s original STD ID. 

- The original STD ID can be read from Ext ID¡¯s 4~6th Byte.

Eg. STD 0x6AA : EXT SPLT 0x1A8[6AA]01 / 0x1A8[6AA]02 / 0x1A8[6AA]03 / 0x1A8[6AA]04 

(2~4th splitited Msgs can be omitted depending on source CAN-FD Msg¡¯s DLC)

- Aslo, HS-CAN ECUs should use merged data block (from whole splitted Msg) for CRC calculation.";
BA_ "GenSigSendType" SG_ 745 PDC_FD_Crc15Val 4;
BA_ "GenSigStartValue" SG_ 745 PDC_FD_Crc15Val 65535;
BA_ "UserSigValidity" SG_ 745 PDC_FD_Crc15Val 3;
BA_REL_ "GenSigTimeoutTime" BU_SG_REL_ L_DHL_FD SG_ 745 PDC_FD_Crc15Val 1500;
BA_REL_ "GenSigTimeoutTime" BU_SG_REL_ L_DHRL_FD SG_ 745 PDC_FD_Crc15Val 1500;
BA_REL_ "GenSigTimeoutTime" BU_SG_REL_ L_DHRR_FD SG_ 745 PDC_FD_Crc15Val 1500;
BA_REL_ "GenSigTimeoutTime" BU_SG_REL_ L_DHR_FD SG_ 745 PDC_FD_Crc15Val 1500;
BA_REL_ "GenSigTimeoutTime" BU_SG_REL_ L_EDT_FD SG_ 745 PDC_FD_Crc15Val 1500;
BA_REL_ "GenSigTimeoutTime" BU_SG_REL_ L_ROA_FD SG_ 745 PDC_FD_Crc15Val 1500;
BA_REL_ "GenSigTimeoutTime" BU_SG_REL_ L_ROA_FR_FD SG_ 745 PDC_FD_Crc15Val 1500;
BA_REL_ "GenSigTimeoutTime" BU_SG_REL_ L_SAL_FD SG_ 745 PDC_FD_Crc15Val 1500;
BA_REL_ "GenSigTimeoutTime" BU_SG_REL_ L_TPMS_FD SG_ 745 PDC_FD_Crc15Val 1500;
BA_REL_ "GenSigTimeoutTime" BU_SG_REL_ L_UWB_BLE_MST_FD SG_ 745 PDC_FD_Crc15Val 1500;
BA_REL_ "GenSigTimeoutTime" BU_SG_REL_ L_UWB_BLE_SLV_FD SG_ 745 PDC_FD_Crc15Val 1500;
BA_REL_ "GenSigTimeoutTime" BU_SG_REL_ L_UWB_FL_FD SG_ 745 PDC_FD_Crc15Val 1500;
BA_REL_ "GenSigTimeoutTime" BU_SG_REL_ L_UWB_FRNK_FD SG_ 745 PDC_FD_Crc15Val 1500;
BA_REL_ "GenSigTimeoutTime" BU_SG_REL_ L_UWB_FR_FD SG_ 745 PDC_FD_Crc15Val 1500;
BA_REL_ "GenSigTimeoutTime" BU_SG_REL_ L_UWB_RL_FD SG_ 745 PDC_FD_Crc15Val 1500;
BA_REL_ "GenSigTimeoutTime" BU_SG_REL_ L_UWB_RR_FD SG_ 745 PDC_FD_Crc15Val 1500;
BA_REL_ "GenSigTimeoutTime" BU_SG_REL_ L_UWB_TRNK_FD SG_ 745 PDC_FD_Crc15Val 1500;
BA_REL_ "GenSigTimeoutTime" BU_SG_REL_ L_WPC_FD SG_ 745 PDC_FD_Crc15Val 1500;
BA_ "Version" SG_ 745 PDC_FD_Crc15Val "24.04.08";
BA_ "Description" SG_ 745 PDC_CurrAtReset "This signal indicate the current at reset request";
BA_ "GenSigSendType" SG_ 745 PDC_CurrAtReset 4;
BA_ "UserSigValidity" SG_ 745 PDC_CurrAtReset 0;
BA_ "Version" SG_ 745 PDC_CurrAtReset "24.07.06";
BA_ "Description" SG_ 745 PDC_AvgCurrAtReset "This signal indicate the average current at reset request";
BA_ "GenSigSendType" SG_ 745 PDC_AvgCurrAtReset 4;
BA_ "UserSigValidity" SG_ 745 PDC_AvgCurrAtReset 0;
BA_ "Version" SG_ 745 PDC_AvgCurrAtReset "24.07.06";
BA_ "Description" SG_ 745 PDC_ResetReason "This signal indicate the reason reset is operated";
BA_ "GenSigSendType" SG_ 745 PDC_ResetReason 4;
BA_ "UserSigValidity" SG_ 745 PDC_ResetReason 0;
BA_ "Version" SG_ 745 PDC_ResetReason "24.07.06";
BA_ "Description" SG_ 745 PDC_CumulativeCountOf12VReq "This signal indicates the cumulative number of 12V Controller req.";
BA_ "GenSigSendType" SG_ 745 PDC_CumulativeCountOf12VReq 4;
BA_ "UserSigValidity" SG_ 745 PDC_CumulativeCountOf12VReq 0;
BA_ "Version" SG_ 745 PDC_CumulativeCountOf12VReq "24.07.06";
BA_ "Description" SG_ 745 PDC_CumulativeCountOfCCUReq "This signal indicates the cumulative number of CCU_ForcedPowerOffReq";
BA_ "GenSigSendType" SG_ 745 PDC_CumulativeCountOfCCUReq 4;
BA_ "UserSigValidity" SG_ 745 PDC_CumulativeCountOfCCUReq 0;
BA_ "Version" SG_ 745 PDC_CumulativeCountOfCCUReq "24.07.06";
BA_ "Description" SG_ 745 PDC_FD_AlvCnt15Val "For the first transmission request for a data element the counter shall be initialized with 0 and shall be incremented by 1 for every subsequent send request. 

When the counter reaches the maximum value(0xFF), then it shall restart with 0 for the next send request";
BA_ "GenSigSendType" SG_ 745 PDC_FD_AlvCnt15Val 4;
BA_ "UserSigValidity" SG_ 745 PDC_FD_AlvCnt15Val 3;
BA_REL_ "GenSigTimeoutTime" BU_SG_REL_ L_DHL_FD SG_ 745 PDC_FD_AlvCnt15Val 1500;
BA_REL_ "GenSigTimeoutTime" BU_SG_REL_ L_DHRL_FD SG_ 745 PDC_FD_AlvCnt15Val 1500;
BA_REL_ "GenSigTimeoutTime" BU_SG_REL_ L_DHRR_FD SG_ 745 PDC_FD_AlvCnt15Val 1500;
BA_REL_ "GenSigTimeoutTime" BU_SG_REL_ L_DHR_FD SG_ 745 PDC_FD_AlvCnt15Val 1500;
BA_REL_ "GenSigTimeoutTime" BU_SG_REL_ L_EDT_FD SG_ 745 PDC_FD_AlvCnt15Val 1500;
BA_REL_ "GenSigTimeoutTime" BU_SG_REL_ L_ROA_FD SG_ 745 PDC_FD_AlvCnt15Val 1500;
BA_REL_ "GenSigTimeoutTime" BU_SG_REL_ L_ROA_FR_FD SG_ 745 PDC_FD_AlvCnt15Val 1500;
BA_REL_ "GenSigTimeoutTime" BU_SG_REL_ L_SAL_FD SG_ 745 PDC_FD_AlvCnt15Val 1500;
BA_REL_ "GenSigTimeoutTime" BU_SG_REL_ L_TPMS_FD SG_ 745 PDC_FD_AlvCnt15Val 1500;
BA_REL_ "GenSigTimeoutTime" BU_SG_REL_ L_UWB_BLE_MST_FD SG_ 745 PDC_FD_AlvCnt15Val 1500;
BA_REL_ "GenSigTimeoutTime" BU_SG_REL_ L_UWB_BLE_SLV_FD SG_ 745 PDC_FD_AlvCnt15Val 1500;
BA_REL_ "GenSigTimeoutTime" BU_SG_REL_ L_UWB_FL_FD SG_ 745 PDC_FD_AlvCnt15Val 1500;
BA_REL_ "GenSigTimeoutTime" BU_SG_REL_ L_UWB_FRNK_FD SG_ 745 PDC_FD_AlvCnt15Val 1500;
BA_REL_ "GenSigTimeoutTime" BU_SG_REL_ L_UWB_FR_FD SG_ 745 PDC_FD_AlvCnt15Val 1500;
BA_REL_ "GenSigTimeoutTime" BU_SG_REL_ L_UWB_RL_FD SG_ 745 PDC_FD_AlvCnt15Val 1500;
BA_REL_ "GenSigTimeoutTime" BU_SG_REL_ L_UWB_RR_FD SG_ 745 PDC_FD_AlvCnt15Val 1500;
BA_REL_ "GenSigTimeoutTime" BU_SG_REL_ L_UWB_TRNK_FD SG_ 745 PDC_FD_AlvCnt15Val 1500;
BA_REL_ "GenSigTimeoutTime" BU_SG_REL_ L_WPC_FD SG_ 745 PDC_FD_AlvCnt15Val 1500;
BA_ "Version" SG_ 745 PDC_FD_AlvCnt15Val "24.04.08";
BA_ "Description" SG_ 745 PDC_LDConReq "LDC on request signal for High Voltage Battery Discharge";
BA_ "GenSigSendType" SG_ 745 PDC_LDConReq 4;
BA_ "UserSigValidity" SG_ 745 PDC_LDConReq 0;
BA_ "Version" SG_ 745 PDC_LDConReq "24.07.05";
BA_ "Description" SG_ 745 PDC_LDConReq_By_LVBat "LDC on request signal for High Voltage Battery Discharge by Low Voltage Battery";
BA_ "GenSigSendType" SG_ 745 PDC_LDConReq_By_LVBat 4;
BA_ "UserSigValidity" SG_ 745 PDC_LDConReq_By_LVBat 0;
BA_ "Version" SG_ 745 PDC_LDConReq_By_LVBat "24.07.05";
BA_ "Description" SG_ 745 PDC_LDConReq_By_OTA "LDC on request signal for High Voltage Battery Discharge by OTA";
BA_ "GenSigSendType" SG_ 745 PDC_LDConReq_By_OTA 4;
BA_ "UserSigValidity" SG_ 745 PDC_LDConReq_By_OTA 0;
BA_ "Version" SG_ 745 PDC_LDConReq_By_OTA "24.07.05";
BA_ "Description" SG_ 745 PDC_LDConReq_By_Load "LDC on request signal for High Voltage Battery Discharge by Load";
BA_ "GenSigSendType" SG_ 745 PDC_LDConReq_By_Load 4;
BA_ "UserSigValidity" SG_ 745 PDC_LDConReq_By_Load 0;
BA_ "Version" SG_ 745 PDC_LDConReq_By_Load "24.07.05";
BA_ "Description" SG_ 745 PDC_LDConReq_By_ActiveOn "LDC on request signal for High Voltage Battery Discharge by Active On";
BA_ "GenSigSendType" SG_ 745 PDC_LDConReq_By_ActiveOn 4;
BA_ "UserSigValidity" SG_ 745 PDC_LDConReq_By_ActiveOn 0;
BA_ "Version" SG_ 745 PDC_LDConReq_By_ActiveOn "24.07.05";
BA_ "Description" SG_ 745 PDC_ResetPreWrngForCCU "This is a warning signal for reset.  This signal is used for preparing sideeffect of reset by Gateway";
BA_ "GenSigSendType" SG_ 745 PDC_ResetPreWrngForCCU 4;
BA_ "UserSigValidity" SG_ 745 PDC_ResetPreWrngForCCU 0;
BA_ "Version" SG_ 745 PDC_ResetPreWrngForCCU "24.05.05";
BA_ "Description" SG_ 745 PDC_ResetPreWrngForOthers "This is a warning signal for reset.  This signal is used for preparing sideeffect of reset by Receivers";
BA_ "GenSigSendType" SG_ 745 PDC_ResetPreWrngForOthers 4;
BA_ "UserSigValidity" SG_ 745 PDC_ResetPreWrngForOthers 0;
BA_REL_ "GenSigTimeoutTime" BU_SG_REL_ L_DHL_FD SG_ 745 PDC_ResetPreWrngForOthers 1500;
BA_REL_ "GenSigTimeoutTime" BU_SG_REL_ L_DHRL_FD SG_ 745 PDC_ResetPreWrngForOthers 1500;
BA_REL_ "GenSigTimeoutTime" BU_SG_REL_ L_DHRR_FD SG_ 745 PDC_ResetPreWrngForOthers 1500;
BA_REL_ "GenSigTimeoutTime" BU_SG_REL_ L_DHR_FD SG_ 745 PDC_ResetPreWrngForOthers 1500;
BA_REL_ "GenSigTimeoutTime" BU_SG_REL_ L_EDT_FD SG_ 745 PDC_ResetPreWrngForOthers 1500;
BA_REL_ "GenSigTimeoutTime" BU_SG_REL_ L_ROA_FD SG_ 745 PDC_ResetPreWrngForOthers 1500;
BA_REL_ "GenSigTimeoutTime" BU_SG_REL_ L_ROA_FR_FD SG_ 745 PDC_ResetPreWrngForOthers 1500;
BA_REL_ "GenSigTimeoutTime" BU_SG_REL_ L_SAL_FD SG_ 745 PDC_ResetPreWrngForOthers 1500;
BA_REL_ "GenSigTimeoutTime" BU_SG_REL_ L_TPMS_FD SG_ 745 PDC_ResetPreWrngForOthers 1500;
BA_REL_ "GenSigTimeoutTime" BU_SG_REL_ L_UWB_BLE_MST_FD SG_ 745 PDC_ResetPreWrngForOthers 1500;
BA_REL_ "GenSigTimeoutTime" BU_SG_REL_ L_UWB_BLE_SLV_FD SG_ 745 PDC_ResetPreWrngForOthers 1500;
BA_REL_ "GenSigTimeoutTime" BU_SG_REL_ L_UWB_FL_FD SG_ 745 PDC_ResetPreWrngForOthers 1500;
BA_REL_ "GenSigTimeoutTime" BU_SG_REL_ L_UWB_FRNK_FD SG_ 745 PDC_ResetPreWrngForOthers 1500;
BA_REL_ "GenSigTimeoutTime" BU_SG_REL_ L_UWB_FR_FD SG_ 745 PDC_ResetPreWrngForOthers 1500;
BA_REL_ "GenSigTimeoutTime" BU_SG_REL_ L_UWB_RL_FD SG_ 745 PDC_ResetPreWrngForOthers 1500;
BA_REL_ "GenSigTimeoutTime" BU_SG_REL_ L_UWB_RR_FD SG_ 745 PDC_ResetPreWrngForOthers 1500;
BA_REL_ "GenSigTimeoutTime" BU_SG_REL_ L_UWB_TRNK_FD SG_ 745 PDC_ResetPreWrngForOthers 1500;
BA_REL_ "GenSigTimeoutTime" BU_SG_REL_ L_WPC_FD SG_ 745 PDC_ResetPreWrngForOthers 1500;
BA_ "Version" SG_ 745 PDC_ResetPreWrngForOthers "24.05.05";
BA_ "Description" SG_ 745 PDC_ResetReqForCCU "This is a request signal for SW reset of Gateway";
BA_ "GenSigSendType" SG_ 745 PDC_ResetReqForCCU 4;
BA_ "UserSigValidity" SG_ 745 PDC_ResetReqForCCU 0;
BA_ "Version" SG_ 745 PDC_ResetReqForCCU "24.05.05";
BA_ "Description" SG_ 745 PDC_ResetReqForOthers "This is a request signal for SW reset except for Gateway";
BA_ "GenSigSendType" SG_ 745 PDC_ResetReqForOthers 4;
BA_ "UserSigValidity" SG_ 745 PDC_ResetReqForOthers 0;
BA_REL_ "GenSigTimeoutTime" BU_SG_REL_ L_DHL_FD SG_ 745 PDC_ResetReqForOthers 1500;
BA_REL_ "GenSigTimeoutTime" BU_SG_REL_ L_DHRL_FD SG_ 745 PDC_ResetReqForOthers 1500;
BA_REL_ "GenSigTimeoutTime" BU_SG_REL_ L_DHRR_FD SG_ 745 PDC_ResetReqForOthers 1500;
BA_REL_ "GenSigTimeoutTime" BU_SG_REL_ L_DHR_FD SG_ 745 PDC_ResetReqForOthers 1500;
BA_REL_ "GenSigTimeoutTime" BU_SG_REL_ L_EDT_FD SG_ 745 PDC_ResetReqForOthers 1500;
BA_REL_ "GenSigTimeoutTime" BU_SG_REL_ L_ROA_FD SG_ 745 PDC_ResetReqForOthers 1500;
BA_REL_ "GenSigTimeoutTime" BU_SG_REL_ L_ROA_FR_FD SG_ 745 PDC_ResetReqForOthers 1500;
BA_REL_ "GenSigTimeoutTime" BU_SG_REL_ L_SAL_FD SG_ 745 PDC_ResetReqForOthers 1500;
BA_REL_ "GenSigTimeoutTime" BU_SG_REL_ L_TPMS_FD SG_ 745 PDC_ResetReqForOthers 1500;
BA_REL_ "GenSigTimeoutTime" BU_SG_REL_ L_UWB_BLE_MST_FD SG_ 745 PDC_ResetReqForOthers 1500;
BA_REL_ "GenSigTimeoutTime" BU_SG_REL_ L_UWB_BLE_SLV_FD SG_ 745 PDC_ResetReqForOthers 1500;
BA_REL_ "GenSigTimeoutTime" BU_SG_REL_ L_UWB_FL_FD SG_ 745 PDC_ResetReqForOthers 1500;
BA_REL_ "GenSigTimeoutTime" BU_SG_REL_ L_UWB_FRNK_FD SG_ 745 PDC_ResetReqForOthers 1500;
BA_REL_ "GenSigTimeoutTime" BU_SG_REL_ L_UWB_FR_FD SG_ 745 PDC_ResetReqForOthers 1500;
BA_REL_ "GenSigTimeoutTime" BU_SG_REL_ L_UWB_RL_FD SG_ 745 PDC_ResetReqForOthers 1500;
BA_REL_ "GenSigTimeoutTime" BU_SG_REL_ L_UWB_RR_FD SG_ 745 PDC_ResetReqForOthers 1500;
BA_REL_ "GenSigTimeoutTime" BU_SG_REL_ L_UWB_TRNK_FD SG_ 745 PDC_ResetReqForOthers 1500;
BA_REL_ "GenSigTimeoutTime" BU_SG_REL_ L_WPC_FD SG_ 745 PDC_ResetReqForOthers 1500;
BA_ "Version" SG_ 745 PDC_ResetReqForOthers "24.05.05";
BA_ "Description" SG_ 745 PDC_ResetFuncOpt "This signal inform whether reset fucntion at PDC is appiled or not";
BA_ "GenSigSendType" SG_ 745 PDC_ResetFuncOpt 4;
BA_ "UserSigValidity" SG_ 745 PDC_ResetFuncOpt 0;
BA_REL_ "GenSigTimeoutTime" BU_SG_REL_ L_ROA_FD SG_ 745 PDC_ResetFuncOpt 1500;
BA_REL_ "GenSigTimeoutTime" BU_SG_REL_ L_ROA_FR_FD SG_ 745 PDC_ResetFuncOpt 1500;
BA_REL_ "GenSigTimeoutTime" BU_SG_REL_ L_TPMS_FD SG_ 745 PDC_ResetFuncOpt 1500;
BA_REL_ "GenSigTimeoutTime" BU_SG_REL_ L_UWB_BLE_MST_FD SG_ 745 PDC_ResetFuncOpt 1500;
BA_REL_ "GenSigTimeoutTime" BU_SG_REL_ L_UWB_BLE_SLV_FD SG_ 745 PDC_ResetFuncOpt 1500;
BA_REL_ "GenSigTimeoutTime" BU_SG_REL_ L_UWB_FL_FD SG_ 745 PDC_ResetFuncOpt 1500;
BA_REL_ "GenSigTimeoutTime" BU_SG_REL_ L_UWB_FRNK_FD SG_ 745 PDC_ResetFuncOpt 1500;
BA_REL_ "GenSigTimeoutTime" BU_SG_REL_ L_UWB_FR_FD SG_ 745 PDC_ResetFuncOpt 1500;
BA_REL_ "GenSigTimeoutTime" BU_SG_REL_ L_UWB_RL_FD SG_ 745 PDC_ResetFuncOpt 1500;
BA_REL_ "GenSigTimeoutTime" BU_SG_REL_ L_UWB_RR_FD SG_ 745 PDC_ResetFuncOpt 1500;
BA_REL_ "GenSigTimeoutTime" BU_SG_REL_ L_UWB_TRNK_FD SG_ 745 PDC_ResetFuncOpt 1500;
BA_ "Version" SG_ 745 PDC_ResetFuncOpt "24.05.05";
BA_ "Description" SG_ 745 PDC_12VRlyCtrl "This signal is request signal to control 12V battery internal relay for HW reset";
BA_ "GenSigSendType" SG_ 745 PDC_12VRlyCtrl 4;
BA_ "UserSigValidity" SG_ 745 PDC_12VRlyCtrl 0;
BA_ "Version" SG_ 745 PDC_12VRlyCtrl "24.05.05";
BA_ "Description" SG_ 745 PDC_CurrentValueForReset "This signal sets the average discharge current value to be measured for PDC_TimevalueForReset to be considered as a situation requiring reset.";
BA_ "GenSigSendType" SG_ 745 PDC_CurrentValueForReset 4;
BA_ "UserSigValidity" SG_ 745 PDC_CurrentValueForReset 0;
BA_ "Version" SG_ 745 PDC_CurrentValueForReset "24.07.03";
BA_ "Description" SG_ 745 PDC_TimeValueForReset "This signal sets the time value to be considered as a situation requiring reset.";
BA_ "GenSigSendType" SG_ 745 PDC_TimeValueForReset 4;
BA_ "UserSigValidity" SG_ 745 PDC_TimeValueForReset 0;
BA_ "Version" SG_ 745 PDC_TimeValueForReset "24.07.03";
BA_ "Description" SG_ 745 PDC_12VRlyOffHoldingTime "This signal sets how long the relay will be turned off when performing an HW reset using a 12 V battery internal relay.";
BA_ "GenSigSendType" SG_ 745 PDC_12VRlyOffHoldingTime 4;
BA_ "UserSigValidity" SG_ 745 PDC_12VRlyOffHoldingTime 0;
BA_ "Version" SG_ 745 PDC_12VRlyOffHoldingTime "24.05.05";
BA_ "Description" SG_ 745 PDC_ResetCountSetting "This signal sets the number of resets performed.";
BA_ "GenSigSendType" SG_ 745 PDC_ResetCountSetting 4;
BA_ "UserSigValidity" SG_ 745 PDC_ResetCountSetting 0;
BA_ "Version" SG_ 745 PDC_ResetCountSetting "24.05.05";
BA_ "Description" SG_ 745 PDC_ResetCount "This signal indicates how much reset has occurred.";
BA_ "GenSigSendType" SG_ 745 PDC_ResetCount 4;
BA_ "UserSigValidity" SG_ 745 PDC_ResetCount 0;
BA_ "Version" SG_ 745 PDC_ResetCount "24.05.05";
BA_ "Description" SG_ 745 PDC_ResetCumulativeCount "This signal indicates the cumulative number of resets performed.";
BA_ "GenSigSendType" SG_ 745 PDC_ResetCumulativeCount 4;
BA_ "UserSigValidity" SG_ 745 PDC_ResetCumulativeCount 0;
BA_ "Version" SG_ 745 PDC_ResetCumulativeCount "24.05.05";
BA_ "Description" SG_ 745 PDC_ResetOpsta "This signal indicates whether the reset operation has been completed or not";
BA_ "GenSigSendType" SG_ 745 PDC_ResetOpsta 4;
BA_ "UserSigValidity" SG_ 745 PDC_ResetOpsta 0;
BA_ "Version" SG_ 745 PDC_ResetOpsta "24.05.05";
BA_ "Description" SG_ 745 PDC_ReadyTimeValueForReset "This signal sets the time value to be considered as a situation of quiescent current

if receiver receive the value of no setting, do not operate the logic related to this signal";
BA_ "GenSigSendType" SG_ 745 PDC_ReadyTimeValueForReset 4;
BA_ "UserSigValidity" SG_ 745 PDC_ReadyTimeValueForReset 0;
BA_ "Version" SG_ 745 PDC_ReadyTimeValueForReset "24.07.06";
BA_ "NmAsrNodeIdentifier" BU_ L_DHRR_FD 45;
BA_ "NmAsrNodeIdentifier" BU_ L_UWB_BLE_MST_FD 32;
BA_ "NmAsrNodeIdentifier" BU_ L_UWB_RR_FD 38;
BA_ "NmAsrNodeIdentifier" BU_ L_UWB_BLE_SLV_FD 33;
BA_ "NmAsrNodeIdentifier" BU_ L_UWB_FR_FD 35;
BA_ "NmAsrNodeIdentifier" BU_ L_DHRL_FD 44;
BA_ "NmAsrNodeIdentifier" BU_ L_UWB_TRNK_FD 39;
BA_ "NmAsrNodeIdentifier" BU_ L_UWB_FRNK_FD 36;
BA_ "NmAsrNodeIdentifier" BU_ L_UWB_FL_FD 34;
BA_ "NmAsrNodeIdentifier" BU_ GW_BDC_FD 128;
BA_ "NmAsrNodeIdentifier" BU_ L_UWB_RL_FD 37;
BA_ "NmAsrNodeIdentifier" BU_ L_SAL_FD 169;
BA_ "NmAsrNodeIdentifier" BU_ L_WPC_FD 30;
BA_ "NmAsrNodeIdentifier" BU_ L_TPMS_FD 40;
BA_ "NmAsrNodeIdentifier" BU_ L_DHL_FD 42;
BA_ "NmAsrNodeIdentifier" BU_ L_DHR_FD 43;
VAL_ 1087 CCU_01_Crc1Val 0 "0x0x0~0xFF:CRCValue" 255 "0x0x0~0xFF:CRCValue" ;
VAL_ 1087 CCU_01_AlvCnt1Val 0 "AlvCntValue" 1 "AlvCntValue" 2 "AlvCntValue" 3 "AlvCntValue" 4 "AlvCntValue" 5 "AlvCntValue" 6 "AlvCntValue" 7 "AlvCntValue" 8 "AlvCntValue" 9 "AlvCntValue" 10 "AlvCntValue" 11 "AlvCntValue" 12 "AlvCntValue" 13 "AlvCntValue" 14 "AlvCntValue" 15 "AlvCntValue" ;
VAL_ 1087 CCU_ForcedPowerOffReq 0 "OFF" 1 "ON in the non-sleep state" 2 "ON in the normal-sleep state" 3 "Reserved" ;
VAL_ 849 IAU_FD_Crc4Val 0 "0x0x0~0xFFFF:CRCValue" 65535 "0x0x0~0xFFFF:CRCValue" ;
VAL_ 849 IAU_DISPWrng 0 "None" 1 "Auth_Fail2 (DigitalKey)" 2 "ReAuth_Warning" 3 "IAU Error" 4 "DigitalKey Saved" 5 "Auth_Fail2 (FP)" 6 "Auth_Fail2 (DigitalKey or FP)" 7 "BiometricKey Saved" 8 "DigitalKey and BiometricKey Saved" 9 "WPCNFC_PreStartAuth_Success" 10 "Reserved" 11 "Reserved" 12 "Reserved" 13 "Reserved" 14 "ReAuth_forRSPA" 15 "Invalid" ;
VAL_ 849 IAU_DigitalKey2Opt 0 "Default (Not applied)" 1 "Digital Key Light (NFC)" 2 "Digital Key Medium (NFC/BLE)" 3 "Digital Key Full (NFC/BLE/UWB)" 4 "Reserved" 5 "Reserved" 6 "Reserved" 7 "invalid" ;
VAL_ 849 IAUwFRULearnState 0 "Default (Normal)" 1 "Learning" 2 "Neutralizing" 3 "Invalid" ;
VAL_ 849 IAUwFPMLearnState 0 "Default(Normal)" 1 "Learning" 2 "Neutralizing" 3 "Invalid" ;
VAL_ 849 IAU_ValetDigitalkey 0 "Default" 1 "Valet Digitalkey" 2 "Resereved" 3 "invalid" ;
VAL_ 849 IAU_DigitalKeyNumberOpt 0 "Max8" 1 "Max16" 2 "Max16 with Grouping" 3 "RESERVED" 4 "RESERVED" 5 "RESERVED" 6 "RESERVED" 7 "Invalid" ;
VAL_ 849 IAU_eSEReprogramSta 0 "Default" 1 "Updating" 2 "RESERVED" 3 "Invalid" ;
VAL_ 849 IAU_DKOwnerSwapOption 0 "Default" 1 "Not applied" 2 "Applied" 3 "Invalid" ;
VAL_ 849 IAU_DgtKeyGrpPrflRval2 0 "Default" 1 "Group index 0x0" 2 "Group index 0x1" 3 "Group index 0x2" 4 "Group index 0x3" 5 "Group index 0x4" 6 "Group index 0x5" 7 "Group index 0x6" 8 "Group index 0x7" 9 "Group index 0x8" 10 "Group index 0x9" 11 "Group index 0xA" 12 "Group index 0xB" 13 "Group index 0xC" 14 "Group index 0xD" 15 "Group index 0xE" 16 "Group index 0xF" 17 "RESERVED" 18 "RESERVED" 19 "RESERVED" 20 "RESERVED" 21 "RESERVED" 22 "RESERVED" 23 "RESERVED" 24 "RESERVED" 25 "RESERVED" 26 "RESERVED" 27 "RESERVED" 28 "RESERVED" 29 "RESERVED" 30 "RESERVED" 31 "Invalid" ;
VAL_ 849 IAU_StartIdentifiedProfile 0 "Default" 1 "Profile 1" 2 "Profile 2" 3 "Reserved" 4 "Reserved" 5 "Reserved" 6 "Reserved" 7 "Invalid" ;
VAL_ 849 IAU_DigitalKeyProfileRval2 0 "Default" 1 "1st digital key (owner)" 2 "2nd digital key" 3 "3rd digital key" 4 "4th digital key" 5 "5th digital key" 6 "6th digital key" 7 "7th digital key" 8 "8th digital key" 9 "9th digital key" 10 "10th digital key" 11 "11th digital key" 12 "12th digital key" 13 "13th digital key" 14 "14th digital key" 15 "15th digital key" 16 "16th digital key" 17 "reserved" 18 "reserved" 19 "reserved" 20 "reserved" 21 "reserved" 22 "reserved" 23 "reserved" 24 "reserved" 25 "reserved" 26 "reserved" 27 "reserved" 28 "reserved" 29 "reserved" 30 "reserved" 31 "Invalid" ;
VAL_ 849 IAU_NFCCard1SN 0 "0x0x00000000~0xFFFFFFFF:" 2147483647 "0x0x00000000~0xFFFFFFFF:" ;
VAL_ 849 IAU_FD_AlvCnt4Val 0 "0x0x0~0xFF:AlvCntValue" 255 "0x0x0~0xFF:AlvCntValue" ;
VAL_ 849 IAU_StartIdentifiedProfile_Ext 0 "Default" 1 "Profile1" 2 "Profile2" 3 "Profile3" 4 "Profile4" 5 "Profile5" 6 "Profile6" 7 "Profile7" 8 "Profile8" 9 "Profile9" 10 "RESERVED" 11 "RESERVED" 12 "RESERVED" 13 "RESERVED" 14 "RESERVED" 15 "INVALID" ;
VAL_ 849 RSPA_UWBRspaExtRngSta 0 "Initial" 1 "Out of range of RSPA remote control Region" 2 "In the range of RSPA remote control region" 3 "Reserved" ;
VAL_ 849 RSPA_CanFltSta 0 "Default" 1 "RSPA CAN Error" 2 "Not Used" 3 "Error Indicator" ;
VAL_ 849 RSPA_BLESigErrSta 0 "Default" 1 "Signal Invalid" 2 "In Progress" 3 "Error Indicator" ;
VAL_ 849 RSPA_ConStat 0 "Normal Status" 1 "Fail Status" 2 "Reserved" 3 "Reserved" ;
VAL_ 849 IAU_ProfileIDRVal 0 "Default" 1 "Guest" 2 "Profile1" 3 "Profile2" 4 "Profile3" 5 "Profile4" 6 "Profile5" 7 "Profile6" 8 "Profile7" 9 "Profile8" 10 "Profile9" 11 "RESERVED" 12 "RESERVED" 13 "RESERVED" 14 "RESERVED" 15 "INVALID" ;
VAL_ 849 IAU_DigitalKeyProcessingSta 0 "None" 1 "DeviceOnWPC" 2 "DeviceRegistering" 3 "PhoneRegistered" 4 "All Phone Key Deleted" 5 "NFCCard1Registered" 6 "Server Registering" 7 "NFCCard1Deleted" 8 "BLE Searching" 9 "Owner Phone key Deleted" 10 "Valet Off Searching" 11 "Server Registering Fail" 12 "All Digital Keys in group Deleted" 15 "Invalid" ;
VAL_ 849 IAU_DigitalKeyExit 0 "Normal" 1 "Check System" 2 "NFC Not Detected" 3 "Fob Not Detected" 4 "Canceled by User (Timeout)" 5 "Device not Available" 6 "ProcessFail" 7 "Check Card Save" 8 "Certificate Update" 9 "Valet Off Fail" 10 "CardNotAvailable" 11 "DigitalKeyDisabled" 12 "Retry After Parking" 13 "Check Password" 14 "P position fail (not P)" 15 "Invalid" ;
VAL_ 849 IAU_DigitalKeyEnblRVal 0 "Default" 1 "Disable" 2 "Enable" 3 "Invalid" ;
VAL_ 849 IAU_OwnerPhnRegRVal 0 "Default" 1 "Disable" 2 "Enable" 3 "Invalid" ;
VAL_ 849 IAU_NFCCard1RegRVal 0 "Default" 1 "Disable" 2 "Enable" 3 "Invalid" ;
VAL_ 849 IAU_NFCCard2RegRVal 0 "Default" 1 "Disable" 2 "Enable" 3 "Invalid" ;
VAL_ 850 IAU_FD_Crc5Val 0 "0x0x0~0xFFFF:CRCValue" 65535 "0x0x0~0xFFFF:CRCValue" ;
VAL_ 850 IAU_DigitalKeyProfileRval 0 "Default" 1 "1st digital key (owner)" 2 "2nd digital key" 3 "3rd digital key" 4 "4th digital key" 5 "5th digital key" 6 "6th digital key" 7 "7th digital key" 8 "8th digital key" 9 "reserved" 10 "reserved" 11 "reserved" 12 "reserved" 13 "reserved" 14 "reserved" 15 "Invalid" ;
VAL_ 850 IAU_SharedPhnRegStat 0 "Defautl (Not Exist)" 1 "Exist" 2 "Reserve" 3 "Invalid" ;
VAL_ 850 IAU_CardKeyEnblRVal 0 "Default" 1 "Disable" 2 "Enable" 3 "Invalid" ;
VAL_ 850 IAU_DrvDHLPhnDetect 0 "Default(Off)" 1 "On" 2 "Not used" 3 "Invalid" ;
VAL_ 850 IAU_AstDHLPhnDetect 0 "Default(Off)" 1 "On" 2 "Not used" 3 "Invalid" ;
VAL_ 850 IAU_RLDHLPhnDetect 0 "Default(Off)" 1 "On" 2 "Not used" 3 "Invalid" ;
VAL_ 850 IAU_RRDHLPhnDetect 0 "Defualt(Off)" 1 "On" 2 "Not used" 3 "Invalid" ;
VAL_ 850 IAU_Manufacturer 0 "0x0x00~0xFF:ASCII Code Value (HEX)" 255 "0x0x00~0xFF:ASCII Code Value (HEX)" ;
VAL_ 850 IAU_VendorCode 0 "0x0x000000~0xFFFFFF:ASCII Code Value (HEX)" 16777215 "0x0x000000~0xFFFFFF:ASCII Code Value (HEX)" ;
VAL_ 850 IAU_FD_AlvCnt5Val 0 "0x0x0~0xFF:AlvCntValue" 255 "0x0x0~0xFF:AlvCntValue" ;
VAL_ 850 IAU_Serial 0 "0x0x00000000~0xFFFFFFFF:ASCII Code Value (HEX)" 2147483647 "0x0x00000000~0xFFFFFFFF:ASCII Code Value (HEX)" ;
VAL_ 850 IAU_Year 0 "0x0x0000~0xFFFF:ASCII Code Value (HEX)" 65535 "0x0x0000~0xFFFF:ASCII Code Value (HEX)" ;
VAL_ 850 IAU_Month 0 "0x0x00~0xFF:ASCII Code Value (HEX)" 255 "0x0x00~0xFF:ASCII Code Value (HEX)" ;
VAL_ 850 IAU_Date 0 "0x0x0000~0xFFFF:ASCII Code Value (HEX)" 65535 "0x0x0000~0xFFFF:ASCII Code Value (HEX)" ;
VAL_ 850 IAU_SWVerMajor1 0 "0x0x0~0x7F:ASCII Code Value (HEX)" 127 "0x0x0~0x7F:ASCII Code Value (HEX)" ;
VAL_ 850 IAU_DrvDhsRainStat 0 "Off" 1 "Rain" ;
VAL_ 850 IAU_SWVerMinor1 0 "0x0x0~0x7F:ASCII Code Value (HEX)" 127 "0x0x0~0x7F:ASCII Code Value (HEX)" ;
VAL_ 850 IAU_SWVerMinor2 0 "0x0x0~0x7F:ASCII Code Value (HEX)" 127 "0x0x0~0x7F:ASCII Code Value (HEX)" ;
VAL_ 850 IAU_AstDhsRainStat 0 "Off" 1 "Rain" ;
VAL_ 850 IAU_RLDhsRainStat 0 "Off" 1 "Rain" ;
VAL_ 850 IAU_RRDhsRainStat 0 "Off" 1 "Rain" ;
VAL_ 2214592592 L_BDC_FD_IAU_Crc1Val 0 "0x0x0~0xFFFF:CRCValue" 65535 "0x0x0~0xFFFF:CRCValue" ;
VAL_ 2214592592 L_BDC_FD_IAU_AlvCnt1Val 0 "0x0x0~0xFF:AlvCntValue" 255 "0x0x0~0xFF:AlvCntValue" ;
VAL_ 2214592592 WPC_NFC_Deselect_Cmd 0 "Default" 1 "WPC NFC Polling (Search)" 2 "WPC NFC Deselect (Stop)" 3 "Invalid" ;
VAL_ 2214592592 WPC2_NFC_Deselect_Cmd 0 "Default" 1 "WPC2 NFC Polling (Search)" 2 "WPC2 NFC Deselect (Stop)" 3 "Invalid" ;
VAL_ 2214592592 DHL_NFC_Deselect_Cmd 0 "Default" 1 "NFC Polling (Search)" 2 "NFC Deselect (Stop)" 3 "Invalid" ;
VAL_ 2214592592 DHR_NFC_Deselect_Cmd 0 "Default" 1 "NFC Polling (Search)" 2 "NFC Deselect (Stop)" 3 "Invalid" ;
VAL_ 2214592592 DHRL_NFC_Deselect_Cmd 0 "Default" 1 "NFC Polling (Search)" 2 "NFC Deselect (Stop)" 3 "Invalid" ;
VAL_ 2214592592 DHRR_NFC_Deselect_Cmd 0 "Default" 1 "NFC Polling (Search)" 2 "NFC Deselect (Stop)" 3 "Invalid" ;
VAL_ 2281701456 L_BDC_FD_IAU_Crc10Val 0 "0x0x0~0xFFFF:CRCValue" 65535 "0x0x0~0xFFFF:CRCValue" ;
VAL_ 2281701456 L_BDC_FD_IAU_AlvCnt10Val 0 "0x0x0~0xFF:AlvCntValue" 255 "0x0x0~0xFF:AlvCntValue" ;
VAL_ 2281701456 BodyType_Sta 0 "Body Type 1" 1 "Body Type 2" 2 "Body Type 3" 3 "Body Type 4" 4 "Body Type 5" 5 "Body Type 6" 6 "Body Type 7" 7 "Body Type 8" ;
VAL_ 2281701456 Trunk_Tailgate_Info 0 "Trunk" 1 "Tailgate" 2 "RESERVED" 3 "Error Indicator" ;
VAL_ 2281701456 BDC_TP_CAN_Sta 0 "Idle" 1 "Process for WPC" 2 "Process for DHL" 3 "Process for DHR" 4 "Process for BLE_TRX" 5 "Process for DHRL" 6 "Process for DHRR" 7 "Process for BLE2_TRX" ;
VAL_ 2281701456 OPAdv_On_Cmd 0 "Default(Stop)" 1 "StartEnable" 2 "Reserve" 3 "Invalid" ;
VAL_ 2281701456 WPC_Device_On_Cmd 0 "Not key device" 1 "Phone key" 2 "Card key" 3 "Invaild" ;
VAL_ 2281701456 RgnTyp_Opt 0 "Domestic" 1 "General" 2 "MiddleEast" 3 "Europe" 4 "Australia" 5 "Canada" 6 "USA" 7 "China" 8 "India" 9 "Mexico" 10 "Brazil" 11 "Russia" 12 "Japan" 13 "RESERVED" 14 "RESERVED" 15 "RESERVED" ;
VAL_ 2281701456 SunRoofTyp_Opt 0 "NotApplied(Normal Roof)" 1 "Type1(Basic Sunroof)" 2 "Type2" 3 "Type3" 4 "RESERVED" 5 "RESERVED" 6 "RESERVED" 7 "Error Indicator" ;
VAL_ 2281701456 BDC_RSPA_DKID 0 "Default(Stop)" 1 "#1" 2 "#2" 3 "#3" 4 "#4" 5 "#5" 6 "#6" 7 "#7" 8 "#8" 9 "#9" 10 "#10" 11 "#11" 12 "#12" 13 "#13" 14 "#14" 15 "#15" 16 "#16" 17 "Reserve" 18 "Reserve" 19 "Reserve" 20 "Reserve" 21 "Reserve" 22 "Reserve" 23 "Reserve" 24 "Reserve" 25 "Reserve" 26 "Reserve" 27 "Reserve" 28 "Reserve" 29 "Reserve" 30 "Reserve" 31 "Invalid" ;
VAL_ 2214592624 L_WPC_FD_Crc1Val 0 "0x0x0~0xFFFF:CRCValue" 65535 "0x0x0~0xFFFF:CRCValue" ;
VAL_ 2214592624 L_WPC_FD_AlvCnt1Val 0 "0x0x0~0xFF:AlvCntValue" 255 "0x0x0~0xFF:AlvCntValue" ;
VAL_ 2214592624 WPC_NFCDetection_Sta 0 "Off" 1 "Detected" 2 "Not Detected" ;
VAL_ 2214592624 WPC_NFCReset_Sta 0 "Default" 1 "Reset Complete" ;
VAL_ 2214592624 WPC2_NFCDetection_Sta 0 "Off" 1 "Detected" 2 "Not Detected" ;
VAL_ 2214592624 WPC2_NFCReset_Sta 0 "Default" 1 "Reset Complete" ;
VAL_ 745 PDC_FD_Crc15Val 0 "0x0x0~0xFFFF:CRCValue" 65535 "0x0x0~0xFFFF:CRCValue" ;
VAL_ 745 PDC_CurrAtReset 0 "0x0x0~0xFFE:-40,940mA ~ 0mA" 4094 "0x0x0~0xFFE:-40,940mA ~ 0mA" 4095 "Error" ;
VAL_ 745 PDC_AvgCurrAtReset 0 "0x0x0~0xFFE:-40,940mA ~ 0mA" 4094 "0x0x0~0xFFE:-40,940mA ~ 0mA" 4095 "Error" ;
VAL_ 745 PDC_ResetReason 0 "No Reset" 1 "Reset By Non-Sleep" 2 "Reset By Current" 3 "RESERVED" 4 "RESERVED" 5 "RESERVED" 6 "RESERVED" 7 "RESERVED" ;
VAL_ 745 PDC_CumulativeCountOf12VReq 0 "0x0x0~0x3FF:0~1023" 1023 "0x0x0~0x3FF:0~1023" ;
VAL_ 745 PDC_CumulativeCountOfCCUReq 0 "0x0x0~0x3FF:0~1023" 1023 "0x0x0~0x3FF:0~1023" ;
VAL_ 745 PDC_FD_AlvCnt15Val 0 "0x0x0~0xFF:AlvCntValue" 255 "0x0x0~0xFF:AlvCntValue" ;
VAL_ 745 PDC_LDConReq 0 "Off (Default)" 1 "On" 2 "RESERVED" 3 "RESERVED" ;
VAL_ 745 PDC_LDConReq_By_LVBat 0 "Off (Default)" 1 "On" 2 "RESERVED" 3 "RESERVED" ;
VAL_ 745 PDC_LDConReq_By_OTA 0 "Off (Default)" 1 "On" 2 "RESERVED" 3 "RESERVED" ;
VAL_ 745 PDC_LDConReq_By_Load 0 "Off (Default)" 1 "On" 2 "RESERVED" 3 "RESERVED" ;
VAL_ 745 PDC_LDConReq_By_ActiveOn 0 "Off (Default)" 1 "On" 2 "RESERVED" 3 "RESERVED" ;
VAL_ 745 PDC_ResetPreWrngForCCU 0 "No Warning" 1 "Warning" 2 "RESERVED" 3 "Invalid" ;
VAL_ 745 PDC_ResetPreWrngForOthers 0 "No Warning" 1 "Warning" 2 "RESERVED" 3 "Invalid" ;
VAL_ 745 PDC_ResetReqForCCU 0 "No Requeset" 1 "Reset Requeset" 2 "RESERVED" 3 "Invalid" ;
VAL_ 745 PDC_ResetReqForOthers 0 "No Requeset" 1 "Reset Requeset" 2 "RESERVED" 3 "Invalid" ;
VAL_ 745 PDC_ResetFuncOpt 0 "Not Applied" 1 "Applied" 2 "RESERVED" 3 "Invalid" ;
VAL_ 745 PDC_12VRlyCtrl 0 "No Request" 1 "Relay On request" 2 "Relay Off request" 3 "Invalid" ;
VAL_ 745 PDC_CurrentValueForReset 0 "No Setting" 1 "0x1~0xFE:50mA ~ 12700mA" 254 "0x1~0xFE:50mA ~ 12700mA" 255 "Invalid" ;
VAL_ 745 PDC_TimeValueForReset 0 "No Setting" 1 "0x1~0xFE:0.5h ~ 127h" 254 "0x1~0xFE:0.5h ~ 127h" 255 "Invalid" ;
VAL_ 745 PDC_12VRlyOffHoldingTime 0 "No Setting" 1 "0.5s ~ 15s" 2 "0.5s ~ 15s" 3 "0.5s ~ 15s" 4 "0.5s ~ 15s" 5 "0.5s ~ 15s" 6 "0.5s ~ 15s" 7 "0.5s ~ 15s" 8 "0.5s ~ 15s" 9 "0.5s ~ 15s" 10 "0.5s ~ 15s" 11 "0.5s ~ 15s" 12 "0.5s ~ 15s" 13 "0.5s ~ 15s" 14 "0.5s ~ 15s" 15 "0.5s ~ 15s" 16 "0.5s ~ 15s" 17 "0.5s ~ 15s" 18 "0.5s ~ 15s" 19 "0.5s ~ 15s" 20 "0.5s ~ 15s" 21 "0.5s ~ 15s" 22 "0.5s ~ 15s" 23 "0.5s ~ 15s" 24 "0.5s ~ 15s" 25 "0.5s ~ 15s" 26 "0.5s ~ 15s" 27 "0.5s ~ 15s" 28 "0.5s ~ 15s" 29 "0.5s ~ 15s" 30 "0.5s ~ 15s" 31 "Invalid" ;
VAL_ 745 PDC_ResetCountSetting 0 "No Setting" 1 "1~3" 2 "1~3" 3 "1~3" ;
VAL_ 745 PDC_ResetCount 0 "No Setting" 1 "1~3" 2 "1~3" 3 "1~3" ;
VAL_ 745 PDC_ResetCumulativeCount 0 "0x0x0~0x3FF:0~1023" 1023 "0x0x0~0x3FF:0~1023" ;
VAL_ 745 PDC_ResetOpsta 0 "Normal" 1 "Reset Complete" 2 "Reset Fail" 3 "RESERVED" ;
VAL_ 745 PDC_ReadyTimeValueForReset 0 "No Setting" 1 "0x1~0xFE:10min~254min/0XFF: Invalid" 254 "0x1~0xFE:10min~254min/0XFF: Invalid" ;
